VERSION "dbc-export 1 2026.26.6.5"

NS_ :

BS_:

BU_: APP APS BMS CC CMP CMPD CP DAS DI DIF DIR EPBL EPBR EVSE FC GTW HCML HCMR HVP ICR PCS PCS2 PLG PM PMF PMR PTC SCCM SCM SCS SDCR TAS UMC V2G VC VCBATT VCBATT0 VCBATT1 VCBATT2 VCFRONT VCFRONT1 VCFRONT2 VCLEFT VCRIGHT VCSEAT2L VCSEAT2R VCSEC

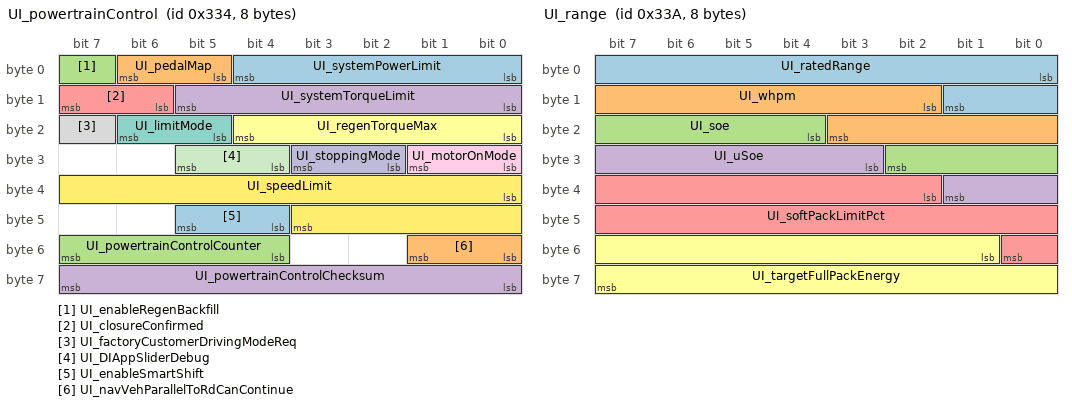
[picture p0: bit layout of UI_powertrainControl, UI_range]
BO_ 820 UI_powertrainControl: 8 GTW
 SG_ UI_systemPowerLimit : 0|5@1+ (20,20) [20|620] "kW" Vector__XXX
 SG_ UI_pedalMap : 5|2@1+ (1,0) [0|3] "" Vector__XXX
 SG_ UI_enableRegenBackfill : 7|1@1+ (1,0) [0|1] "" Vector__XXX
 SG_ UI_systemTorqueLimit : 8|6@1+ (150,1000) [1000|10300] "Nm" Vector__XXX
 SG_ UI_closureConfirmed : 14|2@1+ (1,0) [0|3] "" Vector__XXX
 SG_ UI_regenTorqueMax : 16|5@1+ (5,0) [0|100] "%" Vector__XXX
 SG_ UI_limitMode : 21|2@1+ (1,0) [0|3] "" Vector__XXX
 SG_ UI_factoryCustomerDrivingModeReq : 23|1@1+ (1,0) [0|1] "" Vector__XXX
 SG_ UI_motorOnMode : 24|2@1+ (1,0) [0|3] "" Vector__XXX
 SG_ UI_stoppingMode : 26|2@1+ (1,0) [0|3] "" Vector__XXX
 SG_ UI_DIAppSliderDebug : 28|2@1+ (1,0) [0|3] "" Vector__XXX
 SG_ UI_speedLimit : 32|12@1+ (0.1,0) [0|335] "kph" Vector__XXX
 SG_ UI_enableSmartShift : 44|2@1+ (1,0) [0|3] "" Vector__XXX
 SG_ UI_navVehParallelToRdCanContinue : 48|2@1+ (1,0) [1|3] "" Vector__XXX
 SG_ UI_powertrainControlCounter : 52|4@1+ (1,0) [0|15] "" Vector__XXX
 SG_ UI_powertrainControlChecksum : 56|8@1+ (1,0) [0|255] "" Vector__XXX

BO_ 826 UI_range: 8 GTW
 SG_ UI_ratedRange : 0|10@1+ (1,0) [0|1023] "mi" Vector__XXX
 SG_ UI_whpm : 10|10@1+ (1,0) [0|1023] "" Vector__XXX
 SG_ UI_soe : 20|7@1+ (1,0) [0|127] "%" Vector__XXX
 SG_ UI_uSoe : 27|7@1+ (1,0) [0|127] "%" Vector__XXX
 SG_ UI_softPackLimitPct : 34|15@1+ (0.003051851,0) [0|100.000001717] "%" Vector__XXX
 SG_ UI_targetFullPackEnergy : 49|15@1+ (0.006103702,0) [0|200.000003434] "kWh" Vector__XXX

BO_ 666 UI_seatControl: 3 GTW
 SG_ UI_seatControlIndex M : 0|2@1+ (1,0) [0|3] "" Vector__XXX
 SG_ UI_3RSeatChildLock m0 : 2|2@1+ (1,0) [0|3] "" Vector__XXX
 SG_ UI_2RowLeftSeatTrackBack m0 : 4|1@1+ (1,0) [0|1] "" Vector__XXX
 SG_ UI_2RowLeftSeatTrackForward m0 : 5|1@1+ (1,0) [0|1] "" Vector__XXX
 SG_ UI_2RowRightSeatTrackBack m0 : 6|1@1+ (1,0) [0|1] "" Vector__XXX
 SG_ UI_2RowRightSeatTrackForward m0 : 7|1@1+ (1,0) [0|1] "" Vector__XXX
 SG_ UI_left3RowSeatAdjustmentRequest m0 : 8|3@1+ (1,0) [0|7] "" Vector__XXX
 SG_ UI_right3RowSeatAdjustmentReques m0 : 11|3@1+ (1,0) [0|7] "" Vector__XXX
 SG_ UI_2RLeftSeatFanReq m0 : 14|2@1+ (1,0) [0|3] "" Vector__XXX
 SG_ UI_2RRightSeatFanReq m0 : 16|2@1+ (1,0) [0|3] "" Vector__XXX
 SG_ UI_leftThirdRowSeatRequestFromRe m0 : 18|1@1+ (1,0) [0|1] "" Vector__XXX
 SG_ UI_rightThirdRowSeatRequestFromR m0 : 19|1@1+ (1,0) [0|1] "" Vector__XXX
 SG_ UI_seatChoreographyStopRequest m0 : 20|1@1+ (1,0) [0|1] "" Vector__XXX

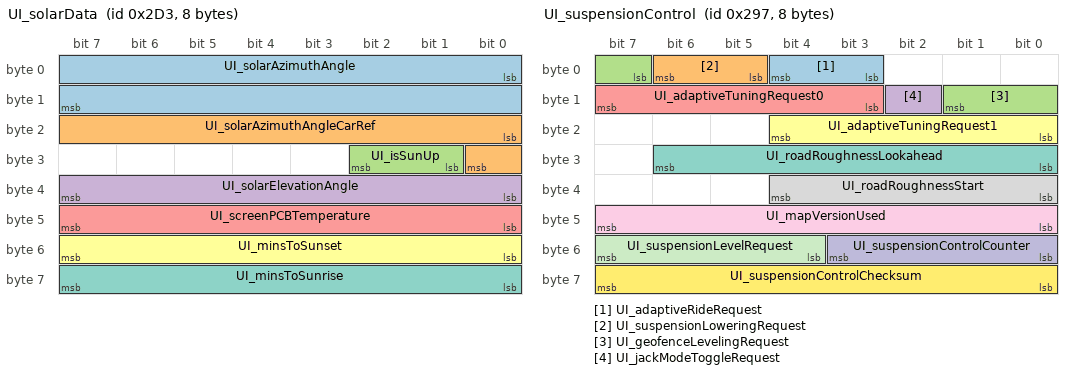
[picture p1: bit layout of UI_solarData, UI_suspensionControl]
BO_ 723 UI_solarData: 8 GTW
 SG_ UI_solarAzimuthAngle : 0|16@1- (1,0) [-32768|32767] "degrees" Vector__XXX
 SG_ UI_solarAzimuthAngleCarRef : 16|9@1- (1,0) [-256|254] "degrees" Vector__XXX
 SG_ UI_isSunUp : 25|2@1+ (1,0) [0|2] "" Vector__XXX
 SG_ UI_solarElevationAngle : 32|8@1- (1,0) [-128|126] "degrees" Vector__XXX
 SG_ UI_screenPCBTemperature : 40|8@1- (0.5,40) [-20|100] "degC" Vector__XXX
 SG_ UI_minsToSunset : 48|8@1+ (10,0) [0|2550] "min" Vector__XXX
 SG_ UI_minsToSunrise : 56|8@1+ (10,0) [0|2550] "min" Vector__XXX

BO_ 851 UI_status: 8 GTW
 SG_ UI_touchActive : 0|1@1+ (1,0) [0|1] "" Vector__XXX
 SG_ UI_audioActive : 1|1@1+ (1,0) [0|1] "" Vector__XXX
 SG_ UI_bluetoothActive : 2|1@1+ (1,0) [0|1] "" Vector__XXX
 SG_ UI_cellActive : 3|1@1+ (1,0) [0|1] "" Vector__XXX
 SG_ UI_displayReady : 4|1@1+ (1,0) [0|1] "" Vector__XXX
 SG_ UI_displayOn : 5|1@1+ (1,0) [0|1] "" Vector__XXX
 SG_ UI_wifiActive : 6|1@1+ (1,0) [0|1] "" Vector__XXX
 SG_ UI_wifiConnected : 7|1@1+ (1,0) [0|1] "" Vector__XXX
 SG_ UI_systemActive : 8|1@1+ (1,0) [0|1] "" Vector__XXX
 SG_ UI_readyForDrive : 9|1@1+ (1,0) [0|1] "" Vector__XXX
 SG_ UI_cellConnected : 10|1@1+ (1,0) [0|1] "" Vector__XXX
 SG_ UI_vpnActive : 11|1@1+ (1,0) [0|1] "" Vector__XXX
 SG_ UI_autopilotTrial : 12|2@1+ (1,0) [0|3] "" Vector__XXX
 SG_ UI_factoryReset : 14|2@1+ (1,0) [1|3] "" Vector__XXX
 SG_ UI_gpsActive : 16|1@1+ (1,0) [0|1] "" Vector__XXX
 SG_ UI_screenshotActive : 17|1@1+ (1,0) [0|1] "" Vector__XXX
 SG_ UI_radioActive : 18|1@1+ (1,0) [0|1] "" Vector__XXX
 SG_ UI_cellNetworkTechnology : 19|4@1+ (1,0) [0|14] "" Vector__XXX
 SG_ UI_cellReceiverPower : 24|8@1+ (1,-128) [-128|127] "dB" Vector__XXX
 SG_ UI_falseTouchCounter : 32|8@1+ (1,0) [0|255] "1" Vector__XXX
 SG_ UI_developmentCar : 40|1@1+ (1,0) [0|1] "" Vector__XXX
 SG_ UI_cameraActive : 41|1@1+ (1,0) [0|1] "" Vector__XXX
 SG_ UI_cellSignalBars : 42|3@1+ (1,0) [0|6] "" Vector__XXX
 SG_ UI_trailerModeTelltale : 45|2@1+ (1,0) [0|3] "" Vector__XXX
 SG_ UI_pcbTemperature : 48|8@1- (1,40) [-20|100] "degC" Vector__XXX
 SG_ UI_cpuTemperature : 56|8@1- (1,40) [-20|100] "degC" Vector__XXX

BO_ 991 UI_status2: 8 GTW
 SG_ UI_mobileAppStepCount : 0|16@1+ (1,0) [0|65535] "" Vector__XXX
 SG_ UI_userRequestSnapshot : 16|1@1+ (1,0) [0|1] "" Vector__XXX
 SG_ UI_touchDetected : 17|1@1+ (1,0) [0|1] "" Vector__XXX
 SG_ UI_validDeviceForEUSummon : 18|1@1+ (1,0) [0|1] "" Vector__XXX
 SG_ UI_locatedAtHome : 19|1@1+ (1,0) [0|1] "" Vector__XXX
 SG_ UI_locatedAtWork : 20|1@1+ (1,0) [0|1] "" Vector__XXX
 SG_ UI_locatedAtFavorite : 21|1@1+ (1,0) [0|1] "" Vector__XXX
 SG_ UI_displayInDarkMode : 22|1@1+ (1,0) [0|1] "" Vector__XXX
 SG_ UI_userActivity : 23|1@1+ (1,0) [0|1] "" Vector__XXX
 SG_ UI_activeTouchPoints : 24|8@1+ (1,0) [0|255] "1" Vector__XXX
 SG_ UI_linkState : 32|2@1+ (1,0) [0|3] "" Vector__XXX
 SG_ UI_sentryModeState : 34|3@1+ (1,0) [0|7] "" Vector__XXX
 SG_ UI_autopilotSentryRequest : 37|1@1+ (1,0) [0|1] "" Vector__XXX
 SG_ UI_mobileAppConnected : 38|1@1+ (1,0) [0|1] "" Vector__XXX
 SG_ UI_phoneLeftInCabin : 39|1@1+ (1,0) [0|1] "" Vector__XXX
 SG_ UI_autoshiftDRState : 40|3@1+ (1,0) [0|7] "" Vector__XXX
 SG_ UI_wifiBtModuleType : 43|3@1+ (1,0) [0|7] "" Vector__XXX
 SG_ UI_sohHealthStatus : 46|2@1+ (1,0) [0|3] "" Vector__XXX
 SG_ UI_selfParkState : 48|8@1+ (1,0) [0|254] "" Vector__XXX
 SG_ UI_summonDeviceIndex : 56|2@1+ (1,0) [0|3] "" Vector__XXX
 SG_ UI_fullScreenMode : 58|1@1+ (1,0) [0|1] "" Vector__XXX
 SG_ UI_sentryModeCameraDetection : 59|1@1+ (1,0) [0|1] "" Vector__XXX
 SG_ UI_wakeOnIPActive : 60|1@1+ (1,0) [0|1] "" Vector__XXX
 SG_ UI_sapActive : 61|1@1+ (1,0) [0|1] "" Vector__XXX
 SG_ UI_sapClients : 62|1@1+ (1,0) [0|1] "" Vector__XXX
 SG_ UI_connectivityStandbyActive : 63|1@1+ (1,0) [0|1] "" Vector__XXX

BO_ 663 UI_suspensionControl: 8 GTW
 SG_ UI_adaptiveRideRequest : 3|2@1+ (1,0) [0|3] "" Vector__XXX
 SG_ UI_suspensionLoweringRequest : 5|2@1+ (1,0) [0|2] "" Vector__XXX
 SG_ UI_geofenceLevelingRequest : 7|3@1+ (1,0) [0|7] "" Vector__XXX
 SG_ UI_jackModeToggleRequest : 10|1@1+ (1,0) [0|1] "" Vector__XXX
 SG_ UI_adaptiveTuningRequest0 : 11|5@1- (0.1,0) [-1.6|1.5] "-" Vector__XXX
 SG_ UI_adaptiveTuningRequest1 : 16|5@1- (0.1,0) [-1.6|1.5] "-" Vector__XXX
 SG_ UI_roadRoughnessLookahead : 24|7@1+ (0.01,0) [0|1.26] "%" Vector__XXX
 SG_ UI_roadRoughnessStart : 32|5@1+ (10,0) [0|300] "m" Vector__XXX
 SG_ UI_mapVersionUsed : 40|8@1+ (1,0) [0|254] "-" Vector__XXX
 SG_ UI_suspensionControlCounter : 48|4@1+ (1,0) [0|15] "" Vector__XXX
 SG_ UI_suspensionLevelRequest : 52|4@1+ (1,0) [0|15] "" Vector__XXX
 SG_ UI_suspensionControlChecksum : 56|8@1+ (1,0) [0|255] "" Vector__XXX

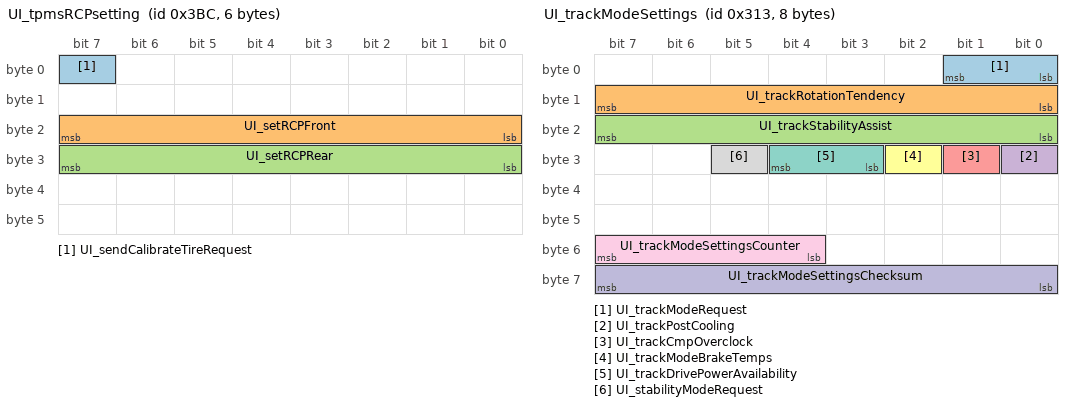
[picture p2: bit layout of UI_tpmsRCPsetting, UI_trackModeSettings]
BO_ 956 UI_tpmsRCPsetting: 6 GTW
 SG_ UI_sendCalibrateTireRequest : 7|1@1+ (1,0) [0|1] "" Vector__XXX
 SG_ UI_setRCPFront : 16|8@1+ (0.025,0) [0|6.375] "bar" Vector__XXX
 SG_ UI_setRCPRear : 24|8@1+ (0.025,0) [0|6.375] "bar" Vector__XXX

BO_ 787 UI_trackModeSettings: 8 GTW
 SG_ UI_trackModeRequest : 0|2@1+ (1,0) [0|3] "" Vector__XXX
 SG_ UI_trackRotationTendency : 8|8@1+ (0.5,0) [0|127.5] "%" Vector__XXX
 SG_ UI_trackStabilityAssist : 16|8@1+ (0.5,0) [0|127.5] "%" Vector__XXX
 SG_ UI_trackPostCooling : 24|1@1+ (1,0) [0|1] "" Vector__XXX
 SG_ UI_trackCmpOverclock : 25|1@1+ (1,0) [0|1] "" Vector__XXX
 SG_ UI_trackModeBrakeTemps : 26|1@1+ (1,0) [0|1] "" Vector__XXX
 SG_ UI_trackDrivePowerAvailability : 27|2@1+ (1,0) [0|3] "" Vector__XXX
 SG_ UI_stabilityModeRequest : 29|1@1+ (1,0) [0|1] "" Vector__XXX
 SG_ UI_trackModeSettingsCounter : 52|4@1+ (1,0) [0|15] "" Vector__XXX
 SG_ UI_trackModeSettingsChecksum : 56|8@1+ (1,0) [0|255] "" Vector__XXX

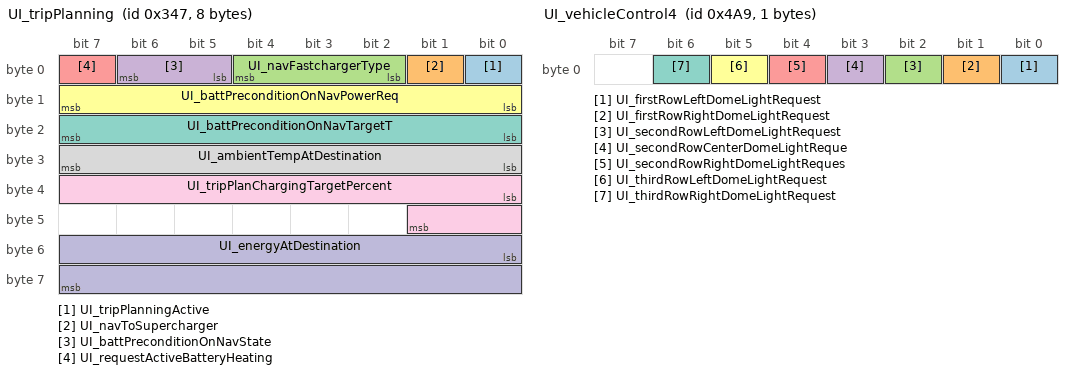
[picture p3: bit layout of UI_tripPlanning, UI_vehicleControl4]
BO_ 839 UI_tripPlanning: 8 GTW
 SG_ UI_tripPlanningActive : 0|1@1+ (1,0) [0|1] "" Vector__XXX
 SG_ UI_navToSupercharger : 1|1@1+ (1,0) [0|1] "" Vector__XXX
 SG_ UI_navFastchargerType : 2|3@1+ (1,0) [0|7] "" Vector__XXX
 SG_ UI_battPreconditionOnNavState : 5|2@1+ (1,0) [0|3] "" Vector__XXX
 SG_ UI_requestActiveBatteryHeating : 7|1@1+ (1,0) [0|1] "" Vector__XXX
 SG_ UI_battPreconditionOnNavPowerReq : 8|8@1- (125,0) [-16000|15750] "W" Vector__XXX
 SG_ UI_battPreconditionOnNavTargetT : 16|8@1+ (0.25,0) [0|63.5] "degC" Vector__XXX
 SG_ UI_ambientTempAtDestination : 24|8@1- (0.5,0) [-64|63.5] "degC" Vector__XXX
 SG_ UI_tripPlanChargingTargetPercent : 32|10@1+ (0.1,0) [0|102.2] "%" Vector__XXX
 SG_ UI_energyAtDestination : 48|16@1- (0.01,0) [-327.67|327.67] "kWh" Vector__XXX

BO_ 627 UI_vehicleControl: 8 GTW
 SG_ UI_powerStateRequest : 0|2@1+ (1,0) [0|3] "" Vector__XXX
 SG_ UI_childDoorLockOnRight : 2|1@1+ (1,0) [0|1] "" Vector__XXX
 SG_ UI_frontFogSwitch : 3|1@1+ (1,0) [0|1] "" Vector__XXX
 SG_ UI_summonActive : 4|1@1+ (1,0) [0|1] "" Vector__XXX
 SG_ UI_frunkRequest : 5|1@1+ (1,0) [0|1] "" Vector__XXX
 SG_ UI_wiperMode : 6|2@1+ (1,0) [1|3] "" Vector__XXX
 SG_ UI_steeringBacklightEnabled : 8|1@1+ (1,0) [0|1] "" Vector__XXX
 SG_ UI_steeringButtonMode : 9|3@1+ (1,0) [0|7] "" Vector__XXX
 SG_ UI_walkUpUnlock : 12|1@1+ (1,0) [0|1] "" Vector__XXX
 SG_ UI_walkAwayLock : 13|1@1+ (1,0) [0|1] "" Vector__XXX
 SG_ UI_unlockOnPark : 14|1@1+ (1,0) [0|1] "" Vector__XXX
 SG_ UI_globalUnlockOn : 15|1@1+ (1,0) [0|1] "" Vector__XXX
 SG_ UI_childDoorLockOnLeft : 16|1@1+ (1,0) [0|1] "" Vector__XXX
 SG_ UI_lockRequest : 17|3@1+ (1,0) [0|6] "" Vector__XXX
 SG_ UI_alarmEnabled : 20|1@1+ (1,0) [0|1] "" Vector__XXX
 SG_ UI_intrusionSensorOn : 21|1@1+ (1,0) [0|1] "" Vector__XXX
 SG_ UI_stop12vSupport : 22|1@1+ (1,0) [0|1] "" Vector__XXX
 SG_ UI_rearFogSwitch : 23|1@1+ (1,0) [0|1] "" Vector__XXX
 SG_ UI_mirrorFoldRequest : 24|2@1+ (1,0) [0|2] "" Vector__XXX
 SG_ UI_mirrorHeatRequest : 26|1@1+ (1,0) [0|1] "" Vector__XXX
 SG_ UI_remoteStartRequest : 27|3@1+ (1,0) [0|7] "" Vector__XXX
 SG_ UI_seeYouHomeLightingOn : 30|1@1+ (1,0) [0|1] "" Vector__XXX
 SG_ UI_powerOff : 31|1@1+ (1,0) [0|1] "" Vector__XXX
 SG_ UI_displayBrightnessLevel : 32|8@1+ (0.5,0) [0|127] "%" Vector__XXX
 SG_ UI_ambientLightingEnabled : 40|1@1+ (1,0) [0|1] "" Vector__XXX
 SG_ UI_autoHighBeamEnabled : 41|1@1+ (1,0) [0|1] "" Vector__XXX
 SG_ UI_frontLeftSeatHeatReq : 42|2@1+ (1,0) [0|3] "" Vector__XXX
 SG_ UI_frontRightSeatHeatReq : 44|2@1+ (1,0) [0|3] "" Vector__XXX
 SG_ UI_rearLeftSeatHeatReq : 46|2@1+ (1,0) [0|3] "" Vector__XXX
 SG_ UI_rearCenterSeatHeatReq : 48|2@1+ (1,0) [0|3] "" Vector__XXX
 SG_ UI_rearRightSeatHeatReq : 50|2@1+ (1,0) [0|3] "" Vector__XXX
 SG_ UI_autoFoldMirrorsOn : 52|1@1+ (1,0) [0|1] "" Vector__XXX
 SG_ UI_mirrorDipOnReverse : 53|1@1+ (1,0) [0|1] "" Vector__XXX
 SG_ UI_remoteClosureRequest : 54|2@1+ (1,0) [0|2] "" Vector__XXX
 SG_ UI_wiperRequest : 56|3@1+ (1,0) [1|7] "" Vector__XXX
 SG_ UI_domeLightSwitch : 59|2@1+ (1,0) [0|3] "" Vector__XXX
 SG_ UI_honkHorn : 61|1@1+ (1,0) [0|1] "" Vector__XXX
 SG_ UI_driveStateRequest : 62|1@1+ (1,0) [0|1] "" Vector__XXX
 SG_ UI_rearWindowLockout : 63|1@1+ (1,0) [0|1] "" Vector__XXX

BO_ 947 UI_vehicleControl2: 8 GTW
 SG_ UI_gloveboxRequest : 0|1@1+ (1,0) [0|1] "" Vector__XXX
 SG_ UI_trunkRequest : 1|1@1+ (1,0) [0|1] "" Vector__XXX
 SG_ UI_UMCUpdateInhibit : 2|1@1+ (1,0) [0|1] "" Vector__XXX
 SG_ UI_WCUpdateInhibit : 3|1@1+ (1,0) [0|1] "" Vector__XXX
 SG_ UI_soundHornOnLock : 4|1@1+ (1,0) [0|1] "" Vector__XXX
 SG_ UI_locksPanelActive : 5|1@1+ (1,0) [0|1] "" Vector__XXX
 SG_ UI_PINToDriveEnabled : 6|1@1+ (1,0) [0|1] "" Vector__XXX
 SG_ UI_PINToDrivePassed : 7|1@1+ (1,0) [0|1] "" Vector__XXX
 SG_ UI_disableMirrorAutoDim : 8|1@1+ (1,0) [0|1] "" Vector__XXX
 SG_ UI_lightSwitch : 9|3@1+ (1,0) [0|7] "" Vector__XXX
 SG_ UI_readyToAddKey : 12|1@1+ (1,0) [0|1] "" Vector__XXX
 SG_ UI_alarmTriggerRequest : 13|1@1+ (1,0) [0|1] "" Vector__XXX
 SG_ UI_VCSECFeature1 : 14|1@1+ (1,0) [0|1] "" Vector__XXX
 SG_ UI_VCLEFTFeature1 : 15|1@1+ (1,0) [0|1] "" Vector__XXX
 SG_ UI_summonState : 16|2@1+ (1,0) [1|3] "" Vector__XXX
 SG_ UI_displayOnForUser : 18|1@1+ (1,0) [0|1] "" Vector__XXX
 SG_ UI_freeRollModeRequest : 19|1@1+ (1,0) [0|1] "" Vector__XXX
 SG_ UI_BLEPushNotificationRequest : 20|1@1+ (1,0) [0|1] "" Vector__XXX
 SG_ UI_pairKeyQRCodeDisplaying : 21|1@1+ (1,0) [0|1] "" Vector__XXX
 SG_ UI_keepAutopilotAwake : 22|1@1+ (1,0) [0|1] "" Vector__XXX
 SG_ UI_batteryPreconditioningRequest : 23|1@1+ (1,0) [0|1] "" Vector__XXX
 SG_ UI_coastDownMode : 24|1@1+ (1,0) [0|1] "" Vector__XXX
 SG_ UI_autopilotPowerStateRequest : 25|2@1+ (1,0) [0|3] "" Vector__XXX
 SG_ UI_shorted12VCellTestMode : 27|2@1+ (1,0) [0|3] "" Vector__XXX
 SG_ UI_autoRollWindowsOnLockEnable : 29|1@1+ (1,0) [0|1] "" Vector__XXX
 SG_ UI_virtualPitchSensorOverrideOKF : 30|1@1+ (1,0) [0|1] "" Vector__XXX
 SG_ UI_conditionalLoggingEnabledVCSE : 31|1@1+ (1,0) [0|1] "" Vector__XXX
 SG_ UI_WC3UpdateInhibit : 32|1@1+ (1,0) [0|1] "" Vector__XXX
 SG_ UI_steeringWheelHeatReq : 33|1@1+ (1,0) [0|1] "" Vector__XXX
 SG_ UI_disableHorn : 34|1@1+ (1,0) [0|1] "" Vector__XXX
 SG_ UI_frontLeftSeatFanReq : 37|2@1+ (1,0) [0|3] "" Vector__XXX
 SG_ UI_frontRightSeatAutoClimateReq : 39|1@1+ (1,0) [0|1] "" Vector__XXX
 SG_ UI_frontRightSeatFanReq : 40|2@1+ (1,0) [0|3] "" Vector__XXX
 SG_ UI_3RLeftSeatHeatReq : 44|2@1+ (1,0) [0|3] "" Vector__XXX
 SG_ UI_3RRightSeatHeatReq : 46|2@1+ (1,0) [0|3] "" Vector__XXX
 SG_ UI_sleepFeature1 : 51|1@1+ (1,0) [0|1] "" Vector__XXX
 SG_ UI_dcr12VThreshold : 52|4@1+ (1,0) [0|15] "" Vector__XXX
 SG_ UI_frontLeftSeatAutoClimateReq : 56|1@1+ (1,0) [0|1] "" Vector__XXX
 SG_ UI_wiperHeaterReq : 57|1@1+ (1,0) [0|1] "" Vector__XXX
 SG_ UI_tireSeason : 59|1@1+ (1,0) [0|1] "" Vector__XXX
 SG_ UI_saveTireConfigReq : 60|1@1+ (1,0) [0|1] "" Vector__XXX
 SG_ UI_silentAlarm : 61|1@1+ (1,0) [0|1] "" Vector__XXX
 SG_ UI_sleepFeature2 : 63|1@1+ (1,0) [0|1] "" Vector__XXX

BO_ 660 UI_vehicleControl3: 8 GTW
 SG_ UI_lightFlashRequest : 0|2@1+ (1,0) [0|3] "" Vector__XXX
 SG_ UI_keylessDrivingEnabled : 2|1@1+ (1,0) [0|1] "" Vector__XXX
 SG_ UI_phoneCallActive : 3|1@1+ (1,0) [0|1] "" Vector__XXX
 SG_ UI_drivingSideVEH : 4|2@1+ (1,0) [0|3] "" Vector__XXX
 SG_ UI_keyPairResponse : 6|2@1+ (1,0) [0|3] "" Vector__XXX
 SG_ UI_lightShowClosuresEnabled : 8|1@1+ (1,0) [0|1] "" Vector__XXX
 SG_ UI_steeringWheelHeatAutoReq : 9|1@1+ (1,0) [0|1] "" Vector__XXX
 SG_ UI_steeringWheelHeatLevelReq : 10|2@1+ (1,0) [0|3] "" Vector__XXX
 SG_ UI_headlightPulseRequest : 12|1@1+ (1,0) [0|1] "" Vector__XXX
 SG_ UI_VCSECFeature2 : 13|1@1+ (1,0) [0|1] "" Vector__XXX
 SG_ UI_VCSECFeature3 : 14|1@1+ (1,0) [0|1] "" Vector__XXX
 SG_ UI_VCSECFeature4 : 15|1@1+ (1,0) [0|1] "" Vector__XXX
 SG_ UI_VCSECFeature5 : 16|1@1+ (1,0) [0|1] "" Vector__XXX
 SG_ UI_shortHornRequest : 17|1@1+ (1,0) [0|1] "" Vector__XXX
 SG_ UI_packTempLoggingRequest : 18|1@1+ (1,0) [0|1] "" Vector__XXX
 SG_ UI_UMC3UpdateInhibit : 22|1@1+ (1,0) [0|1] "" Vector__XXX
 SG_ UI_handsFreeTrunk : 23|1@1+ (1,0) [0|1] "" Vector__XXX
 SG_ UI_displayRedShiftActive : 24|1@1+ (1,0) [0|1] "" Vector__XXX
 SG_ UI_handsFreeFrunk : 25|1@1+ (1,0) [0|1] "" Vector__XXX
 SG_ UI_fasciaCameraWashRequest : 26|1@1+ (1,0) [0|1] "" Vector__XXX
 SG_ UI_autoClosuresExcludeHome : 27|1@1+ (1,0) [0|1] "" Vector__XXX
 SG_ UI_leftRearSeatAdjustmentRequest : 28|3@1+ (1,0) [0|7] "" Vector__XXX
 SG_ UI_rightRearSeatAdjustmentReques : 32|3@1+ (1,0) [0|7] "" Vector__XXX
 SG_ UI_blindSpotIndicatorLightReques : 35|1@1+ (1,0) [0|1] "" Vector__XXX
 SG_ UI_etcBluetoothControl : 36|2@1+ (1,0) [0|3] "" Vector__XXX
 SG_ UI_keepOnAccessoryPortsReq : 38|1@1+ (1,0) [0|1] "" Vector__XXX
 SG_ UI_fasciaCameraShown : 39|1@1+ (1,0) [0|1] "" Vector__XXX
 SG_ UI_rearSeatChildLock : 40|2@1+ (1,0) [0|3] "" Vector__XXX
 SG_ UI_windowPercentageRequest : 42|6@1- (5,0) [-100|100] "%" Vector__XXX
 SG_ UI_windowRequestedFL : 48|1@1+ (1,0) [0|1] "" Vector__XXX
 SG_ UI_windowRequestedFR : 49|1@1+ (1,0) [0|1] "" Vector__XXX
 SG_ UI_windowRequestedRL : 50|1@1+ (1,0) [0|1] "" Vector__XXX
 SG_ UI_windowRequestedRR : 51|1@1+ (1,0) [0|1] "" Vector__XXX
 SG_ UI_windowRequest : 52|3@1+ (1,0) [0|7] "" Vector__XXX
 SG_ UI_closeTrunkRequest : 55|1@1+ (1,0) [0|1] "" Vector__XXX
 SG_ UI_childPresenceDetectionDisable : 56|1@1+ (1,0) [0|1] "" Vector__XXX
 SG_ UI_V2LAUpdateInhibit : 57|1@1+ (1,0) [0|1] "" Vector__XXX
 SG_ UI_userPresenceDetectionEnabled : 58|1@1+ (1,0) [0|1] "" Vector__XXX
 SG_ UI_derivedLoadshedFeature : 59|1@1+ (1,0) [0|1] "" Vector__XXX
 SG_ UI_rearSeatFoldConfirmed : 60|1@1+ (1,0) [0|1] "" Vector__XXX
 SG_ UI_leftRearSeatRequestFromRearDi : 61|1@1+ (1,0) [0|1] "" Vector__XXX
 SG_ UI_selfParkStandingBy : 62|1@1+ (1,0) [0|1] "" Vector__XXX
 SG_ UI_rightRearSeatRequestFromRearD : 63|1@1+ (1,0) [0|1] "" Vector__XXX

BO_ 1193 UI_vehicleControl4: 1 GTW
 SG_ UI_firstRowLeftDomeLightRequest : 0|1@1+ (1,0) [0|1] "" Vector__XXX
 SG_ UI_firstRowRightDomeLightRequest : 1|1@1+ (1,0) [0|1] "" Vector__XXX
 SG_ UI_secondRowLeftDomeLightRequest : 2|1@1+ (1,0) [0|1] "" Vector__XXX
 SG_ UI_secondRowCenterDomeLightReque : 3|1@1+ (1,0) [0|1] "" Vector__XXX
 SG_ UI_secondRowRightDomeLightReques : 4|1@1+ (1,0) [0|1] "" Vector__XXX
 SG_ UI_thirdRowLeftDomeLightRequest : 5|1@1+ (1,0) [0|1] "" Vector__XXX
 SG_ UI_thirdRowRightDomeLightRequest : 6|1@1+ (1,0) [0|1] "" Vector__XXX

BO_ 853 UI_vehicleControlThermal: 7 GTW
 SG_ UI_coolantFlowRequest : 0|5@1+ (1,0) [0|25] "LPM" Vector__XXX
 SG_ UI_inletActiveCoolTarget : 5|7@1+ (1,0) [0|127] "degC" Vector__XXX
 SG_ UI_disableHVPTThermalLoads : 12|1@1+ (1,0) [0|1] "" Vector__XXX
 SG_ UI_enableCompLiquidPumpOut : 13|1@1+ (1,0) [0|1] "" Vector__XXX
 SG_ UI_enableCOP1HighSHOperation : 14|1@1+ (1,0) [0|1] "" Vector__XXX
 SG_ UI_enableIncreasedEvapRampRate : 15|1@1+ (1,0) [0|1] "" Vector__XXX
 SG_ UI_enableCOP1BatteryHeating : 16|1@1+ (1,0) [0|1] "" Vector__XXX
 SG_ UI_enableCOP1CabinHeatingBattery : 17|1@1+ (1,0) [0|1] "" Vector__XXX
 SG_ UI_enableLouverAutoDetection : 18|1@1+ (1,0) [0|1] "" Vector__XXX
 SG_ UI_enableUserFacingLowFlowDelive : 19|1@1+ (1,0) [0|1] "" Vector__XXX
 SG_ UI_disableHvacCameraOnlyDefog : 20|1@1+ (1,0) [0|1] "" Vector__XXX
 SG_ UI_enableEXVFastCalibration : 21|1@1+ (1,0) [0|1] "" Vector__XXX
 SG_ UI_enableThermalDriverlessSelfTe : 22|1@1+ (1,0) [0|1] "" Vector__XXX
 SG_ UI_enableCoolantDasTarget : 23|1@1+ (1,0) [0|1] "" Vector__XXX
 SG_ UI_geofencedLiftgateHeight : 24|8@1+ (1,0) [0|254] "cm" Vector__XXX
 SG_ UI_convenienceFeatureLimit : 32|7@1+ (1,0) [0|127] "%" Vector__XXX
 SG_ UI_allowConvenienceFeatures : 39|1@1+ (1,0) [0|1] "" Vector__XXX
 SG_ UI_enableConservativeBatteryHeat : 40|1@1+ (1,0) [0|1] "" Vector__XXX
 SG_ UI_enableDefaultApTempTarget : 41|1@1+ (1,0) [0|1] "" Vector__XXX
 SG_ UI_enableHVACCompressorWasteHeat : 42|1@1+ (1,0) [0|1] "" Vector__XXX
 SG_ UI_disablePhoneChargingPads : 43|1@1+ (1,0) [0|1] "" Vector__XXX
 SG_ UI_isAtTeslaFacility : 45|1@1+ (1,0) [0|1] "" Vector__XXX
 SG_ UI_enableThermalPowerBudget : 46|1@1+ (1,0) [0|1] "" Vector__XXX
 SG_ UI_enableHVACAPFanHeaterControl : 48|1@1+ (1,0) [0|1] "" Vector__XXX
 SG_ UI_enableAutopilotAirPurge : 49|1@1+ (1,0) [0|1] "" Vector__XXX
 SG_ UI_enableForcedAirCameraHeater : 50|1@1+ (1,0) [0|1] "" Vector__XXX
 SG_ UI_enableHvacCOPOnUndeliveredVeh : 51|1@1+ (1,0) [0|1] "" Vector__XXX

BO_ 644 UI_vehicleModes: 8 GTW
 SG_ UI_factoryMode : 0|1@1+ (1,0) [0|1] "" Vector__XXX
 SG_ UI_transportMode : 1|1@1+ (1,0) [0|1] "" Vector__XXX
 SG_ UI_showroomMode : 2|1@1+ (1,0) [0|1] "" Vector__XXX
 SG_ UI_serviceMode : 3|1@1+ (1,0) [0|1] "" Vector__XXX
 SG_ UI_isDelivered : 4|1@1+ (1,0) [0|1] "" Vector__XXX
 SG_ UI_hasEverBeenDelivered : 5|1@1+ (1,0) [0|1] "" Vector__XXX
 SG_ UI_homelinkV2Command0 : 8|8@1+ (1,0) [0|255] "" Vector__XXX
 SG_ UI_homelinkV2Command1 : 16|8@1+ (1,0) [0|255] "" Vector__XXX
 SG_ UI_homelinkV2Command2 : 24|8@1+ (1,0) [0|255] "" Vector__XXX
 SG_ UI_carWashMode : 32|1@1+ (1,0) [0|1] "" Vector__XXX
 SG_ UI_valetMode : 33|1@1+ (1,0) [0|1] "" Vector__XXX
 SG_ UI_gameMode : 34|1@1+ (1,0) [0|1] "" Vector__XXX
 SG_ UI_diagnosticsAllowed : 35|1@1+ (1,0) [0|1] "" Vector__XXX
 SG_ UI_serviceModePlus : 36|1@1+ (1,0) [0|1] "" Vector__XXX
 SG_ UI_premiumAmpPowerOff : 37|1@1+ (1,0) [0|1] "" Vector__XXX
 SG_ UI_signedCmdHardLocked : 38|1@1+ (1,0) [0|1] "" Vector__XXX
 SG_ UI_signedCmdServiceMode : 39|1@1+ (1,0) [0|1] "" Vector__XXX
 SG_ UI_closureEasterEggStatus : 40|2@1+ (1,0) [0|3] "" Vector__XXX
 SG_ UI_lightShowType : 42|3@1+ (1,0) [0|7] "" Vector__XXX
 SG_ UI_sohTestRequest : 45|1@1+ (1,0) [0|1] "" Vector__XXX
 SG_ UI_upkeepMode : 46|1@1+ (1,0) [0|1] "" Vector__XXX
 SG_ UI_vehicleModesCounter : 52|4@1+ (1,0) [0|15] "" Vector__XXX
 SG_ UI_vehicleModesChecksum : 56|8@1+ (1,0) [0|255] "" Vector__XXX

BO_ 595 UI_ventPanelControlRequest: 8 GTW
 SG_ UI_ventPanelControlRequestIndex M : 0|1@1+ (1,0) [0|1] "" Vector__XXX
 SG_ UI_ventPanelLeftPositionX m0 : 8|8@1+ (0.5,0) [0|100] "%" Vector__XXX
 SG_ UI_ventPanelLeftPositionY m0 : 16|8@1+ (0.5,0) [0|100] "%" Vector__XXX
 SG_ UI_ventPanelLeftLateralSplit m0 : 24|8@1+ (0.5,0) [0|100] "%" Vector__XXX
 SG_ UI_ventPanelRightPositionX m0 : 32|8@1+ (0.5,0) [0|100] "%" Vector__XXX
 SG_ UI_ventPanelRightPositionY m0 : 40|8@1+ (0.5,0) [0|100] "%" Vector__XXX
 SG_ UI_ventPanelRightLateralSplit m0 : 48|8@1+ (0.5,0) [0|100] "%" Vector__XXX
 SG_ UI_ventPanelLeftLateralMode m0 : 56|2@1+ (1,0) [0|3] "" Vector__XXX
 SG_ UI_ventPanelRightLateralMode m0 : 58|2@1+ (1,0) [0|3] "" Vector__XXX
 SG_ UI_hvacReqActiveVents m0 : 60|2@1+ (1,0) [0|3] "" Vector__XXX
 SG_ UI_vent2RLeftPositionX m1 : 8|8@1+ (0.5,0) [0|100] "%" Vector__XXX
 SG_ UI_vent2RLeftPositionY m1 : 16|8@1+ (0.5,0) [0|100] "%" Vector__XXX
 SG_ UI_vent2RRightPositionX m1 : 24|8@1+ (0.5,0) [0|100] "%" Vector__XXX
 SG_ UI_vent2RRightPositionY m1 : 32|8@1+ (0.5,0) [0|100] "%" Vector__XXX
 SG_ UI_hvacReqThirdRowState m1 : 40|2@1+ (1,0) [0|3] "" Vector__XXX

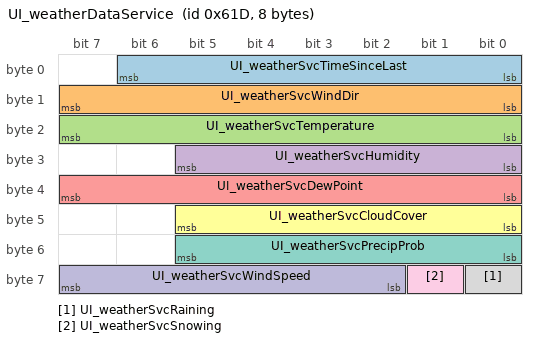
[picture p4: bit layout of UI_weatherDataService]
BO_ 1565 UI_weatherDataService: 8 GTW
 SG_ UI_weatherSvcTimeSinceLast : 0|7@1+ (1,0) [0|126] "minutes" Vector__XXX
 SG_ UI_weatherSvcWindDir : 8|8@1+ (1.5,0) [0|381] "deg" Vector__XXX
 SG_ UI_weatherSvcTemperature : 16|8@1+ (0.5,-40) [-40|87] "degC" Vector__XXX
 SG_ UI_weatherSvcHumidity : 24|6@1+ (1.62,0) [0|100.44] "%" Vector__XXX
 SG_ UI_weatherSvcDewPoint : 32|8@1+ (0.5,-60) [-60|67] "degC" Vector__XXX
 SG_ UI_weatherSvcCloudCover : 40|6@1+ (1.62,0) [0|100.44] "%" Vector__XXX
 SG_ UI_weatherSvcPrecipProb : 48|6@1+ (1.62,0) [0|100.44] "%" Vector__XXX
 SG_ UI_weatherSvcRaining : 56|1@1+ (1,0) [0|1] "" Vector__XXX
 SG_ UI_weatherSvcSnowing : 57|1@1+ (1,0) [0|1] "" Vector__XXX
 SG_ UI_weatherSvcWindSpeed : 58|6@1+ (2,0) [0|124] "kph" Vector__XXX

BO_ 1969 UI_weatherDataServiceForecast: 8 GTW
 SG_ UI_weatherSvcForecastMuxIndex M : 0|3@1+ (1,0) [0|7] "" Vector__XXX
 SG_ UI_weatherSvcForecastTempC_hour1 m0 : 8|8@1+ (0.5,-40) [-40|87] "C" Vector__XXX
 SG_ UI_weatherSvcForecastTempC_hour2 m0 : 16|8@1+ (0.5,-40) [-40|87] "C" Vector__XXX
 SG_ UI_weatherSvcForecastTempC_hour3 m0 : 24|8@1+ (0.5,-40) [-40|87] "C" Vector__XXX
 SG_ UI_weatherSvcForecastTempC_hour4 m0 : 32|8@1+ (0.5,-40) [-40|87] "C" Vector__XXX
 SG_ UI_weatherSvcForecastTempC_hour5 m0 : 40|8@1+ (0.5,-40) [-40|87] "C" Vector__XXX
 SG_ UI_weatherSvcForecastTempC_hour6 m0 : 48|8@1+ (0.5,-40) [-40|87] "C" Vector__XXX
 SG_ UI_weatherSvcForecastTempC_hour7 m0 : 56|8@1+ (0.5,-40) [-40|87] "C" Vector__XXX
 SG_ UI_weatherSvcForecastTempC_hour8 m1 : 8|8@1+ (0.5,-40) [-40|87] "C" Vector__XXX
 SG_ UI_weatherSvcForecastTempC_hour9 m1 : 16|8@1+ (0.5,-40) [-40|87] "C" Vector__XXX
 SG_ UI_weatherSvcForecastTempC__0001 m1 : 24|8@1+ (0.5,-40) [-40|87] "C" Vector__XXX
 SG_ UI_weatherSvcForecastTempC__0002 m1 : 32|8@1+ (0.5,-40) [-40|87] "C" Vector__XXX
 SG_ UI_weatherSvcForecastHumidity_ho m1 : 40|6@1+ (1.62,0) [0|100.44] "%" Vector__XXX
 SG_ UI_weatherSvcForecastHumidi_0003 m1 : 48|6@1+ (1.62,0) [0|100.44] "%" Vector__XXX
 SG_ UI_weatherSvcForecastHumidi_0004 m1 : 56|6@1+ (1.62,0) [0|100.44] "%" Vector__XXX
 SG_ UI_weatherSvcForecastHumidi_0005 m2 : 8|6@1+ (1.62,0) [0|100.44] "%" Vector__XXX
 SG_ UI_weatherSvcForecastHumidi_0006 m2 : 16|6@1+ (1.62,0) [0|100.44] "%" Vector__XXX
 SG_ UI_weatherSvcForecastHumidi_0007 m2 : 24|6@1+ (1.62,0) [0|100.44] "%" Vector__XXX
 SG_ UI_weatherSvcForecastHumidi_0008 m2 : 32|6@1+ (1.62,0) [0|100.44] "%" Vector__XXX
 SG_ UI_weatherSvcForecastHumidi_0009 m2 : 40|6@1+ (1.62,0) [0|100.44] "%" Vector__XXX
 SG_ UI_weatherSvcForecastHumidi_0010 m2 : 48|6@1+ (1.62,0) [0|100.44] "%" Vector__XXX
 SG_ UI_weatherSvcForecastHumidi_0001 m2 : 56|6@1+ (1.62,0) [0|100.44] "%" Vector__XXX
 SG_ UI_weatherSvcForecastHumidi_0002 m3 : 8|6@1+ (1.62,0) [0|100.44] "%" Vector__XXX
 SG_ UI_weatherSvcForecastWindSpeedKp m3 : 16|6@1+ (2,0) [0|124] "kph" Vector__XXX
 SG_ UI_weatherSvcForecastWindSp_0003 m3 : 24|6@1+ (2,0) [0|124] "kph" Vector__XXX
 SG_ UI_weatherSvcForecastWindSp_0004 m3 : 32|6@1+ (2,0) [0|124] "kph" Vector__XXX
 SG_ UI_weatherSvcForecastWindSp_0005 m3 : 40|6@1+ (2,0) [0|124] "kph" Vector__XXX
 SG_ UI_weatherSvcForecastWindSp_0006 m3 : 48|6@1+ (2,0) [0|124] "kph" Vector__XXX
 SG_ UI_weatherSvcForecastWindSp_0007 m3 : 56|6@1+ (2,0) [0|124] "kph" Vector__XXX
 SG_ UI_weatherSvcForecastWindSp_0008 m4 : 8|6@1+ (2,0) [0|124] "kph" Vector__XXX
 SG_ UI_weatherSvcForecastWindSp_0009 m4 : 16|6@1+ (2,0) [0|124] "kph" Vector__XXX
 SG_ UI_weatherSvcForecastWindSp_0010 m4 : 24|6@1+ (2,0) [0|124] "kph" Vector__XXX
 SG_ UI_weatherSvcForecastWindSp_0001 m4 : 32|6@1+ (2,0) [0|124] "kph" Vector__XXX
 SG_ UI_weatherSvcForecastWindSp_0002 m4 : 40|6@1+ (2,0) [0|124] "kph" Vector__XXX

BO_ 1533 UMC_alertLog: 8 UMC
 SG_ UMC_alertID M : 0|15@1+ (1,0) [0|32767] "" Vector__XXX
 SG_ UMC_alertType : 15|1@1+ (1,0) [0|1] "" Vector__XXX
 SG_ UMC_a001_groundImpedance m1 : 32|32@1+ (1,0) [0|4294967295] "Ohm" Vector__XXX
 SG_ UMC_a002_ccidRmsCurrent m2 : 16|12@1+ (0.001,0) [0|4.095] "A" Vector__XXX
 SG_ UMC_a002_ccidRmsCurrentAvg m2 : 28|12@1+ (0.001,0) [0|4.095] "A" Vector__XXX
 SG_ UMC_a002_ccidDCGfciCurrent m2 : 40|10@1- (0.001,0) [-0.512|0.511] "A" Vector__XXX
 SG_ UMC_a002_ccidFaultReason m2 : 50|4@1+ (1,0) [1|15] "" Vector__XXX
 SG_ UMC_a002_ccidFaultBucket m2 : 54|4@1+ (1,0) [0|15] "" Vector__XXX
 SG_ UMC_a003_faultType m3 : 16|8@1+ (1,0) [0|255] "" Vector__XXX
 SG_ UMC_a003_ccidSelfTestDuty m3 : 24|16@1+ (0.0001,50) [50|56.5535] "A" Vector__XXX
 SG_ UMC_a003_ccidSelfTestCurrent m3 : 40|16@1+ (0.0001,0) [0|6.5535] "A" Vector__XXX
 SG_ UMC_a004_lineVoltage m4 : 16|16@1+ (1,0) [0|65535] "Vrms" Vector__XXX
 SG_ UMC_a004_inputVoltage m4 : 32|16@1+ (0.01,0) [0|655.35] "V" Vector__XXX
 SG_ UMC_a004_inputNeutralVoltage m4 : 48|16@1+ (0.01,0) [0|655.35] "V" Vector__XXX
 SG_ UMC_a005_lineVoltage m5 : 16|16@1+ (1,0) [0|65535] "Vrms" Vector__XXX
 SG_ UMC_a005_inputVoltage m5 : 32|16@1+ (0.01,0) [0|655.35] "V" Vector__XXX
 SG_ UMC_a005_inputNeutralVoltage m5 : 48|16@1+ (0.01,0) [0|655.35] "V" Vector__XXX
 SG_ UMC_a006_outputVoltage m6 : 16|16@1+ (1,0) [0|65535] "Vrms" Vector__XXX
 SG_ UMC_a006_faultType m6 : 32|4@1+ (1,0) [0|15] "" Vector__XXX
 SG_ UMC_a006_umcReceptacleVoltage m6 : 36|12@1+ (0.1,0) [0|409.5] "V" Vector__XXX
 SG_ UMC_a006_handleVoltage m6 : 48|12@1+ (0.1,0) [0|409.5] "V" Vector__XXX
 SG_ UMC_a006_line1StuckClosed m6 : 60|1@1+ (1,0) [0|1] "" Vector__XXX
 SG_ UMC_a006_line2StuckClosed m6 : 61|1@1+ (1,0) [0|1] "" Vector__XXX
 SG_ UMC_a007_pcbaTemp m7 : 16|16@1+ (1,0) [0|65535] "degC" Vector__XXX
 SG_ UMC_a008_wallPlugTemp m8 : 16|16@1+ (1,0) [0|65535] "degC" Vector__XXX
 SG_ UMC_a008_SA_region m8 : 32|4@1+ (1,0) [0|15] "" Vector__XXX
 SG_ UMC_a008_SA_current m8 : 40|8@1+ (1,0) [0|255] "A" Vector__XXX
 SG_ UMC_a009_vehConnTemp m9 : 16|16@1+ (1,0) [0|65535] "degC" Vector__XXX
 SG_ UMC_a010_inputTerminalsTemp m10 : 16|16@1+ (1,0) [0|65535] "degC" Vector__XXX
 SG_ UMC_a012_pilotHigh m12 : 16|12@1- (0.01,0) [-20.48|20.47] "V" Vector__XXX
 SG_ UMC_a012_pilotLow m12 : 28|12@1- (0.01,0) [-20.48|20.47] "V" Vector__XXX
 SG_ UMC_a013_SA_region m13 : 16|4@1+ (1,0) [0|15] "" Vector__XXX
 SG_ UMC_a013_SA_current m13 : 24|8@1+ (1,0) [0|255] "A" Vector__XXX
 SG_ UMC_a015_SA_region m15 : 16|4@1+ (1,0) [0|15] "" Vector__XXX
 SG_ UMC_a015_SA_current m15 : 24|8@1+ (1,0) [0|255] "A" Vector__XXX
 SG_ UMC_a016_pcbaTemp m16 : 16|16@1+ (1,0) [0|65535] "degC" Vector__XXX
 SG_ UMC_a017_wallPlugTemp m17 : 16|16@1+ (1,0) [0|65535] "degC" Vector__XXX
 SG_ UMC_a017_SA_region m17 : 32|4@1+ (1,0) [0|15] "" Vector__XXX
 SG_ UMC_a017_SA_current m17 : 40|8@1+ (1,0) [0|255] "A" Vector__XXX
 SG_ UMC_a018_vehConnTemp m18 : 16|16@1+ (1,0) [0|65535] "degC" Vector__XXX
 SG_ UMC_a019_inputTerminalsTemp m19 : 16|16@1+ (1,0) [0|65535] "degC" Vector__XXX
 SG_ UMC_a024_groundImpedance m24 : 32|32@1+ (1,0) [0|4294967295] "Ohm" Vector__XXX
 SG_ UMC_a040_groundImpedance m40 : 32|32@1+ (1,0) [0|4294967295] "Ohm" Vector__XXX

BO_ 824 UMC_alertMatrix1: 8 UMC
 SG_ UMC_a001_gndMonIntrptLineSide : 0|1@1+ (1,0) [0|1] "" Vector__XXX
 SG_ UMC_a002_GFCITripped : 1|1@1+ (1,0) [0|1] "" Vector__XXX
 SG_ UMC_a003_GFCISelfTestFault : 2|1@1+ (1,0) [0|1] "" Vector__XXX
 SG_ UMC_a004_inputOverVoltage : 3|1@1+ (1,0) [0|1] "" Vector__XXX
 SG_ UMC_a005_inputUnderVoltage : 4|1@1+ (1,0) [0|1] "" Vector__XXX
 SG_ UMC_a006_contactorWelded : 5|1@1+ (1,0) [0|1] "" Vector__XXX
 SG_ UMC_a007_pcbaOT : 6|1@1+ (1,0) [0|1] "" Vector__XXX
 SG_ UMC_a008_wallPlugOT : 7|1@1+ (1,0) [0|1] "" Vector__XXX
 SG_ UMC_a009_vehConnOT : 8|1@1+ (1,0) [0|1] "" Vector__XXX
 SG_ UMC_a010_inputOT : 9|1@1+ (1,0) [0|1] "" Vector__XXX
 SG_ UMC_a011_proxDisconnected : 10|1@1+ (1,0) [0|1] "" Vector__XXX
 SG_ UMC_a012_pilotFault : 11|1@1+ (1,0) [0|1] "" Vector__XXX
 SG_ UMC_a013_SA_Temperature : 12|1@1+ (1,0) [0|1] "" Vector__XXX
 SG_ UMC_a014_SA_Genealogy : 13|1@1+ (1,0) [0|1] "" Vector__XXX
 SG_ UMC_a015_SA_Connection : 14|1@1+ (1,0) [0|1] "" Vector__XXX
 SG_ UMC_a016_pcbaOTFoldback : 15|1@1+ (1,0) [0|1] "" Vector__XXX
 SG_ UMC_a017_wallPlugOTFoldback : 16|1@1+ (1,0) [0|1] "" Vector__XXX
 SG_ UMC_a018_vehConnOTFoldback : 17|1@1+ (1,0) [0|1] "" Vector__XXX
 SG_ UMC_a019_inputOTFoldback : 18|1@1+ (1,0) [0|1] "" Vector__XXX
 SG_ UMC_a020_applicationCRC : 19|1@1+ (1,0) [0|1] "" Vector__XXX
 SG_ UMC_a021_dataBus : 20|1@1+ (1,0) [0|1] "" Vector__XXX
 SG_ UMC_a022_criticalRAM : 21|1@1+ (1,0) [0|1] "" Vector__XXX
 SG_ UMC_a023_adcSelfTest : 22|1@1+ (1,0) [0|1] "" Vector__XXX
 SG_ UMC_a024_gndResistanceHigh : 23|1@1+ (1,0) [0|1] "" Vector__XXX
 SG_ UMC_a025_cntrOpenExpectedClose : 24|1@1+ (1,0) [0|1] "" Vector__XXX
 SG_ UMC_a026_vRefOutOfRange : 25|1@1+ (1,0) [0|1] "" Vector__XXX
 SG_ UMC_a027_watchdogExpired : 26|1@1+ (1,0) [0|1] "" Vector__XXX
 SG_ UMC_a028_processorBooted : 27|1@1+ (1,0) [0|1] "" Vector__XXX
 SG_ UMC_a029_acPowerLoss : 28|1@1+ (1,0) [0|1] "" Vector__XXX
 SG_ UMC_a030_acLostPllLock : 29|1@1+ (1,0) [0|1] "" Vector__XXX
 SG_ UMC_a031_relayCoilVIrrational : 30|1@1+ (1,0) [0|1] "" Vector__XXX
 SG_ UMC_a032_chcVitalsRequestFailure : 31|1@1+ (1,0) [0|1] "" Vector__XXX
 SG_ UMC_a033_chcUpdateFault : 32|1@1+ (1,0) [0|1] "" Vector__XXX
 SG_ UMC_a034_v2lSAUnsupported : 33|1@1+ (1,0) [0|1] "" Vector__XXX
 SG_ UMC_a035_v2lHVACDetected : 34|1@1+ (1,0) [0|1] "" Vector__XXX
 SG_ UMC_a037_GFCICalibration : 36|1@1+ (1,0) [0|1] "" Vector__XXX
 SG_ UMC_a038_chcVitalsFault : 37|1@1+ (1,0) [0|1] "" Vector__XXX
 SG_ UMC_a039_inputOverCurrent : 38|1@1+ (1,0) [0|1] "" Vector__XXX
 SG_ UMC_a040_gndDisconnected : 39|1@1+ (1,0) [0|1] "" Vector__XXX
 SG_ UMC_a041_handleTempIrrational : 40|1@1+ (1,0) [0|1] "" Vector__XXX
 SG_ UMC_a042_GFCICalRelayDelta : 41|1@1+ (1,0) [0|1] "" Vector__XXX

BO_ 1285 UMC_smartAdapterInfo: 8 UMC
 SG_ SA_infoIndex M : 0|8@1+ (1,0) [0|255] "" Vector__XXX
 SG_ SA_genealogyVersion m0 : 8|8@1+ (1,0) [0|255] "" Vector__XXX
 SG_ SA_genealogyCrc m0 : 16|32@1+ (1,0) [0|4294967295] "" Vector__XXX
 SG_ SA_region m0 : 48|4@1+ (1,0) [0|15] "" Vector__XXX
 SG_ SA_OverTempThreshold m0 : 56|8@1+ (1,0) [0|255] "" Vector__XXX
 SG_ SA_partNumInt m31 : 8|32@1+ (1,0) [0|4294967295] "" Vector__XXX
 SG_ SA_partNumRev m31 : 40|8@1+ (1,0) [0|255] "" Vector__XXX
 SG_ SA_currentLimit m31 : 48|8@1+ (1,0) [0|255] "" Vector__XXX
 SG_ SA_l1Voltage m31 : 56|8@1+ (1,0) [0|255] "" Vector__XXX

BO_ 1320 UnixTimeSeconds: 4 Vector__XXX
 SG_ UnixTimeSeconds : 7|32@0+ (1,0) [0|4294967295] "s" Vector__XXX

BO_ 1949 V2G_evseLogData: 8 V2G
 SG_ V2G_evseLogDataSelect M : 0|5@1+ (1,0) [0|31] "" Vector__XXX
 SG_ V2G_chgParamRes_respCode m7 : 8|5@1+ (1,0) [0|31] "" Vector__XXX
 SG_ V2G_chgParamRes_finished m7 : 13|1@1+ (1,0) [0|1] "" Vector__XXX
 SG_ V2G_chgParamRes_evseStatus m7 : 14|4@1+ (1,0) [0|15] "" Vector__XXX
 SG_ V2G_chgParamRes_evseMaxILim m7 : 18|8@1+ (7.032,0) [0|1793.16] "A" Vector__XXX
 SG_ V2G_chgParamRes_evseMaxVLim m7 : 26|8@1+ (4.688,0) [0|1195.44] "V" Vector__XXX
 SG_ V2G_chgParamRes_evseMinILim m7 : 34|8@1+ (7.032,0) [0|1793.16] "A" Vector__XXX
 SG_ V2G_chgParamRes_evseMinVLim m7 : 42|8@1+ (4.688,0) [0|1195.44] "V" Vector__XXX
 SG_ V2G_chgParamRes_evseMaxPowerLim m7 : 50|8@1+ (5.9766,0) [0|1524.033] "kW" Vector__XXX
 SG_ V2G_chgParamRes_evseMaxPower_val m7 : 58|1@1+ (1,0) [0|1] "" Vector__XXX
 SG_ V2G_chgParamRes_isoState m7 : 59|3@1+ (1,0) [0|7] "" Vector__XXX
 SG_ V2G_chgParamRes_isoState_val m7 : 62|1@1+ (1,0) [0|1] "" Vector__XXX

BO_ 1338 VCBATT0_alertLog: 8 VCBATT0
 SG_ VCBATT0_alertID M : 0|9@1+ (1,0) [0|511] "" Vector__XXX
 SG_ VCBATT0_alertState : 15|1@1+ (1,0) [0|1] "" Vector__XXX
 SG_ VCBATT0_a001_InternalWatchdog m1 : 16|1@1+ (1,0) [0|1] "" Vector__XXX
 SG_ VCBATT0_a015_NVMMMemOverflow m15 : 16|1@1+ (1,0) [0|1] "" Vector__XXX
 SG_ VCBATT0_a015_NVMMFilesystemError m15 : 17|1@1+ (1,0) [0|1] "" Vector__XXX
 SG_ VCBATT0_a015_NVMMRecordIDError m15 : 18|1@1+ (1,0) [0|1] "" Vector__XXX
 SG_ VCBATT0_a059_voltageDrop m59 : 16|12@1+ (0.005443676,0) [0|22.29185322] "V" Vector__XXX
 SG_ VCBATT0_a059_resistanceEstimate m59 : 28|12@1+ (0.00244,0) [0|9.9918] "Ohms" Vector__XXX
 SG_ VCBATT0_a059_current m59 : 40|12@1+ (0.05,0) [0|204.75] "A" Vector__XXX
 SG_ VCBATT0_a063_switchChannel m63 : 16|8@1+ (1,0) [0|255] "" Vector__XXX
 SG_ VCBATT0_a063_switchType m63 : 24|8@1+ (1,0) [0|255] "" Vector__XXX
 SG_ VCBATT0_a063_ADCVoltage m63 : 32|8@1+ (0.025,0) [0|6.375] "V" Vector__XXX
 SG_ VCBATT0_a063_disconnected m63 : 40|1@1+ (1,0) [0|1] "" Vector__XXX
 SG_ VCBATT0_a063_indeterminate m63 : 41|1@1+ (1,0) [0|1] "" Vector__XXX
 SG_ VCBATT0_a063_stuckActive m63 : 42|1@1+ (1,0) [0|1] "" Vector__XXX
 SG_ VCBATT0_a063_faulted m63 : 43|1@1+ (1,0) [0|1] "" Vector__XXX

BO_ 973 VCBATT0_alertMatrix: 8 VCBATT0
 SG_ VCBATT0_matrixIndex M : 0|4@1+ (1,0) [0|15] "" Vector__XXX
 SG_ VCBATT0_a001_WatchdogReset m0 : 4|1@1+ (1,0) [0|1] "" Vector__XXX
 SG_ VCBATT0_a002_PowerLossReset m0 : 5|1@1+ (1,0) [0|1] "" Vector__XXX
 SG_ VCBATT0_a003_SWAssertion m0 : 6|1@1+ (1,0) [0|1] "" Vector__XXX
 SG_ VCBATT0_a005_CANTXError m0 : 8|1@1+ (1,0) [0|1] "" Vector__XXX
 SG_ VCBATT0_a006_CANTX_cyclicError m0 : 9|1@1+ (1,0) [0|1] "" Vector__XXX
 SG_ VCBATT0_a012_CPUReset m0 : 15|1@1+ (1,0) [0|1] "" Vector__XXX
 SG_ VCBATT0_a013_AlertManagerFault m0 : 16|1@1+ (1,0) [0|1] "" Vector__XXX
 SG_ VCBATT0_a015_NVMMError m0 : 18|1@1+ (1,0) [0|1] "" Vector__XXX
 SG_ VCBATT0_a016_NVMMRecordError m0 : 19|1@1+ (1,0) [0|1] "" Vector__XXX
 SG_ VCBATT0_a021_TaskSchedulerError m0 : 24|1@1+ (1,0) [0|1] "" Vector__XXX
 SG_ VCBATT0_a022_TaskInitError m0 : 25|1@1+ (1,0) [0|1] "" Vector__XXX
 SG_ VCBATT0_a029_CoreDump m0 : 32|1@1+ (1,0) [0|1] "" Vector__XXX
 SG_ VCBATT0_a030_ECULogUploadRequest m0 : 33|1@1+ (1,0) [0|1] "" Vector__XXX
 SG_ VCBATT0_a031_UDSActive m0 : 34|1@1+ (1,0) [0|1] "" Vector__XXX
 SG_ VCBATT0_a032_ipcWatchdogExpired m0 : 35|1@1+ (1,0) [0|1] "" Vector__XXX
 SG_ VCBATT0_a033_eccNonCorrectableEr m0 : 36|1@1+ (1,0) [0|1] "" Vector__XXX
 SG_ VCBATT0_a038_ProtFaultInfo m0 : 41|1@1+ (1,0) [0|1] "" Vector__XXX
 SG_ VCBATT0_a039_ProtFaultAddress m0 : 42|1@1+ (1,0) [0|1] "" Vector__XXX
 SG_ VCBATT0_a040_Backtrace m0 : 43|1@1+ (1,0) [0|1] "" Vector__XXX
 SG_ VCBATT0_a041_HighCPULoad m0 : 44|1@1+ (1,0) [0|1] "" Vector__XXX
 SG_ VCBATT0_a042_HighStackUsage m0 : 45|1@1+ (1,0) [0|1] "" Vector__XXX
 SG_ VCBATT0_a043_Task1msError m0 : 46|1@1+ (1,0) [0|1] "" Vector__XXX
 SG_ VCBATT0_a044_Task10msError m0 : 47|1@1+ (1,0) [0|1] "" Vector__XXX
 SG_ VCBATT0_a045_Task100msError m0 : 48|1@1+ (1,0) [0|1] "" Vector__XXX
 SG_ VCBATT0_a046_Task1000msError m0 : 49|1@1+ (1,0) [0|1] "" Vector__XXX
 SG_ VCBATT0_a047_resetReason m0 : 50|1@1+ (1,0) [0|1] "" Vector__XXX
 SG_ VCBATT0_a058_inputRHighSyncDebug m0 : 61|1@1+ (1,0) [0|1] "" Vector__XXX
 SG_ VCBATT0_a059_inputResistanceHigh m0 : 62|1@1+ (1,0) [0|1] "" Vector__XXX
 SG_ VCBATT0_a060_engineeringBuild m0 : 63|1@1+ (1,0) [0|1] "" Vector__XXX
 SG_ VCBATT0_a061_XCPConnected m1 : 4|1@1+ (1,0) [0|1] "" Vector__XXX
 SG_ VCBATT0_a062_XCPWasConnected m1 : 5|1@1+ (1,0) [0|1] "" Vector__XXX
 SG_ VCBATT0_a063_SwitchFault m1 : 6|1@1+ (1,0) [0|1] "" Vector__XXX
 SG_ VCBATT0_a064_busSleepReqTimeout m1 : 7|1@1+ (1,0) [0|1] "" Vector__XXX
 SG_ VCBATT0_a423_rtosSleepFailed m7 : 6|1@1+ (1,0) [0|1] "" Vector__XXX

BO_ 1858 VCBATT1_LVBMS_statusHigh: 8 VCBATT1
 SG_ VCBATT1_lvbmsStatusHighIndex M : 0|3@1+ (1,0) [0|7] "" Vector__XXX
 SG_ VCBATT1_LVBMS_packCurrent m0 : 3|22@1+ (0.001,-2000) [-2000|2194.302] "A" Vector__XXX
 SG_ VCBATT1_LVBMS_packVoltage m0 : 25|16@1+ (0.001,0) [0|65.534] "V" Vector__XXX
 SG_ VCBATT1_LVBMS_packTemperature m0 : 41|9@1+ (0.5,-50) [-50|205] "degC" Vector__XXX
 SG_ VCBATT1_LVBMS_MOSTemperature m0 : 50|12@1+ (0.5,-50) [-50|1997] "degC" Vector__XXX
 SG_ VCBATT1_LVBMS_sumCellVoltage m1 : 8|16@1+ (0.001,0) [0|65.534] "V" Vector__XXX
 SG_ VCBATT1_LVBMS_maxBrickVoltage m1 : 24|13@1+ (0.001,0) [0|8.19] "V" Vector__XXX
 SG_ VCBATT1_LVBMS_maxBrickVoltageInd m1 : 40|8@1+ (1,0) [0|254] "" Vector__XXX
 SG_ VCBATT1_totalLVLoadCurrent m2 : 8|14@1- (0.1,0) [-200|400] "A" Vector__XXX
 SG_ VCBATT1_LVPackChargeCurrentLimit m2 : 22|12@1+ (0.1,0) [0|400] "A" Vector__XXX
 SG_ VCBATT1_LVPackCurrent m2 : 34|14@1- (0.1,0) [-200|400] "A" Vector__XXX
 SG_ VCBATT1_LVBMS_estimatedPackOcv m2 : 48|16@1+ (0.001,0) [0|65.535] "V" Vector__XXX
 SG_ VCBATT1_LVBMS_voltageTarget m3 : 3|16@1+ (0.001,0) [0|65.534] "V" Vector__XXX
 SG_ VCBATT1_LVBMS_currentTarget m3 : 19|18@1+ (0.001,-122) [-120|120] "A" Vector__XXX
 SG_ VCBATT1_LVBMS_maxAllowedChargeCu m3 : 37|13@1+ (0.1,0) [0|819] "A" Vector__XXX
 SG_ VCBATT1_LVBMS_maxAllowedDischarg m3 : 50|13@1+ (0.1,0) [0|819] "A" Vector__XXX
 SG_ VCBATT1_LVBMS_MOSCommand m4 : 3|1@1+ (1,0) [0|1] "" Vector__XXX
 SG_ VCBATT1_LVBMS_ClearErrorCntrComm m4 : 4|1@1+ (1,0) [0|1] "" Vector__XXX
 SG_ VCBATT1_LVBMS_ClearHistoricFault m4 : 5|1@1+ (1,0) [0|1] "" Vector__XXX
 SG_ VCBATT1_LVBMS_ResetLVBMSCommand m4 : 6|1@1+ (1,0) [0|1] "" Vector__XXX
 SG_ VCBATT1_LVBMS_EnterHibernationCo m4 : 7|1@1+ (1,0) [0|1] "" Vector__XXX
 SG_ VCBATT1_LVBMS_ECPAState m4 : 8|2@1+ (1,0) [0|2] "" Vector__XXX
 SG_ VCBATT1_LVBMS_MOSState m4 : 10|2@1+ (1,0) [0|2] "" Vector__XXX
 SG_ VCBATT1_LVBMS_VehicleState m4 : 12|2@1+ (1,0) [0|3] "" Vector__XXX
 SG_ VCBATT1_LVBMS_LINWakeDisabled m4 : 14|1@1+ (1,0) [0|1] "" Vector__XXX
 SG_ VCBATT1_LVBMS_chargeType m4 : 16|3@1+ (1,0) [0|7] "" Vector__XXX
 SG_ VCBATT1_LVBMS_cellAndArcProtEnab m4 : 19|1@1+ (1,0) [0|1] "" Vector__XXX
 SG_ VCBATT1_LVBMS_avgBrickVoltage m4 : 24|13@1+ (0.001,0) [0|8.19] "V" Vector__XXX
 SG_ VCBATT1_LVBMS_minBrickVoltage m4 : 40|13@1+ (0.001,0) [0|8.19] "V" Vector__XXX
 SG_ VCBATT1_LVBMS_minBrickVoltageInd m4 : 56|8@1+ (1,0) [0|254] "" Vector__XXX

BO_ 1119 VCBATT1_LVSelfTests: 8 VCBATT1
 SG_ VCBATT1_LVSelfTestsChecksum : 0|8@1+ (1,0) [0|255] "" Vector__XXX
 SG_ VCBATT1_LVSelfTestsCounter : 8|4@1+ (1,0) [0|15] "" Vector__XXX
 SG_ VCBATT1_LVSelfTestsIndex M : 12|1@1+ (1,0) [0|1] "" Vector__XXX
 SG_ VCBATT1_lvProtectionSelfTestsEna m1 : 13|1@1+ (1,0) [0|1] "" Vector__XXX
 SG_ VCBATT1_startBattDomainOvercurre m1 : 14|1@1+ (1,0) [0|1] "" Vector__XXX
 SG_ VCBATT1_startBattDomainOvervolta m1 : 15|1@1+ (1,0) [0|1] "" Vector__XXX
 SG_ VCBATT1_startBattDomainUndervolt m1 : 16|1@1+ (1,0) [0|1] "" Vector__XXX
 SG_ VCBATT1_startDualPowerLoadsSelfT m1 : 17|1@1+ (1,0) [0|1] "" Vector__XXX
 SG_ VCBATT1_startVCBattBridgeEFuseAS m1 : 18|1@1+ (1,0) [0|1] "" Vector__XXX
 SG_ VCBATT1_startPCSOVShutdownSelfTe m1 : 19|1@1+ (1,0) [0|1] "" Vector__XXX
 SG_ VCBATT1_startPCSDomainOvervoltag m1 : 20|1@1+ (1,0) [0|1] "" Vector__XXX
 SG_ VCBATT1_startBattDomainUnde_0001 m1 : 21|1@1+ (1,0) [0|1] "" Vector__XXX
 SG_ VCBATT1_startPCSDomainUndervolta m1 : 22|1@1+ (1,0) [0|1] "" Vector__XXX
 SG_ VCBATT1_startVCFrontBridgeEFuseA m1 : 23|1@1+ (1,0) [0|1] "" Vector__XXX
 SG_ VCBATT1_battDomainOvercurrentSel m1 : 24|2@1+ (1,0) [0|3] "" Vector__XXX
 SG_ VCBATT1_battDomainOvercurre_0001 m1 : 26|3@1+ (1,0) [0|7] "" Vector__XXX
 SG_ VCBATT1_battDomainOvervoltageSel m1 : 29|2@1+ (1,0) [0|3] "" Vector__XXX
 SG_ VCBATT1_battDomainOvervolta_0001 m1 : 32|3@1+ (1,0) [0|7] "" Vector__XXX
 SG_ VCBATT1_battDomainUndervoltageSe m1 : 35|2@1+ (1,0) [0|3] "" Vector__XXX
 SG_ VCBATT1_battDomainUndervolt_0001 m1 : 37|3@1+ (1,0) [0|7] "" Vector__XXX
 SG_ VCBATT1_dualPowerLoadsSelfTestRe m1 : 40|2@1+ (1,0) [0|3] "" Vector__XXX
 SG_ VCBATT1_dualPowerLoadsSelfTestSt m1 : 42|3@1+ (1,0) [0|7] "" Vector__XXX
 SG_ VCBATT1_vcbattBridgeEFuseASICSel m1 : 45|2@1+ (1,0) [0|3] "" Vector__XXX
 SG_ VCBATT1_vcbattBridgeEFuseAS_0001 m1 : 48|3@1+ (1,0) [0|7] "" Vector__XXX
 SG_ VCBATT1_uvProtectionState m1 : 51|4@1+ (1,0) [0|15] "" Vector__XXX
 SG_ VCBATT1_undervoltageSelfTestFaul m1 : 55|1@1+ (1,0) [0|1] "" Vector__XXX
 SG_ VC_selfTestsRunningMode m1 : 56|3@1+ (1,0) [0|7] "" Vector__XXX

BO_TX_BU_ 820 : GTW;
BO_TX_BU_ 826 : GTW;
BO_TX_BU_ 666 : GTW;
BO_TX_BU_ 723 : GTW;
BO_TX_BU_ 851 : GTW;
BO_TX_BU_ 991 : GTW;
BO_TX_BU_ 663 : GTW;
BO_TX_BU_ 956 : GTW;
BO_TX_BU_ 787 : GTW;
BO_TX_BU_ 839 : GTW;
BO_TX_BU_ 627 : GTW;
BO_TX_BU_ 947 : GTW;
BO_TX_BU_ 660 : GTW;
BO_TX_BU_ 1193 : GTW;
BO_TX_BU_ 853 : GTW;
BO_TX_BU_ 644 : GTW;
BO_TX_BU_ 595 : GTW;
BO_TX_BU_ 1565 : GTW;
BO_TX_BU_ 1969 : GTW;
BO_TX_BU_ 1533 : UMC;
BO_TX_BU_ 824 : UMC;
BO_TX_BU_ 1285 : UMC;
BO_TX_BU_ 1949 : V2G;
BO_TX_BU_ 1338 : VCBATT0;
BO_TX_BU_ 973 : VCBATT0;
BO_TX_BU_ 1858 : VCBATT1;
BO_TX_BU_ 1119 : VCBATT1;
CM_ BO_ 820 "Touchscreen user interface computer message: powertrain control; forwarded onto this bus by the gateway; frame length observed on a vehicle bus";
CM_ SG_ 820 UI_systemPowerLimit "Touchscreen user interface computer: system power limit; raw 31 = signal not available (SNA)";
CM_ SG_ 820 UI_pedalMap "Switch between various platform specific pedal maps";
CM_ SG_ 820 UI_enableRegenBackfill "Indicates if regenerative braking backfill has been enabled by the driver";
CM_ SG_ 820 UI_systemTorqueLimit "Touchscreen user interface computer: system torque limit; raw 63 = signal not available (SNA)";
CM_ SG_ 820 UI_closureConfirmed "Touchscreen user interface computer: closure confirmed";
CM_ SG_ 820 UI_regenTorqueMax "Maximum regen torque from UI - reports different value when in track mode";
CM_ SG_ 820 UI_limitMode "Commands limited drive inverter capabilities based on special vehicle modes";
CM_ SG_ 820 UI_factoryCustomerDrivingModeReq "Touchscreen user interface computer: factory customer driving mode request";
CM_ SG_ 820 UI_motorOnMode "Request from the UI to selectively enable or disable a drive unit (dev-only)";
CM_ SG_ 820 UI_stoppingMode "Low-speed behavior when no pedal is pressed (stopping/rolling/creeping)";
CM_ SG_ 820 UI_DIAppSliderDebug "Touchscreen user interface computer: DI app slider debug";
CM_ SG_ 820 UI_speedLimit "Maximum allowed speed enforced at vehicle level; raw 511 = signal not available (SNA)";
CM_ SG_ 820 UI_enableSmartShift "Stalkless convenience feature that allows unparking with only a firm press of brake pedal";
CM_ SG_ 820 UI_navVehParallelToRdCanContinue "Whether the vehicle is parallel parked on a public road; raw 0 = signal not available (SNA)";
CM_ SG_ 820 UI_powertrainControlCounter "Touchscreen user interface computer: powertrain control counter";
CM_ SG_ 820 UI_powertrainControlChecksum "Touchscreen user interface computer: powertrain control checksum";
CM_ BO_ 826 "Touchscreen user interface computer message: range; forwarded onto this bus by the gateway; frame length observed on a vehicle bus";
CM_ SG_ 826 UI_ratedRange "Rated range in miles";
CM_ SG_ 826 UI_whpm "Touchscreen user interface computer: whpm";
CM_ SG_ 826 UI_soe "State of energy";
CM_ SG_ 826 UI_uSoe "Usable state of energy";
CM_ SG_ 826 UI_softPackLimitPct "Touchscreen user interface computer: soft pack limit pct";
CM_ SG_ 826 UI_targetFullPackEnergy "Touchscreen user interface computer: target full pack energy";
CM_ BO_ 666 "Touchscreen user interface computer message: seat control; forwarded onto this bus by the gateway; frame length from the layout, not yet observed on a vehicle bus";
CM_ SG_ 666 UI_seatControlIndex "Touchscreen user interface computer: seat control index";
CM_ SG_ 666 UI_3RSeatChildLock "Reports the state of 3rd row seat fold flat child lock from the UI";
CM_ SG_ 666 UI_2RowLeftSeatTrackBack "Touchscreen user interface computer: 2 row left seat track back";
CM_ SG_ 666 UI_2RowLeftSeatTrackForward "Touchscreen user interface computer: 2 row left seat track forward";
CM_ SG_ 666 UI_2RowRightSeatTrackBack "Touchscreen user interface computer: 2 row right seat track back";
CM_ SG_ 666 UI_2RowRightSeatTrackForward "Touchscreen user interface computer: 2 row right seat track forward";
CM_ SG_ 666 UI_left3RowSeatAdjustmentRequest "Reports request from the touchscreen User Interface (UI) to actuate the left third row seat.";
CM_ SG_ 666 UI_right3RowSeatAdjustmentReques "Reports request from the touchscreen User Interface (UI) to actuate the right third row seat.";
CM_ SG_ 666 UI_2RLeftSeatFanReq "Request for second row left seat ventilation";
CM_ SG_ 666 UI_2RRightSeatFanReq "Request for second row right seat ventilation";
CM_ SG_ 666 UI_leftThirdRowSeatRequestFromRe "Touchscreen user interface computer: left third row seat request from rear display";
CM_ SG_ 666 UI_rightThirdRowSeatRequestFromR "Touchscreen user interface computer: right third row seat request from rear display";
CM_ SG_ 666 UI_seatChoreographyStopRequest "Reports if the UI requests to stop the seat choreography";
CM_ BO_ 723 "Touchscreen user interface computer message: solar data; forwarded onto this bus by the gateway; frame length observed on a vehicle bus";
CM_ SG_ 723 UI_solarAzimuthAngle "Touchscreen user interface computer: solar azimuth angle; raw 32768 = signal not available (SNA)";
CM_ SG_ 723 UI_solarAzimuthAngleCarRef "Touchscreen user interface computer: solar azimuth angle car ref; raw 255 = signal not available (SNA)";
CM_ SG_ 723 UI_isSunUp "is sun up; raw 3 = signal not available (SNA)";
CM_ SG_ 723 UI_solarElevationAngle "Solar Elevation Angle; raw 127 = signal not available (SNA)";
CM_ SG_ 723 UI_screenPCBTemperature "Temperature of display PCB";
CM_ SG_ 723 UI_minsToSunset "time until to sunset";
CM_ SG_ 723 UI_minsToSunrise "time until to sunrise";
CM_ BO_ 851 "Touchscreen user interface computer message: status; forwarded onto this bus by the gateway; frame length observed on a vehicle bus";
CM_ SG_ 851 UI_touchActive "No touchscreen errors";
CM_ SG_ 851 UI_audioActive "Audio system is ready.";
CM_ SG_ 851 UI_bluetoothActive "Touchscreen user interface computer: bluetooth active";
CM_ SG_ 851 UI_cellActive "Cell is powered";
CM_ SG_ 851 UI_displayReady "UI is ready (GUI_allReady) and display is ok (GUI_displayHardwareOK)";
CM_ SG_ 851 UI_displayOn "UI display on/off status";
CM_ SG_ 851 UI_wifiActive "WiFi active.";
CM_ SG_ 851 UI_wifiConnected "WiFi Connected.";
CM_ SG_ 851 UI_systemActive "Touchscreen user interface computer: system active";
CM_ SG_ 851 UI_readyForDrive "Ready for drive (UI ready or self park request)";
CM_ SG_ 851 UI_cellConnected "Detects if the cell is connected to a network.";
CM_ SG_ 851 UI_vpnActive "VPN connected.";
CM_ SG_ 851 UI_autopilotTrial "Touchscreen user interface computer: autopilot trial";
CM_ SG_ 851 UI_factoryReset "UI request for factory reset; raw 0 = signal not available (SNA)";
CM_ SG_ 851 UI_gpsActive "GPS has valid fix";
CM_ SG_ 851 UI_screenshotActive "Touchscreen user interface computer: screenshot active";
CM_ SG_ 851 UI_radioActive "Touchscreen user interface computer: radio active";
CM_ SG_ 851 UI_cellNetworkTechnology "Describes the type of cellular network to which the car computer is connected: GPRS_2G(114Kbps) < EGDE_2G(368Kbps) < 3G(3Mbps) < HSDPA_3G(14Mbps) < HSPAplus_4Gg(168Mbps) < 4G_LTE(299Mbps); raw 15 = signal not available (SNA)";
CM_ SG_ 851 UI_cellReceiverPower "Touchscreen user interface computer: cell receiver power";
CM_ SG_ 851 UI_falseTouchCounter "Count false touches after display is off.";
CM_ SG_ 851 UI_developmentCar "Touchscreen user interface computer: development car";
CM_ SG_ 851 UI_cameraActive "Touchscreen user interface computer: camera active";
CM_ SG_ 851 UI_cellSignalBars "Number of cellular signal bars displayed on the UI, derived from cellSignalStrength; raw 7 = signal not available (SNA)";
CM_ SG_ 851 UI_trailerModeTelltale "Color of the trailer mode telltale";
CM_ SG_ 851 UI_pcbTemperature "PCB digital temp sensor reading in DegC";
CM_ SG_ 851 UI_cpuTemperature "Apollo Lake SOC temperature in DegC";
CM_ BO_ 991 "Touchscreen user interface computer message: status2; forwarded onto this bus by the gateway; frame length observed on a vehicle bus";
CM_ SG_ 991 UI_mobileAppStepCount "Touchscreen user interface computer: mobile app step count";
CM_ SG_ 991 UI_userRequestSnapshot "Touchscreen user interface computer: user request snapshot";
CM_ SG_ 991 UI_touchDetected "Touchscreen user interface computer: touch detected";
CM_ SG_ 991 UI_validDeviceForEUSummon "Touchscreen user interface computer: valid device for EU summon";
CM_ SG_ 991 UI_locatedAtHome "Touchscreen user interface computer: located at home";
CM_ SG_ 991 UI_locatedAtWork "Touchscreen user interface computer: located at work";
CM_ SG_ 991 UI_locatedAtFavorite "Touchscreen user interface computer: located at favorite";
CM_ SG_ 991 UI_displayInDarkMode "Touchscreen user interface computer: display in dark mode";
CM_ SG_ 991 UI_userActivity "Indicates user interaction with the center display";
CM_ SG_ 991 UI_activeTouchPoints "Quantity of active touch points on the Center Display";
CM_ SG_ 991 UI_linkState "Connectivity link state";
CM_ SG_ 991 UI_sentryModeState "Touchscreen user interface computer: sentry mode state; raw 6 = signal not available (SNA)";
CM_ SG_ 991 UI_autopilotSentryRequest "whether AP sentry mode should be enabled";
CM_ SG_ 991 UI_mobileAppConnected "Reports if Web Real-Time Communication (WebRTC) connection is connected while summon screen is open on the mobile app.";
CM_ SG_ 991 UI_phoneLeftInCabin "Used for monitoring phone left behind feature";
CM_ SG_ 991 UI_autoshiftDRState "Reports the User Interface (UI) autoshift Drive/Reverse state.";
CM_ SG_ 991 UI_wifiBtModuleType "Reports the type of Wi-Fi and Bluetooth (BT) module.";
CM_ SG_ 991 UI_sohHealthStatus "Touchscreen user interface computer: soh health status";
CM_ SG_ 991 UI_selfParkState "Reports the auto park state changes; raw 255 = signal not available (SNA)";
CM_ SG_ 991 UI_summonDeviceIndex "Reports which device is being used to control summon.";
CM_ SG_ 991 UI_fullScreenMode "Aggregates all situations with which the UI is using the entire screen so stalkless gear controls are not present";
CM_ SG_ 991 UI_sentryModeCameraDetection "Touchscreen user interface computer: sentry mode camera detection";
CM_ SG_ 991 UI_wakeOnIPActive "Touchscreen user interface computer: wake on IP active";
CM_ SG_ 991 UI_sapActive "Touchscreen user interface computer: sap active";
CM_ SG_ 991 UI_sapClients "Touchscreen user interface computer: sap clients";
CM_ SG_ 991 UI_connectivityStandbyActive "Touchscreen user interface computer: connectivity standby active";
CM_ BO_ 663 "Touchscreen user interface computer message: suspension control; forwarded onto this bus by the gateway; frame length from the layout, not yet observed on a vehicle bus";
CM_ SG_ 663 UI_adaptiveRideRequest "UI customer adaptive ride request for air suspension.";
CM_ SG_ 663 UI_suspensionLoweringRequest "Touchscreen user interface computer: suspension lowering request; raw 3 = signal not available (SNA)";
CM_ SG_ 663 UI_geofenceLevelingRequest "Geofence level request from customer; raw 5 = signal not available (SNA)";
CM_ SG_ 663 UI_jackModeToggleRequest "Touchscreen user interface computer: jack mode toggle request";
CM_ SG_ 663 UI_adaptiveTuningRequest0 "Touchscreen user interface computer: adaptive tuning request0";
CM_ SG_ 663 UI_adaptiveTuningRequest1 "Touchscreen user interface computer: adaptive tuning request1";
CM_ SG_ 663 UI_roadRoughnessLookahead "Touchscreen user interface computer: road roughness lookahead; raw 127 = signal not available (SNA)";
CM_ SG_ 663 UI_roadRoughnessStart "Touchscreen user interface computer: road roughness start; raw 31 = signal not available (SNA)";
CM_ SG_ 663 UI_mapVersionUsed "Touchscreen user interface computer: map version used; raw 255 = signal not available (SNA)";
CM_ SG_ 663 UI_suspensionControlCounter "Touchscreen user interface computer: suspension control counter";
CM_ SG_ 663 UI_suspensionLevelRequest "Touchscreen user interface computer: suspension level request";
CM_ SG_ 663 UI_suspensionControlChecksum "Touchscreen user interface computer: suspension control checksum";
CM_ BO_ 956 "Touchscreen user interface computer message: tpms RC psetting; forwarded onto this bus by the gateway; frame length observed on a vehicle bus";
CM_ SG_ 956 UI_sendCalibrateTireRequest "Reports UI requests for PMDI to start the tire pressure calibration routine.";
CM_ SG_ 956 UI_setRCPFront "Touchscreen user interface computer: set RCP front";
CM_ SG_ 956 UI_setRCPRear "Touchscreen user interface computer: set RCP rear";
CM_ BO_ 787 "Touchscreen user interface computer message: track mode settings; forwarded onto this bus by the gateway; frame length observed on a vehicle bus";
CM_ SG_ 787 UI_trackModeRequest "User selected track mode";
CM_ SG_ 787 UI_trackRotationTendency "Touchscreen user interface computer: track rotation tendency";
CM_ SG_ 787 UI_trackStabilityAssist "Touchscreen user interface computer: track stability assist";
CM_ SG_ 787 UI_trackPostCooling "Touchscreen user interface computer: track post cooling";
CM_ SG_ 787 UI_trackCmpOverclock "Touchscreen user interface computer: track cmp overclock";
CM_ SG_ 787 UI_trackModeBrakeTemps "Touchscreen user interface computer: track mode brake temps";
CM_ SG_ 787 UI_trackDrivePowerAvailability "Reports power deployment strategy for Track Mode. Ranges from endurance limit to maximum power.";
CM_ SG_ 787 UI_stabilityModeRequest "Touchscreen user interface computer: stability mode request";
CM_ SG_ 787 UI_trackModeSettingsCounter "Touchscreen user interface computer: track mode settings counter";
CM_ SG_ 787 UI_trackModeSettingsChecksum "Touchscreen user interface computer: track mode settings checksum";
CM_ BO_ 839 "Touchscreen user interface computer message: trip planning; forwarded onto this bus by the gateway; frame length observed on a vehicle bus";
CM_ SG_ 839 UI_tripPlanningActive "Indicates that there is active route in navigation with a valid energy at destination prediction.";
CM_ SG_ 839 UI_navToSupercharger "Navigation destination is a supercharger";
CM_ SG_ 839 UI_navFastchargerType "when navigation is turned on, this enum identifies the type of fastcharger the car is navigating to based on the rated power from sc_locations";
CM_ SG_ 839 UI_battPreconditionOnNavState "Indicates to battery and thermal systems whether the battery should be actively heated, passively heated, actively cooled, or passively cooled";
CM_ SG_ 839 UI_requestActiveBatteryHeating "Flag to request BMS enable active battery heating";
CM_ SG_ 839 UI_battPreconditionOnNavPowerReq "The preconditioning power that Trip Planner is requesting from the thermal system to use for battery preconditioning (cooling or heating); raw 127 = signal not available (SNA)";
CM_ SG_ 839 UI_battPreconditionOnNavTargetT "The pack temperature that Trip Planner is targeting upon arriving to a fast charger; raw 255 = signal not available (SNA)";
CM_ SG_ 839 UI_ambientTempAtDestination "Touchscreen user interface computer: ambient temp at destination; raw 128 = signal not available (SNA)";
CM_ SG_ 839 UI_tripPlanChargingTargetPercent "Touchscreen user interface computer: trip plan charging target percent; raw 1023 = signal not available (SNA)";
CM_ SG_ 839 UI_energyAtDestination "expected energy at destination in kWh for current navigation route; raw 32768 = signal not available (SNA)";
CM_ BO_ 627 "Touchscreen user interface computer message: vehicle control; forwarded onto this bus by the gateway; frame length observed on a vehicle bus";
CM_ SG_ 627 UI_powerStateRequest "Request accessory power";
CM_ SG_ 627 UI_childDoorLockOnRight "UI child door lock request status.";
CM_ SG_ 627 UI_frontFogSwitch "Request for front fog lights to be on";
CM_ SG_ 627 UI_summonActive "Summon is active";
CM_ SG_ 627 UI_frunkRequest "Request open frunk";
CM_ SG_ 627 UI_wiperMode "Wiper mode state; raw 0 = signal not available (SNA)";
CM_ SG_ 627 UI_steeringBacklightEnabled "Touchscreen user interface computer: steering backlight enabled";
CM_ SG_ 627 UI_steeringButtonMode "Steering wheel control mode";
CM_ SG_ 627 UI_walkUpUnlock "Walk up unlock request (datavalue defaults to false)";
CM_ SG_ 627 UI_walkAwayLock "Walk away door lock setting.";
CM_ SG_ 627 UI_unlockOnPark "Unlock on park setting";
CM_ SG_ 627 UI_globalUnlockOn "Global Unlock Setting";
CM_ SG_ 627 UI_childDoorLockOnLeft "UI child door lock request status.";
CM_ SG_ 627 UI_lockRequest "Lock or unlock request; raw 7 = signal not available (SNA)";
CM_ SG_ 627 UI_alarmEnabled "UI customer level request to enable alarm.";
CM_ SG_ 627 UI_intrusionSensorOn "Touchscreen user interface computer: intrusion sensor on";
CM_ SG_ 627 UI_stop12vSupport "UI request to stop rails as 12v support";
CM_ SG_ 627 UI_rearFogSwitch "Request for rear fog lights to be on";
CM_ SG_ 627 UI_mirrorFoldRequest "Fold the mirrors; raw 3 = signal not available (SNA)";
CM_ SG_ 627 UI_mirrorHeatRequest "Customer usage of mirror heater and rear defrost";
CM_ SG_ 627 UI_remoteStartRequest "remote start or self park request; raw 4 = signal not available (SNA)";
CM_ SG_ 627 UI_seeYouHomeLightingOn "Headlights after exit";
CM_ SG_ 627 UI_powerOff "power off rails request.";
CM_ SG_ 627 UI_displayBrightnessLevel "UI brightness; raw 255 = signal not available (SNA)";
CM_ SG_ 627 UI_ambientLightingEnabled "Touchscreen user interface computer: ambient lighting enabled";
CM_ SG_ 627 UI_autoHighBeamEnabled "Enable Automatic High/Low Beams";
CM_ SG_ 627 UI_frontLeftSeatHeatReq "Request for front left seat heat";
CM_ SG_ 627 UI_frontRightSeatHeatReq "Request for front left seat heat";
CM_ SG_ 627 UI_rearLeftSeatHeatReq "UI request for second row left seat heater";
CM_ SG_ 627 UI_rearCenterSeatHeatReq "UI request for second row middle seat heater";
CM_ SG_ 627 UI_rearRightSeatHeatReq "UI request for second row right seat heater";
CM_ SG_ 627 UI_autoFoldMirrorsOn "Enable Automatic Mirror Fold/Unfold";
CM_ SG_ 627 UI_mirrorDipOnReverse "Enable Mirror Dip On Reverse";
CM_ SG_ 627 UI_remoteClosureRequest "remote actuate trunk; raw 3 = signal not available (SNA)";
CM_ SG_ 627 UI_wiperRequest "Wiper speed; raw 0 = signal not available (SNA)";
CM_ SG_ 627 UI_domeLightSwitch "Dome light switch";
CM_ SG_ 627 UI_honkHorn "Touchscreen user interface computer: honk horn";
CM_ SG_ 627 UI_driveStateRequest "Touchscreen user interface computer: drive state request";
CM_ SG_ 627 UI_rearWindowLockout "Touchscreen user interface computer: rear window lockout";
CM_ BO_ 947 "Touchscreen user interface computer message: vehicle control2; forwarded onto this bus by the gateway; frame length observed on a vehicle bus";
CM_ SG_ 947 UI_gloveboxRequest "UI request to open the glovebox";
CM_ SG_ 947 UI_trunkRequest "Rear trunk request";
CM_ SG_ 947 UI_UMCUpdateInhibit "Touchscreen user interface computer: UMC update inhibit";
CM_ SG_ 947 UI_WCUpdateInhibit "Touchscreen user interface computer: WC update inhibit";
CM_ SG_ 947 UI_soundHornOnLock "Touchscreen user interface computer: sound horn on lock";
CM_ SG_ 947 UI_locksPanelActive "Touchscreen user interface computer: locks panel active";
CM_ SG_ 947 UI_PINToDriveEnabled "UI customer level request to pin to drive enabled.";
CM_ SG_ 947 UI_PINToDrivePassed "UI customer level request to enable drive with pin passed.";
CM_ SG_ 947 UI_disableMirrorAutoDim "Request to disable side and rear-view mirror auto dim";
CM_ SG_ 947 UI_lightSwitch "Headlight mode; raw 4 = signal not available (SNA)";
CM_ SG_ 947 UI_readyToAddKey "Ready to add key";
CM_ SG_ 947 UI_alarmTriggerRequest "Alarm activation request from UI";
CM_ SG_ 947 UI_VCSECFeature1 "Touchscreen user interface computer: VCSEC feature1";
CM_ SG_ 947 UI_VCLEFTFeature1 "Touchscreen user interface computer: VCLEFT feature1";
CM_ SG_ 947 UI_summonState "Touchscreen user interface computer: summon state; raw 0 = signal not available (SNA)";
CM_ SG_ 947 UI_displayOnForUser "User is present";
CM_ SG_ 947 UI_freeRollModeRequest "Touchscreen user interface computer: free roll mode request";
CM_ SG_ 947 UI_BLEPushNotificationRequest "Reports that the User Interface (UI) wants to talk to a phone and Vehicle Controller Security (VCSEC) should let all connected phones know.";
CM_ SG_ 947 UI_pairKeyQRCodeDisplaying "Touchscreen user interface computer: pair key QR code displaying";
CM_ SG_ 947 UI_keepAutopilotAwake "Reports the request for Vehicle Controller (VC) to keep autopilot awake.";
CM_ SG_ 947 UI_batteryPreconditioningRequest "Requests battery preconditioning.";
CM_ SG_ 947 UI_coastDownMode "Touchscreen user interface computer: coast down mode";
CM_ SG_ 947 UI_autopilotPowerStateRequest "Requests different power states from autopilot ECU depending on feature usage.";
CM_ SG_ 947 UI_shorted12VCellTestMode "Touchscreen user interface computer: shorted12 v cell test mode";
CM_ SG_ 947 UI_autoRollWindowsOnLockEnable "UI customer level request to enable auto-roll windows on lock";
CM_ SG_ 947 UI_virtualPitchSensorOverrideOKF "Touchscreen user interface computer: virtual pitch sensor override OK for aim";
CM_ SG_ 947 UI_conditionalLoggingEnabledVCSE "Touchscreen user interface computer: conditional logging enabled VCSEC";
CM_ SG_ 947 UI_WC3UpdateInhibit "Touchscreen user interface computer: WC3 update inhibit";
CM_ SG_ 947 UI_steeringWheelHeatReq "Request to enable steering wheel heater";
CM_ SG_ 947 UI_disableHorn "Request to disable horn";
CM_ SG_ 947 UI_frontLeftSeatFanReq "Request for front left seat ventilation";
CM_ SG_ 947 UI_frontRightSeatAutoClimateReq "UI setting to enable auto seat heating and cooling for front right seat";
CM_ SG_ 947 UI_frontRightSeatFanReq "Request for front left seat ventilation";
CM_ SG_ 947 UI_3RLeftSeatHeatReq "UI request for third row left seat heater";
CM_ SG_ 947 UI_3RRightSeatHeatReq "UI request for third row right seat heater";
CM_ SG_ 947 UI_sleepFeature1 "Touchscreen user interface computer: sleep feature1";
CM_ SG_ 947 UI_dcr12VThreshold "Touchscreen user interface computer: dcr12 v threshold";
CM_ SG_ 947 UI_frontLeftSeatAutoClimateReq "UI setting to enable auto seat heating and cooling for front left seat";
CM_ SG_ 947 UI_wiperHeaterReq "UI request to enable the wiper heater";
CM_ SG_ 947 UI_tireSeason "Touchscreen user interface computer: tire season";
CM_ SG_ 947 UI_saveTireConfigReq "Touchscreen user interface computer: save tire config req";
CM_ SG_ 947 UI_silentAlarm "Signal indicating alarms should be silenced";
CM_ SG_ 947 UI_sleepFeature2 "Touchscreen user interface computer: sleep feature2";
CM_ BO_ 660 "Touchscreen user interface computer message: vehicle control3; forwarded onto this bus by the gateway; frame length observed on a vehicle bus";
CM_ SG_ 660 UI_lightFlashRequest "UI flash lights request";
CM_ SG_ 660 UI_keylessDrivingEnabled "Touchscreen user interface computer: keyless driving enabled";
CM_ SG_ 660 UI_phoneCallActive "On phone call via Bluetooth if active";
CM_ SG_ 660 UI_drivingSideVEH "Touchscreen user interface computer: driving side VEH";
CM_ SG_ 660 UI_keyPairResponse "Touchscreen user interface computer: key pair response";
CM_ SG_ 660 UI_lightShowClosuresEnabled "Closure movements enabled during light show";
CM_ SG_ 660 UI_steeringWheelHeatAutoReq "UI setting to request auto steering wheel heat";
CM_ SG_ 660 UI_steeringWheelHeatLevelReq "Request for steering wheel heat";
CM_ SG_ 660 UI_headlightPulseRequest "Request headlights to pulse";
CM_ SG_ 660 UI_VCSECFeature2 "Touchscreen user interface computer: VCSEC feature2";
CM_ SG_ 660 UI_VCSECFeature3 "Touchscreen user interface computer: VCSEC feature3";
CM_ SG_ 660 UI_VCSECFeature4 "Touchscreen user interface computer: VCSEC feature4";
CM_ SG_ 660 UI_VCSECFeature5 "Touchscreen user interface computer: VCSEC feature5";
CM_ SG_ 660 UI_shortHornRequest "Touchscreen user interface computer: short horn request";
CM_ SG_ 660 UI_packTempLoggingRequest "Touchscreen user interface computer: pack temp logging request";
CM_ SG_ 660 UI_UMC3UpdateInhibit "Touchscreen user interface computer: UMC3 update inhibit";
CM_ SG_ 660 UI_handsFreeTrunk "Touchscreen user interface computer: hands free trunk";
CM_ SG_ 660 UI_displayRedShiftActive "UI's reduce blue light setting is active";
CM_ SG_ 660 UI_handsFreeFrunk "Touchscreen user interface computer: hands free frunk";
CM_ SG_ 660 UI_fasciaCameraWashRequest "User request to activate fascia camera wash";
CM_ SG_ 660 UI_autoClosuresExcludeHome "Touchscreen user interface computer: auto closures exclude home";
CM_ SG_ 660 UI_leftRearSeatAdjustmentRequest "Reports request from UI to actuate the left rear seat";
CM_ SG_ 660 UI_rightRearSeatAdjustmentReques "Reports request from UI to actuate the right rear seat";
CM_ SG_ 660 UI_blindSpotIndicatorLightReques "Request for blind spot indicator light";
CM_ SG_ 660 UI_etcBluetoothControl "Touchscreen user interface computer: etc bluetooth control";
CM_ SG_ 660 UI_keepOnAccessoryPortsReq "User setting to keep 12V outlets, USB ports, and phone chargers powered in CONDITIONING";
CM_ SG_ 660 UI_fasciaCameraShown "Whether the UI is currently showing the fascia camera view";
CM_ SG_ 660 UI_rearSeatChildLock "Reports the state of second row seat fold flat child lock from the UI";
CM_ SG_ 660 UI_windowPercentageRequest "Reports the window percentage value when window request is WINDOW_REQUEST_GOTO_PERCENT.";
CM_ SG_ 660 UI_windowRequestedFL "Reports that the front left window is requested.";
CM_ SG_ 660 UI_windowRequestedFR "Reports that the front right window is requested.";
CM_ SG_ 660 UI_windowRequestedRL "Reports that the rear left window is requested.";
CM_ SG_ 660 UI_windowRequestedRR "Reports that the rear right window is requested.";
CM_ SG_ 660 UI_windowRequest "Window operation request from the mobile app.";
CM_ SG_ 660 UI_closeTrunkRequest "Explicity request for the rear trunk to close";
CM_ SG_ 660 UI_childPresenceDetectionDisable "User request to disable child presence detection behaviors until the next drive cycle";
CM_ SG_ 660 UI_V2LAUpdateInhibit "Touchscreen user interface computer: V2 LA update inhibit";
CM_ SG_ 660 UI_userPresenceDetectionEnabled "Touchscreen user interface computer: user presence detection enabled";
CM_ SG_ 660 UI_derivedLoadshedFeature "Reports whether vehicle controllers should enable derived loadshed feature.";
CM_ SG_ 660 UI_rearSeatFoldConfirmed "Touchscreen user interface computer: rear seat fold confirmed";
CM_ SG_ 660 UI_leftRearSeatRequestFromRearDi "Touchscreen user interface computer: left rear seat request from rear display";
CM_ SG_ 660 UI_selfParkStandingBy "Reports that summon is in standby.";
CM_ SG_ 660 UI_rightRearSeatRequestFromRearD "Touchscreen user interface computer: right rear seat request from rear display";
CM_ BO_ 1193 "Touchscreen user interface computer message: vehicle control4; forwarded onto this bus by the gateway; frame length from the layout, not yet observed on a vehicle bus";
CM_ SG_ 1193 UI_firstRowLeftDomeLightRequest "Monitors the dome light switch for first row left side";
CM_ SG_ 1193 UI_firstRowRightDomeLightRequest "Monitors the dome light switch for first row right side";
CM_ SG_ 1193 UI_secondRowLeftDomeLightRequest "Monitors the dome light switch for second row left side";
CM_ SG_ 1193 UI_secondRowCenterDomeLightReque "Monitors the dome light switch for second row center side";
CM_ SG_ 1193 UI_secondRowRightDomeLightReques "Monitors the dome light switch for second row right side";
CM_ SG_ 1193 UI_thirdRowLeftDomeLightRequest "Monitors the dome light switch for third row left side";
CM_ SG_ 1193 UI_thirdRowRightDomeLightRequest "Monitors the dome light switch for third row right side";
CM_ BO_ 853 "Touchscreen user interface computer message: vehicle control thermal; forwarded onto this bus by the gateway; frame length observed on a vehicle bus";
CM_ SG_ 853 UI_coolantFlowRequest "request for coolant flow to MCU in LPM";
CM_ SG_ 853 UI_inletActiveCoolTarget "request for coolant temperature at Car Computer inlet";
CM_ SG_ 853 UI_disableHVPTThermalLoads "Request thermal system to disable active battery heating";
CM_ SG_ 853 UI_enableCompLiquidPumpOut "Touchscreen user interface computer: enable comp liquid pump out";
CM_ SG_ 853 UI_enableCOP1HighSHOperation "Touchscreen user interface computer: enable COP1 high SH operation";
CM_ SG_ 853 UI_enableIncreasedEvapRampRate "Touchscreen user interface computer: enable increased evap ramp rate";
CM_ SG_ 853 UI_enableCOP1BatteryHeating "Touchscreen user interface computer: enable COP1 battery heating";
CM_ SG_ 853 UI_enableCOP1CabinHeatingBattery "Touchscreen user interface computer: enable COP1 cabin heating battery heating";
CM_ SG_ 853 UI_enableLouverAutoDetection "Touchscreen user interface computer: enable louver auto detection";
CM_ SG_ 853 UI_enableUserFacingLowFlowDelive "Touchscreen user interface computer: enable user facing low flow delivery alert";
CM_ SG_ 853 UI_disableHvacCameraOnlyDefog "Touchscreen user interface computer: disable hvac camera only defog";
CM_ SG_ 853 UI_enableEXVFastCalibration "Touchscreen user interface computer: enable EXV fast calibration";
CM_ SG_ 853 UI_enableThermalDriverlessSelfTe "Touchscreen user interface computer: enable thermal driverless self test";
CM_ SG_ 853 UI_enableCoolantDasTarget "Touchscreen user interface computer: enable coolant das target";
CM_ SG_ 853 UI_geofencedLiftgateHeight "Touchscreen user interface computer: geofenced liftgate height; raw 255 = signal not available (SNA)";
CM_ SG_ 853 UI_convenienceFeatureLimit "UI limit request in SOE (UI Gauge) for convenience features";
CM_ SG_ 853 UI_allowConvenienceFeatures "Whether UI allows convenenience features";
CM_ SG_ 853 UI_enableConservativeBatteryHeat "Touchscreen user interface computer: enable conservative battery heating";
CM_ SG_ 853 UI_enableDefaultApTempTarget "Touchscreen user interface computer: enable default ap temp target";
CM_ SG_ 853 UI_enableHVACCompressorWasteHeat "Touchscreen user interface computer: enable HVAC compressor waste heat";
CM_ SG_ 853 UI_disablePhoneChargingPads "Reports requests from the User Interface (UI) to disable wireless phone charging.";
CM_ SG_ 853 UI_isAtTeslaFacility "Touchscreen user interface computer: is at tesla facility";
CM_ SG_ 853 UI_enableThermalPowerBudget "Touchscreen user interface computer: enable thermal power budget";
CM_ SG_ 853 UI_enableHVACAPFanHeaterControl "Touchscreen user interface computer: enable HVACAP fan heater control";
CM_ SG_ 853 UI_enableAutopilotAirPurge "Touchscreen user interface computer: enable autopilot air purge";
CM_ SG_ 853 UI_enableForcedAirCameraHeater "Touchscreen user interface computer: enable forced air camera heater";
CM_ SG_ 853 UI_enableHvacCOPOnUndeliveredVeh "Touchscreen user interface computer: enable hvac COP on undelivered veh";
CM_ BO_ 644 "Touchscreen user interface computer message: vehicle modes; forwarded onto this bus by the gateway; frame length observed on a vehicle bus";
CM_ SG_ 644 UI_factoryMode "Touchscreen user interface computer: factory mode";
CM_ SG_ 644 UI_transportMode "Reports UI Transport mode. Distinct from GTW transport mode.";
CM_ SG_ 644 UI_showroomMode "Reports UI showroom mode.";
CM_ SG_ 644 UI_serviceMode "Service diagnostics mode active";
CM_ SG_ 644 UI_isDelivered "Touchscreen user interface computer: is delivered";
CM_ SG_ 644 UI_hasEverBeenDelivered "Touchscreen user interface computer: has ever been delivered";
CM_ SG_ 644 UI_homelinkV2Command0 "Touchscreen user interface computer: homelink V2 command0";
CM_ SG_ 644 UI_homelinkV2Command1 "Touchscreen user interface computer: homelink V2 command1";
CM_ SG_ 644 UI_homelinkV2Command2 "Touchscreen user interface computer: homelink V2 command2";
CM_ SG_ 644 UI_carWashMode "Car Wash Mode";
CM_ SG_ 644 UI_valetMode "Touchscreen user interface computer: valet mode";
CM_ SG_ 644 UI_gameMode "Game mode";
CM_ SG_ 644 UI_diagnosticsAllowed "Touchscreen user interface computer: diagnostics allowed";
CM_ SG_ 644 UI_serviceModePlus "Extended service diagnostics mode active";
CM_ SG_ 644 UI_premiumAmpPowerOff "Premium amplifier power off request";
CM_ SG_ 644 UI_signedCmdHardLocked "Touchscreen user interface computer: signed cmd hard locked";
CM_ SG_ 644 UI_signedCmdServiceMode "Signal reported by Touchscreen user interface computer";
CM_ SG_ 644 UI_closureEasterEggStatus "Touchscreen user interface computer: closure easter egg status";
CM_ SG_ 644 UI_lightShowType "Type of the light show to be run";
CM_ SG_ 644 UI_sohTestRequest "Touchscreen user interface computer: soh test request";
CM_ SG_ 644 UI_upkeepMode "Reports UI Upkeep Mode state.";
CM_ SG_ 644 UI_vehicleModesCounter "Touchscreen user interface computer: vehicle modes counter";
CM_ SG_ 644 UI_vehicleModesChecksum "Touchscreen user interface computer: vehicle modes checksum";
CM_ BO_ 595 "Touchscreen user interface computer message: vent panel control request; forwarded onto this bus by the gateway; frame length observed on a vehicle bus";
CM_ SG_ 595 UI_ventPanelControlRequestIndex "Touchscreen user interface computer: vent panel control request index";
CM_ SG_ 595 UI_ventPanelLeftPositionX "Airwave left X position.";
CM_ SG_ 595 UI_ventPanelLeftPositionY "Airwave left Y position.";
CM_ SG_ 595 UI_ventPanelLeftLateralSplit "Airwave left split amount.";
CM_ SG_ 595 UI_ventPanelRightPositionX "Airwave right X position.";
CM_ SG_ 595 UI_ventPanelRightPositionY "Airwave right Y position.";
CM_ SG_ 595 UI_ventPanelRightLateralSplit "Airwave right split amount.";
CM_ SG_ 595 UI_ventPanelLeftLateralMode "Airwave left focus or split.";
CM_ SG_ 595 UI_ventPanelRightLateralMode "Airwave right focus or split.";
CM_ SG_ 595 UI_hvacReqActiveVents "Active airwave sides - left/right/both";
CM_ SG_ 595 UI_vent2RLeftPositionX "Airwave left X position.";
CM_ SG_ 595 UI_vent2RLeftPositionY "Airwave left Y position.";
CM_ SG_ 595 UI_vent2RRightPositionX "Airwave left X position.";
CM_ SG_ 595 UI_vent2RRightPositionY "Airwave left Y position.";
CM_ SG_ 595 UI_hvacReqThirdRowState "Detects HVAC third row fan speed request.";
CM_ BO_ 1565 "Touchscreen user interface computer message: weather data service; forwarded onto this bus by the gateway; frame length observed on a vehicle bus";
CM_ SG_ 1565 UI_weatherSvcTimeSinceLast "Touchscreen user interface computer: weather svc time since last; raw 127 = signal not available (SNA)";
CM_ SG_ 1565 UI_weatherSvcWindDir "Touchscreen user interface computer: weather svc wind dir; raw 255 = signal not available (SNA)";
CM_ SG_ 1565 UI_weatherSvcTemperature "Touchscreen user interface computer: weather svc temperature; raw 255 = signal not available (SNA)";
CM_ SG_ 1565 UI_weatherSvcHumidity "Touchscreen user interface computer: weather svc humidity; raw 63 = signal not available (SNA)";
CM_ SG_ 1565 UI_weatherSvcDewPoint "Touchscreen user interface computer: weather svc dew point; raw 255 = signal not available (SNA)";
CM_ SG_ 1565 UI_weatherSvcCloudCover "Touchscreen user interface computer: weather svc cloud cover; raw 63 = signal not available (SNA)";
CM_ SG_ 1565 UI_weatherSvcPrecipProb "Touchscreen user interface computer: weather svc precip prob; raw 63 = signal not available (SNA)";
CM_ SG_ 1565 UI_weatherSvcRaining "Touchscreen user interface computer: weather svc raining";
CM_ SG_ 1565 UI_weatherSvcSnowing "Touchscreen user interface computer: weather svc snowing";
CM_ SG_ 1565 UI_weatherSvcWindSpeed "Touchscreen user interface computer: weather svc wind speed; raw 63 = signal not available (SNA)";
CM_ BO_ 1969 "Touchscreen user interface computer message: weather data service forecast; forwarded onto this bus by the gateway; frame length observed on a vehicle bus";
CM_ SG_ 1969 UI_weatherSvcForecastMuxIndex "Touchscreen user interface computer: weather svc forecast mux index";
CM_ SG_ 1969 UI_weatherSvcForecastTempC_hour1 "Touchscreen user interface computer: weather svc forecast temp c hour1; raw 255 = signal not available (SNA)";
CM_ SG_ 1969 UI_weatherSvcForecastTempC_hour2 "Touchscreen user interface computer: weather svc forecast temp c hour2; raw 255 = signal not available (SNA)";
CM_ SG_ 1969 UI_weatherSvcForecastTempC_hour3 "Touchscreen user interface computer: weather svc forecast temp c hour3; raw 255 = signal not available (SNA)";
CM_ SG_ 1969 UI_weatherSvcForecastTempC_hour4 "Touchscreen user interface computer: weather svc forecast temp c hour4; raw 255 = signal not available (SNA)";
CM_ SG_ 1969 UI_weatherSvcForecastTempC_hour5 "Touchscreen user interface computer: weather svc forecast temp c hour5; raw 255 = signal not available (SNA)";
CM_ SG_ 1969 UI_weatherSvcForecastTempC_hour6 "Touchscreen user interface computer: weather svc forecast temp c hour6; raw 255 = signal not available (SNA)";
CM_ SG_ 1969 UI_weatherSvcForecastTempC_hour7 "Touchscreen user interface computer: weather svc forecast temp c hour7; raw 255 = signal not available (SNA)";
CM_ SG_ 1969 UI_weatherSvcForecastTempC_hour8 "Touchscreen user interface computer: weather svc forecast temp c hour8; raw 255 = signal not available (SNA)";
CM_ SG_ 1969 UI_weatherSvcForecastTempC_hour9 "Touchscreen user interface computer: weather svc forecast temp c hour9; raw 255 = signal not available (SNA)";
CM_ SG_ 1969 UI_weatherSvcForecastTempC__0001 "Touchscreen user interface computer: weather svc forecast temp c hour10; raw 255 = signal not available (SNA)";
CM_ SG_ 1969 UI_weatherSvcForecastTempC__0002 "Touchscreen user interface computer: weather svc forecast temp c hour11; raw 255 = signal not available (SNA)";
CM_ SG_ 1969 UI_weatherSvcForecastHumidity_ho "Touchscreen user interface computer: weather svc forecast humidity hour1; raw 63 = signal not available (SNA)";
CM_ SG_ 1969 UI_weatherSvcForecastHumidi_0003 "Touchscreen user interface computer: weather svc forecast humidity hour2; raw 63 = signal not available (SNA)";
CM_ SG_ 1969 UI_weatherSvcForecastHumidi_0004 "Touchscreen user interface computer: weather svc forecast humidity hour3; raw 63 = signal not available (SNA)";
CM_ SG_ 1969 UI_weatherSvcForecastHumidi_0005 "Touchscreen user interface computer: weather svc forecast humidity hour4; raw 63 = signal not available (SNA)";
CM_ SG_ 1969 UI_weatherSvcForecastHumidi_0006 "Touchscreen user interface computer: weather svc forecast humidity hour5; raw 63 = signal not available (SNA)";
CM_ SG_ 1969 UI_weatherSvcForecastHumidi_0007 "Touchscreen user interface computer: weather svc forecast humidity hour6; raw 63 = signal not available (SNA)";
CM_ SG_ 1969 UI_weatherSvcForecastHumidi_0008 "Touchscreen user interface computer: weather svc forecast humidity hour7; raw 63 = signal not available (SNA)";
CM_ SG_ 1969 UI_weatherSvcForecastHumidi_0009 "Touchscreen user interface computer: weather svc forecast humidity hour8; raw 63 = signal not available (SNA)";
CM_ SG_ 1969 UI_weatherSvcForecastHumidi_0010 "Touchscreen user interface computer: weather svc forecast humidity hour9; raw 63 = signal not available (SNA)";
CM_ SG_ 1969 UI_weatherSvcForecastHumidi_0001 "Touchscreen user interface computer: weather svc forecast humidity hour10; raw 63 = signal not available (SNA)";
CM_ SG_ 1969 UI_weatherSvcForecastHumidi_0002 "Touchscreen user interface computer: weather svc forecast humidity hour11; raw 63 = signal not available (SNA)";
CM_ SG_ 1969 UI_weatherSvcForecastWindSpeedKp "Touchscreen user interface computer: weather svc forecast wind speed kph hour1; raw 63 = signal not available (SNA)";
CM_ SG_ 1969 UI_weatherSvcForecastWindSp_0003 "Touchscreen user interface computer: weather svc forecast wind speed kph hour2; raw 63 = signal not available (SNA)";
CM_ SG_ 1969 UI_weatherSvcForecastWindSp_0004 "Touchscreen user interface computer: weather svc forecast wind speed kph hour3; raw 63 = signal not available (SNA)";
CM_ SG_ 1969 UI_weatherSvcForecastWindSp_0005 "Touchscreen user interface computer: weather svc forecast wind speed kph hour4; raw 63 = signal not available (SNA)";
CM_ SG_ 1969 UI_weatherSvcForecastWindSp_0006 "Touchscreen user interface computer: weather svc forecast wind speed kph hour5; raw 63 = signal not available (SNA)";
CM_ SG_ 1969 UI_weatherSvcForecastWindSp_0007 "Touchscreen user interface computer: weather svc forecast wind speed kph hour6; raw 63 = signal not available (SNA)";
CM_ SG_ 1969 UI_weatherSvcForecastWindSp_0008 "Touchscreen user interface computer: weather svc forecast wind speed kph hour7; raw 63 = signal not available (SNA)";
CM_ SG_ 1969 UI_weatherSvcForecastWindSp_0009 "Touchscreen user interface computer: weather svc forecast wind speed kph hour8; raw 63 = signal not available (SNA)";
CM_ SG_ 1969 UI_weatherSvcForecastWindSp_0010 "Touchscreen user interface computer: weather svc forecast wind speed kph hour9; raw 63 = signal not available (SNA)";
CM_ SG_ 1969 UI_weatherSvcForecastWindSp_0001 "Touchscreen user interface computer: weather svc forecast wind speed kph hour10; raw 63 = signal not available (SNA)";
CM_ SG_ 1969 UI_weatherSvcForecastWindSp_0002 "Touchscreen user interface computer: weather svc forecast wind speed kph hour11; raw 63 = signal not available (SNA)";
CM_ BO_ 1533 "UMC ECU message: alert log; frame length from the layout, not yet observed on a vehicle bus";
CM_ SG_ 1533 UMC_alertID "UMC ECU: alert ID";
CM_ SG_ 1533 UMC_alertType "UMC ECU: alert type";
CM_ SG_ 1533 UMC_a001_groundImpedance "UMC ECU: a001 ground impedance";
CM_ SG_ 1533 UMC_a002_ccidRmsCurrent "UMC ECU: a002 ccid rms current";
CM_ SG_ 1533 UMC_a002_ccidRmsCurrentAvg "UMC ECU: a002 ccid rms current avg";
CM_ SG_ 1533 UMC_a002_ccidDCGfciCurrent "UMC ECU: a002 ccid DC gfci current";
CM_ SG_ 1533 UMC_a002_ccidFaultReason "UMC ECU: a002 ccid fault reason; raw 0 = signal not available (SNA)";
CM_ SG_ 1533 UMC_a002_ccidFaultBucket "UMC ECU: a002 ccid fault bucket";
CM_ SG_ 1533 UMC_a003_faultType "UMC ECU: a003 fault type";
CM_ SG_ 1533 UMC_a003_ccidSelfTestDuty "UMC ECU: a003 ccid self test duty";
CM_ SG_ 1533 UMC_a003_ccidSelfTestCurrent "UMC ECU: a003 ccid self test current";
CM_ SG_ 1533 UMC_a004_lineVoltage "UMC ECU: a004 line voltage";
CM_ SG_ 1533 UMC_a004_inputVoltage "UMC ECU: a004 input voltage";
CM_ SG_ 1533 UMC_a004_inputNeutralVoltage "UMC ECU: a004 input neutral voltage";
CM_ SG_ 1533 UMC_a005_lineVoltage "UMC ECU: a005 line voltage";
CM_ SG_ 1533 UMC_a005_inputVoltage "UMC ECU: a005 input voltage";
CM_ SG_ 1533 UMC_a005_inputNeutralVoltage "UMC ECU: a005 input neutral voltage";
CM_ SG_ 1533 UMC_a006_outputVoltage "UMC ECU: a006 output voltage";
CM_ SG_ 1533 UMC_a006_faultType "UMC ECU: a006 fault type";
CM_ SG_ 1533 UMC_a006_umcReceptacleVoltage "UMC ECU: a006 umc receptacle voltage";
CM_ SG_ 1533 UMC_a006_handleVoltage "UMC ECU: a006 handle voltage";
CM_ SG_ 1533 UMC_a006_line1StuckClosed "UMC ECU: a006 line1 stuck closed";
CM_ SG_ 1533 UMC_a006_line2StuckClosed "UMC ECU: a006 line2 stuck closed";
CM_ SG_ 1533 UMC_a007_pcbaTemp "UMC ECU: a007 pcba temp";
CM_ SG_ 1533 UMC_a008_wallPlugTemp "UMC ECU: a008 wall plug temp";
CM_ SG_ 1533 UMC_a008_SA_region "UMC ECU: a008 SA region";
CM_ SG_ 1533 UMC_a008_SA_current "UMC ECU: a008 SA current";
CM_ SG_ 1533 UMC_a009_vehConnTemp "UMC ECU: a009 veh conn temp";
CM_ SG_ 1533 UMC_a010_inputTerminalsTemp "UMC ECU: a010 input terminals temp";
CM_ SG_ 1533 UMC_a012_pilotHigh "UMC ECU: a012 pilot high";
CM_ SG_ 1533 UMC_a012_pilotLow "UMC ECU: a012 pilot low";
CM_ SG_ 1533 UMC_a013_SA_region "UMC ECU: a013 SA region";
CM_ SG_ 1533 UMC_a013_SA_current "UMC ECU: a013 SA current";
CM_ SG_ 1533 UMC_a015_SA_region "UMC ECU: a015 SA region";
CM_ SG_ 1533 UMC_a015_SA_current "UMC ECU: a015 SA current";
CM_ SG_ 1533 UMC_a016_pcbaTemp "UMC ECU: a016 pcba temp";
CM_ SG_ 1533 UMC_a017_wallPlugTemp "UMC ECU: a017 wall plug temp";
CM_ SG_ 1533 UMC_a017_SA_region "UMC ECU: a017 SA region";
CM_ SG_ 1533 UMC_a017_SA_current "UMC ECU: a017 SA current";
CM_ SG_ 1533 UMC_a018_vehConnTemp "UMC ECU: a018 veh conn temp";
CM_ SG_ 1533 UMC_a019_inputTerminalsTemp "UMC ECU: a019 input terminals temp";
CM_ SG_ 1533 UMC_a024_groundImpedance "UMC ECU: a024 ground impedance";
CM_ SG_ 1533 UMC_a040_groundImpedance "UMC ECU: a040 ground impedance";
CM_ BO_ 824 "UMC ECU message: alert matrix1; frame length from the layout, not yet observed on a vehicle bus";
CM_ SG_ 824 UMC_a001_gndMonIntrptLineSide "UMC ECU: a001 gnd mon intrpt line side";
CM_ SG_ 824 UMC_a002_GFCITripped "UMC ECU: a002 GFCI tripped";
CM_ SG_ 824 UMC_a003_GFCISelfTestFault "UMC ECU: a003 GFCI self test fault";
CM_ SG_ 824 UMC_a004_inputOverVoltage "UMC ECU: a004 input over voltage";
CM_ SG_ 824 UMC_a005_inputUnderVoltage "UMC ECU: a005 input under voltage";
CM_ SG_ 824 UMC_a006_contactorWelded "UMC ECU: a006 contactor welded";
CM_ SG_ 824 UMC_a007_pcbaOT "UMC ECU: a007 pcba OT";
CM_ SG_ 824 UMC_a008_wallPlugOT "UMC ECU: a008 wall plug OT";
CM_ SG_ 824 UMC_a009_vehConnOT "UMC ECU: a009 veh conn OT";
CM_ SG_ 824 UMC_a010_inputOT "UMC ECU: a010 input OT";
CM_ SG_ 824 UMC_a011_proxDisconnected "UMC ECU: a011 prox disconnected";
CM_ SG_ 824 UMC_a012_pilotFault "UMC ECU: a012 pilot fault";
CM_ SG_ 824 UMC_a013_SA_Temperature "UMC ECU: a013 SA temperature";
CM_ SG_ 824 UMC_a014_SA_Genealogy "UMC ECU: a014 SA genealogy";
CM_ SG_ 824 UMC_a015_SA_Connection "UMC ECU: a015 SA connection";
CM_ SG_ 824 UMC_a016_pcbaOTFoldback "UMC ECU: a016 pcba OT foldback";
CM_ SG_ 824 UMC_a017_wallPlugOTFoldback "UMC ECU: a017 wall plug OT foldback";
CM_ SG_ 824 UMC_a018_vehConnOTFoldback "UMC ECU: a018 veh conn OT foldback";
CM_ SG_ 824 UMC_a019_inputOTFoldback "UMC ECU: a019 input OT foldback";
CM_ SG_ 824 UMC_a020_applicationCRC "UMC ECU: a020 application CRC";
CM_ SG_ 824 UMC_a021_dataBus "UMC ECU: a021 data bus";
CM_ SG_ 824 UMC_a022_criticalRAM "UMC ECU: a022 critical RAM";
CM_ SG_ 824 UMC_a023_adcSelfTest "UMC ECU: a023 adc self test";
CM_ SG_ 824 UMC_a024_gndResistanceHigh "UMC ECU: a024 gnd resistance high";
CM_ SG_ 824 UMC_a025_cntrOpenExpectedClose "UMC ECU: a025 cntr open expected close";
CM_ SG_ 824 UMC_a026_vRefOutOfRange "UMC ECU: a026 v ref out of range";
CM_ SG_ 824 UMC_a027_watchdogExpired "UMC ECU: a027 watchdog expired";
CM_ SG_ 824 UMC_a028_processorBooted "UMC ECU: a028 processor booted";
CM_ SG_ 824 UMC_a029_acPowerLoss "UMC ECU: a029 ac power loss";
CM_ SG_ 824 UMC_a030_acLostPllLock "UMC ECU: a030 ac lost pll lock";
CM_ SG_ 824 UMC_a031_relayCoilVIrrational "UMC ECU: a031 relay coil v irrational";
CM_ SG_ 824 UMC_a032_chcVitalsRequestFailure "UMC ECU: a032 chc vitals request failure";
CM_ SG_ 824 UMC_a033_chcUpdateFault "UMC ECU: a033 chc update fault";
CM_ SG_ 824 UMC_a034_v2lSAUnsupported "UMC ECU: a034 v2l SA unsupported";
CM_ SG_ 824 UMC_a035_v2lHVACDetected "UMC ECU: a035 v2l HVAC detected";
CM_ SG_ 824 UMC_a037_GFCICalibration "UMC ECU: a037 GFCI calibration";
CM_ SG_ 824 UMC_a038_chcVitalsFault "UMC ECU: a038 chc vitals fault";
CM_ SG_ 824 UMC_a039_inputOverCurrent "UMC ECU: a039 input over current";
CM_ SG_ 824 UMC_a040_gndDisconnected "UMC ECU: a040 gnd disconnected";
CM_ SG_ 824 UMC_a041_handleTempIrrational "UMC ECU: a041 handle temp irrational";
CM_ SG_ 824 UMC_a042_GFCICalRelayDelta "UMC ECU: a042 GFCI cal relay delta";
CM_ BO_ 1285 "UMC ECU message: smart adapter info; frame length from the layout, not yet observed on a vehicle bus";
CM_ SG_ 1285 SA_infoIndex "UMC ECU: info index";
CM_ SG_ 1285 SA_genealogyVersion "UMC ECU: genealogy version";
CM_ SG_ 1285 SA_genealogyCrc "UMC ECU: genealogy crc";
CM_ SG_ 1285 SA_region "Reports the smart adapter region from Electrically Erasable Programmable Read-Only Memory (EEPROM).";
CM_ SG_ 1285 SA_OverTempThreshold "Reports the smart adapter overtemperature threshold from Electrically Erasable Programmable Read-Only Memory (EEPROM).";
CM_ SG_ 1285 SA_partNumInt "Reports the smart adapter part number integer representation.";
CM_ SG_ 1285 SA_partNumRev "Reports the smart adapter part number revision.";
CM_ SG_ 1285 SA_currentLimit "Reports the smart adapter current limit from Electrically Erasable Programmable Read-Only Memory (EEPROM).";
CM_ SG_ 1285 SA_l1Voltage "Reports the smart adapter nominal voltage request from Electrically Erasable Programmable Read-Only Memory (EEPROM).";
CM_ BO_ 1320 "Vector__XXX ECU message: unix time seconds; frame length observed on a vehicle bus";
CM_ SG_ 1320 UnixTimeSeconds "Vehicle clock, seconds since 1970-01-01 UTC";
CM_ BO_ 1949 "V2G ECU message: evse log data; frame length from the layout, not yet observed on a vehicle bus";
CM_ SG_ 1949 V2G_evseLogDataSelect "V2G ECU: evse log data select";
CM_ SG_ 1949 V2G_chgParamRes_respCode "Charge parameter response code reported by CCS DC charger";
CM_ SG_ 1949 V2G_chgParamRes_finished "V2G ECU: chg param res finished";
CM_ SG_ 1949 V2G_chgParamRes_evseStatus "Charge parameter discovery status reported by CCS DC charger";
CM_ SG_ 1949 V2G_chgParamRes_evseMaxILim "Maximum current limit reported by CCS DC charger in charge parameter discovery message";
CM_ SG_ 1949 V2G_chgParamRes_evseMaxVLim "Maximum voltage limit reported by CCS DC charger in charge parameter discovery message";
CM_ SG_ 1949 V2G_chgParamRes_evseMinILim "Minimum current limit reported by CCS DC charger in charge parameter discovery message";
CM_ SG_ 1949 V2G_chgParamRes_evseMinVLim "Minimum voltage limit reported by CCS DC charger in charge parameter discovery message";
CM_ SG_ 1949 V2G_chgParamRes_evseMaxPowerLim "Maximum power limit reported by CCS DC charger in charge parameter discovery message";
CM_ SG_ 1949 V2G_chgParamRes_evseMaxPower_val "Whether maximum power limit reported by CCS DC charger is valid in charge parameter discovery message";
CM_ SG_ 1949 V2G_chgParamRes_isoState "The EVSE's reported isolation status";
CM_ SG_ 1949 V2G_chgParamRes_isoState_val "The validity of the EVSE's reported isolation status";
CM_ BO_ 1338 "VCBATT0 ECU message: alert log; frame length from the layout, not yet observed on a vehicle bus";
CM_ SG_ 1338 VCBATT0_alertID "VCBATT0 ECU: alert ID";
CM_ SG_ 1338 VCBATT0_alertState "VCBATT0 ECU: alert state";
CM_ SG_ 1338 VCBATT0_a001_InternalWatchdog "VCBATT0 ECU: a001 internal watchdog";
CM_ SG_ 1338 VCBATT0_a015_NVMMMemOverflow "VCBATT0 ECU: a015 NVMM mem overflow";
CM_ SG_ 1338 VCBATT0_a015_NVMMFilesystemError "VCBATT0 ECU: a015 NVMM filesystem error";
CM_ SG_ 1338 VCBATT0_a015_NVMMRecordIDError "VCBATT0 ECU: a015 NVMM record ID error";
CM_ SG_ 1338 VCBATT0_a059_voltageDrop "VCBATT0 ECU: a059 voltage drop";
CM_ SG_ 1338 VCBATT0_a059_resistanceEstimate "VCBATT0 ECU: a059 resistance estimate";
CM_ SG_ 1338 VCBATT0_a059_current "VCBATT0 ECU: a059 current";
CM_ SG_ 1338 VCBATT0_a063_switchChannel "VCBATT0 ECU: a063 switch channel";
CM_ SG_ 1338 VCBATT0_a063_switchType "VCBATT0 ECU: a063 switch type";
CM_ SG_ 1338 VCBATT0_a063_ADCVoltage "VCBATT0 ECU: a063 ADC voltage";
CM_ SG_ 1338 VCBATT0_a063_disconnected "VCBATT0 ECU: a063 disconnected";
CM_ SG_ 1338 VCBATT0_a063_indeterminate "VCBATT0 ECU: a063 indeterminate";
CM_ SG_ 1338 VCBATT0_a063_stuckActive "VCBATT0 ECU: a063 stuck active";
CM_ SG_ 1338 VCBATT0_a063_faulted "VCBATT0 ECU: a063 faulted";
CM_ BO_ 973 "VCBATT0 ECU message: alert matrix; frame length from the layout, not yet observed on a vehicle bus";
CM_ SG_ 973 VCBATT0_matrixIndex "VCBATT0 ECU: matrix index";
CM_ SG_ 973 VCBATT0_a001_WatchdogReset "VCBATT0 ECU: a001 watchdog reset";
CM_ SG_ 973 VCBATT0_a002_PowerLossReset "VCBATT0 ECU: a002 power loss reset";
CM_ SG_ 973 VCBATT0_a003_SWAssertion "VCBATT0 ECU: a003 SW assertion";
CM_ SG_ 973 VCBATT0_a005_CANTXError "VCBATT0 ECU: a005 CANTX error";
CM_ SG_ 973 VCBATT0_a006_CANTX_cyclicError "VCBATT0 ECU: a006 CANTX cyclic error";
CM_ SG_ 973 VCBATT0_a012_CPUReset "VCBATT0 ECU: a012 CPU reset";
CM_ SG_ 973 VCBATT0_a013_AlertManagerFault "VCBATT0 ECU: a013 alert manager fault";
CM_ SG_ 973 VCBATT0_a015_NVMMError "VCBATT0 ECU: a015 NVMM error";
CM_ SG_ 973 VCBATT0_a016_NVMMRecordError "VCBATT0 ECU: a016 NVMM record error";
CM_ SG_ 973 VCBATT0_a021_TaskSchedulerError "VCBATT0 ECU: a021 task scheduler error";
CM_ SG_ 973 VCBATT0_a022_TaskInitError "VCBATT0 ECU: a022 task init error";
CM_ SG_ 973 VCBATT0_a029_CoreDump "VCBATT0 ECU: a029 core dump";
CM_ SG_ 973 VCBATT0_a030_ECULogUploadRequest "VCBATT0 ECU: a030 ECU log upload request";
CM_ SG_ 973 VCBATT0_a031_UDSActive "VCBATT0 ECU: a031 UDS active";
CM_ SG_ 973 VCBATT0_a032_ipcWatchdogExpired "VCBATT0 ECU: a032 ipc watchdog expired";
CM_ SG_ 973 VCBATT0_a033_eccNonCorrectableEr "VCBATT0 ECU: a033 ecc non correctable error";
CM_ SG_ 973 VCBATT0_a038_ProtFaultInfo "VCBATT0 ECU: a038 prot fault info";
CM_ SG_ 973 VCBATT0_a039_ProtFaultAddress "VCBATT0 ECU: a039 prot fault address";
CM_ SG_ 973 VCBATT0_a040_Backtrace "VCBATT0 ECU: a040 backtrace";
CM_ SG_ 973 VCBATT0_a041_HighCPULoad "VCBATT0 ECU: a041 high CPU load";
CM_ SG_ 973 VCBATT0_a042_HighStackUsage "VCBATT0 ECU: a042 high stack usage";
CM_ SG_ 973 VCBATT0_a043_Task1msError "VCBATT0 ECU: a043 task1ms error";
CM_ SG_ 973 VCBATT0_a044_Task10msError "VCBATT0 ECU: a044 task10ms error";
CM_ SG_ 973 VCBATT0_a045_Task100msError "VCBATT0 ECU: a045 task100ms error";
CM_ SG_ 973 VCBATT0_a046_Task1000msError "VCBATT0 ECU: a046 task1000ms error";
CM_ SG_ 973 VCBATT0_a047_resetReason "VCBATT0 ECU: a047 reset reason";
CM_ SG_ 973 VCBATT0_a058_inputRHighSyncDebug "VCBATT0 ECU: a058 input r high sync debug";
CM_ SG_ 973 VCBATT0_a059_inputResistanceHigh "VCBATT0 ECU: a059 input resistance high";
CM_ SG_ 973 VCBATT0_a060_engineeringBuild "VCBATT0 ECU: a060 engineering build";
CM_ SG_ 973 VCBATT0_a061_XCPConnected "VCBATT0 ECU: a061 XCP connected";
CM_ SG_ 973 VCBATT0_a062_XCPWasConnected "VCBATT0 ECU: a062 XCP was connected";
CM_ SG_ 973 VCBATT0_a063_SwitchFault "VCBATT0 ECU: a063 switch fault";
CM_ SG_ 973 VCBATT0_a064_busSleepReqTimeout "VCBATT0 ECU: a064 bus sleep req timeout";
CM_ SG_ 973 VCBATT0_a423_rtosSleepFailed "VCBATT0 ECU: a423 rtos sleep failed";
CM_ BO_ 1858 "VCBATT1 ECU message: LVBMS status high; frame length from the layout, not yet observed on a vehicle bus";
CM_ SG_ 1858 VCBATT1_lvbmsStatusHighIndex "VCBATT1 ECU: lvbms status high index";
CM_ SG_ 1858 VCBATT1_LVBMS_packCurrent "Electrical current into the low voltage battery; raw 4194303 = signal not available (SNA)";
CM_ SG_ 1858 VCBATT1_LVBMS_packVoltage "Voltage of the low voltage battery; raw 65535 = signal not available (SNA)";
CM_ SG_ 1858 VCBATT1_LVBMS_packTemperature "Temperature of the low voltage battery; raw 511 = signal not available (SNA)";
CM_ SG_ 1858 VCBATT1_LVBMS_MOSTemperature "Temperature of the MOSFET on the low voltage battery; raw 4095 = signal not available (SNA)";
CM_ SG_ 1858 VCBATT1_LVBMS_sumCellVoltage "Sum of the cell voltage of the low voltage battery; raw 65535 = signal not available (SNA)";
CM_ SG_ 1858 VCBATT1_LVBMS_maxBrickVoltage "Maximum cell voltage in the low voltage battery; raw 8191 = signal not available (SNA)";
CM_ SG_ 1858 VCBATT1_LVBMS_maxBrickVoltageInd "VCBATT1 ECU: LVBMS max brick voltage index; raw 255 = signal not available (SNA)";
CM_ SG_ 1858 VCBATT1_totalLVLoadCurrent "Total LV load current of the vehicle.";
CM_ SG_ 1858 VCBATT1_LVPackChargeCurrentLimit "Charge current limit for the LV battery pack.";
CM_ SG_ 1858 VCBATT1_LVPackCurrent "Current of the LV battery pack.";
CM_ SG_ 1858 VCBATT1_LVBMS_estimatedPackOcv "VCBATT1 ECU: LVBMS estimated pack ocv";
CM_ SG_ 1858 VCBATT1_LVBMS_voltageTarget "Voltage target of the LV battery; raw 65535 = signal not available (SNA)";
CM_ SG_ 1858 VCBATT1_LVBMS_currentTarget "Target current requested by the LV battery; raw 262143 = signal not available (SNA)";
CM_ SG_ 1858 VCBATT1_LVBMS_maxAllowedChargeCu "Maximum allowed charge current of the battery; raw 8191 = signal not available (SNA)";
CM_ SG_ 1858 VCBATT1_LVBMS_maxAllowedDischarg "Maximum allowed discharge current of the battery; raw 8191 = signal not available (SNA)";
CM_ SG_ 1858 VCBATT1_LVBMS_MOSCommand "Current state of the MOS command to the LV battery";
CM_ SG_ 1858 VCBATT1_LVBMS_ClearErrorCntrComm "VCBATT1 ECU: LVBMS clear error cntr command";
CM_ SG_ 1858 VCBATT1_LVBMS_ClearHistoricFault "VCBATT1 ECU: LVBMS clear historic fault command";
CM_ SG_ 1858 VCBATT1_LVBMS_ResetLVBMSCommand "Reset command issued to LVBMS, commanded by VC";
CM_ SG_ 1858 VCBATT1_LVBMS_EnterHibernationCo "VCBATT1 ECU: LVBMS enter hibernation command";
CM_ SG_ 1858 VCBATT1_LVBMS_ECPAState "Current state of the E-CPA on the LV battery; raw 3 = signal not available (SNA)";
CM_ SG_ 1858 VCBATT1_LVBMS_MOSState "Current state of the MOS on the LV battery; raw 3 = signal not available (SNA)";
CM_ SG_ 1858 VCBATT1_LVBMS_VehicleState "VCBATT1 ECU: LVBMS vehicle state";
CM_ SG_ 1858 VCBATT1_LVBMS_LINWakeDisabled "VCBATT1 ECU: LVBMS LIN wake disabled";
CM_ SG_ 1858 VCBATT1_LVBMS_chargeType "VCBATT1 ECU: LVBMS charge type; raw 4 = signal not available (SNA)";
CM_ SG_ 1858 VCBATT1_LVBMS_cellAndArcProtEnab "Indicates whether the VC has commanded cell protections to be active";
CM_ SG_ 1858 VCBATT1_LVBMS_avgBrickVoltage "Average voltage of all cells in the low voltage battery; raw 8191 = signal not available (SNA)";
CM_ SG_ 1858 VCBATT1_LVBMS_minBrickVoltage "Minimum cell voltage in the low voltage battery; raw 8191 = signal not available (SNA)";
CM_ SG_ 1858 VCBATT1_LVBMS_minBrickVoltageInd "VCBATT1 ECU: LVBMS min brick voltage index; raw 255 = signal not available (SNA)";
CM_ BO_ 1119 "VCBATT1 ECU message: LV self tests; frame length from the layout, not yet observed on a vehicle bus";
CM_ SG_ 1119 VCBATT1_LVSelfTestsChecksum "VCBATT1 ECU: LV self tests checksum";
CM_ SG_ 1119 VCBATT1_LVSelfTestsCounter "VCBATT1 ECU: LV self tests counter";
CM_ SG_ 1119 VCBATT1_LVSelfTestsIndex "VCBATT1 ECU: LV self tests index";
CM_ SG_ 1119 VCBATT1_lvProtectionSelfTestsEna "VCBATT1 ECU: lv protection self tests enabled";
CM_ SG_ 1119 VCBATT1_startBattDomainOvercurre "VCBATT1 ECU: start batt domain overcurrent self test";
CM_ SG_ 1119 VCBATT1_startBattDomainOvervolta "VCBATT1 ECU: start batt domain overvoltage self test";
CM_ SG_ 1119 VCBATT1_startBattDomainUndervolt "VCBATT1 ECU: start batt domain undervoltage self test";
CM_ SG_ 1119 VCBATT1_startDualPowerLoadsSelfT "VCBATT1 ECU: start dual power loads self test";
CM_ SG_ 1119 VCBATT1_startVCBattBridgeEFuseAS "VCBATT1 ECU: start VC batt bridge e fuse ASIC self test";
CM_ SG_ 1119 VCBATT1_startPCSOVShutdownSelfTe "VCBATT1 ECU: start PCSOV shutdown self test";
CM_ SG_ 1119 VCBATT1_startPCSDomainOvervoltag "VCBATT1 ECU: start PCS domain overvoltage self test";
CM_ SG_ 1119 VCBATT1_startBattDomainUnde_0001 "VCBATT1 ECU: start batt domain undervoltage VC left self test";
CM_ SG_ 1119 VCBATT1_startPCSDomainUndervolta "VCBATT1 ECU: start PCS domain undervoltage self test";
CM_ SG_ 1119 VCBATT1_startVCFrontBridgeEFuseA "VCBATT1 ECU: start VC front bridge e fuse ASIC self test";
CM_ SG_ 1119 VCBATT1_battDomainOvercurrentSel "Self-Test Result.";
CM_ SG_ 1119 VCBATT1_battDomainOvercurre_0001 "Self-Test State; raw 4 = signal not available (SNA)";
CM_ SG_ 1119 VCBATT1_battDomainOvervoltageSel "Self-Test Result.";
CM_ SG_ 1119 VCBATT1_battDomainOvervolta_0001 "Self-Test State; raw 4 = signal not available (SNA)";
CM_ SG_ 1119 VCBATT1_battDomainUndervoltageSe "Self-Test Result.";
CM_ SG_ 1119 VCBATT1_battDomainUndervolt_0001 "Self-Test State; raw 4 = signal not available (SNA)";
CM_ SG_ 1119 VCBATT1_dualPowerLoadsSelfTestRe "Self-Test Result.";
CM_ SG_ 1119 VCBATT1_dualPowerLoadsSelfTestSt "Self-Test State; raw 4 = signal not available (SNA)";
CM_ SG_ 1119 VCBATT1_vcbattBridgeEFuseASICSel "Self-Test Result.";
CM_ SG_ 1119 VCBATT1_vcbattBridgeEFuseAS_0001 "Self-Test State; raw 4 = signal not available (SNA)";
CM_ SG_ 1119 VCBATT1_uvProtectionState "VCBATT1 ECU: uv protection state";
CM_ SG_ 1119 VCBATT1_undervoltageSelfTestFaul "VCBATT1 ECU: undervoltage self test fault injection ready";
CM_ SG_ 1119 VC_selfTestsRunningMode "VCBATT1 ECU: self tests running mode";
BA_DEF_ BO_ "GenMsgCycleTime" INT 0 3600000;
BA_DEF_ BO_ "GenMsgSendType" ENUM "Cyclic","NotUsed","NotUsed","NotUsed","NotUsed","NotUsed","NotUsed","IfActive","NoMsgSendType","NotUsed";
BA_DEF_ BO_ "VFrameFormat" ENUM "StandardCAN","ExtendedCAN","reserved","J1939PG","reserved","reserved","reserved","reserved","reserved","reserved","reserved","reserved","reserved","reserved","StandardCAN_FD","ExtendedCAN_FD";
BA_DEF_ BO_ "CANFD_BRS" ENUM "0","1";
BA_DEF_ SG_ "GenSigSNA" STRING;
BA_DEF_ SG_ "SystemSignalLongSymbol" STRING;
BA_DEF_ SG_ "Confidence" ENUM "validated","plausible","layout-only","contradicted";
BA_DEF_DEF_ "GenMsgCycleTime" 0;
BA_DEF_DEF_ "GenMsgSendType" "NoMsgSendType";
BA_DEF_DEF_ "VFrameFormat" "StandardCAN";
BA_DEF_DEF_ "CANFD_BRS" "1";
BA_DEF_DEF_ "GenSigSNA" "";
BA_DEF_DEF_ "SystemSignalLongSymbol" "";
BA_DEF_DEF_ "Confidence" "layout-only";
BA_ "GenMsgCycleTime" BO_ 820 500;
BA_ "GenMsgSendType" BO_ 820 0;
BA_ "GenMsgCycleTime" BO_ 826 1000;
BA_ "GenMsgSendType" BO_ 826 0;
BA_ "GenMsgCycleTime" BO_ 666 500;
BA_ "GenMsgSendType" BO_ 666 0;
BA_ "GenMsgCycleTime" BO_ 723 1000;
BA_ "GenMsgSendType" BO_ 723 0;
BA_ "GenMsgCycleTime" BO_ 851 500;
BA_ "GenMsgSendType" BO_ 851 0;
BA_ "GenMsgCycleTime" BO_ 991 500;
BA_ "GenMsgSendType" BO_ 991 0;
BA_ "GenMsgCycleTime" BO_ 663 500;
BA_ "GenMsgSendType" BO_ 663 0;
BA_ "GenMsgCycleTime" BO_ 956 1000;
BA_ "GenMsgSendType" BO_ 956 0;
BA_ "GenMsgCycleTime" BO_ 787 500;
BA_ "GenMsgSendType" BO_ 787 0;
BA_ "GenMsgCycleTime" BO_ 839 1000;
BA_ "GenMsgSendType" BO_ 839 0;
BA_ "GenMsgCycleTime" BO_ 627 500;
BA_ "GenMsgSendType" BO_ 627 0;
BA_ "GenMsgCycleTime" BO_ 947 500;
BA_ "GenMsgSendType" BO_ 947 0;
BA_ "GenMsgCycleTime" BO_ 660 500;
BA_ "GenMsgSendType" BO_ 660 0;
BA_ "GenMsgCycleTime" BO_ 1193 500;
BA_ "GenMsgSendType" BO_ 1193 0;
BA_ "GenMsgCycleTime" BO_ 853 1000;
BA_ "GenMsgSendType" BO_ 853 0;
BA_ "GenMsgCycleTime" BO_ 644 500;
BA_ "GenMsgSendType" BO_ 644 0;
BA_ "GenMsgCycleTime" BO_ 595 500;
BA_ "GenMsgSendType" BO_ 595 0;
BA_ "GenMsgCycleTime" BO_ 1565 500;
BA_ "GenMsgSendType" BO_ 1565 0;
BA_ "GenMsgCycleTime" BO_ 1969 10000;
BA_ "GenMsgSendType" BO_ 1969 0;
BA_ "GenMsgCycleTime" BO_ 824 1000;
BA_ "GenMsgSendType" BO_ 824 0;
BA_ "GenMsgCycleTime" BO_ 1285 100;
BA_ "GenMsgSendType" BO_ 1285 0;
BA_ "GenMsgCycleTime" BO_ 1320 1000;
BA_ "GenMsgSendType" BO_ 1320 0;
BA_ "GenMsgCycleTime" BO_ 973 100;
BA_ "GenMsgSendType" BO_ 973 0;
BA_ "GenMsgCycleTime" BO_ 1858 40;
BA_ "GenMsgSendType" BO_ 1858 0;
BA_ "GenMsgCycleTime" BO_ 1119 500;
BA_ "GenMsgSendType" BO_ 1119 0;
BA_ "Confidence" SG_ 820 UI_systemPowerLimit 1;
BA_ "GenSigSNA" SG_ 820 UI_systemPowerLimit "31";
BA_ "Confidence" SG_ 820 UI_pedalMap 0;
BA_ "Confidence" SG_ 820 UI_enableRegenBackfill 0;
BA_ "Confidence" SG_ 820 UI_systemTorqueLimit 1;
BA_ "GenSigSNA" SG_ 820 UI_systemTorqueLimit "63";
BA_ "Confidence" SG_ 820 UI_closureConfirmed 1;
BA_ "Confidence" SG_ 820 UI_regenTorqueMax 0;
BA_ "Confidence" SG_ 820 UI_limitMode 0;
BA_ "Confidence" SG_ 820 UI_factoryCustomerDrivingModeReq 1;
BA_ "SystemSignalLongSymbol" SG_ 820 UI_factoryCustomerDrivingModeReq "UI_factoryCustomerDrivingModeRequest";
BA_ "Confidence" SG_ 820 UI_motorOnMode 0;
BA_ "Confidence" SG_ 820 UI_stoppingMode 0;
BA_ "Confidence" SG_ 820 UI_DIAppSliderDebug 1;
BA_ "Confidence" SG_ 820 UI_speedLimit 0;
BA_ "GenSigSNA" SG_ 820 UI_speedLimit "511";
BA_ "Confidence" SG_ 820 UI_enableSmartShift 0;
BA_ "Confidence" SG_ 820 UI_navVehParallelToRdCanContinue 0;
BA_ "GenSigSNA" SG_ 820 UI_navVehParallelToRdCanContinue "0";
BA_ "Confidence" SG_ 820 UI_powertrainControlCounter 0;
BA_ "Confidence" SG_ 820 UI_powertrainControlChecksum 0;
BA_ "Confidence" SG_ 826 UI_ratedRange 0;
BA_ "Confidence" SG_ 826 UI_whpm 1;
BA_ "Confidence" SG_ 826 UI_soe 0;
BA_ "Confidence" SG_ 826 UI_uSoe 0;
BA_ "Confidence" SG_ 826 UI_softPackLimitPct 1;
BA_ "Confidence" SG_ 826 UI_targetFullPackEnergy 1;
BA_ "Confidence" SG_ 666 UI_seatControlIndex 1;
BA_ "Confidence" SG_ 666 UI_3RSeatChildLock 1;
BA_ "Confidence" SG_ 666 UI_left3RowSeatAdjustmentRequest 1;
BA_ "Confidence" SG_ 666 UI_right3RowSeatAdjustmentReques 1;
BA_ "SystemSignalLongSymbol" SG_ 666 UI_right3RowSeatAdjustmentReques "UI_right3RowSeatAdjustmentRequest";
BA_ "Confidence" SG_ 666 UI_2RLeftSeatFanReq 1;
BA_ "Confidence" SG_ 666 UI_2RRightSeatFanReq 1;
BA_ "SystemSignalLongSymbol" SG_ 666 UI_leftThirdRowSeatRequestFromRe "UI_leftThirdRowSeatRequestFromRearDisplay";
BA_ "SystemSignalLongSymbol" SG_ 666 UI_rightThirdRowSeatRequestFromR "UI_rightThirdRowSeatRequestFromRearDisplay";
BA_ "Confidence" SG_ 666 UI_seatChoreographyStopRequest 1;
BA_ "Confidence" SG_ 723 UI_solarAzimuthAngle 0;
BA_ "GenSigSNA" SG_ 723 UI_solarAzimuthAngle "32768";
BA_ "Confidence" SG_ 723 UI_solarAzimuthAngleCarRef 1;
BA_ "GenSigSNA" SG_ 723 UI_solarAzimuthAngleCarRef "255";
BA_ "Confidence" SG_ 723 UI_isSunUp 0;
BA_ "GenSigSNA" SG_ 723 UI_isSunUp "3";
BA_ "Confidence" SG_ 723 UI_solarElevationAngle 0;
BA_ "GenSigSNA" SG_ 723 UI_solarElevationAngle "127";
BA_ "Confidence" SG_ 723 UI_screenPCBTemperature 0;
BA_ "Confidence" SG_ 723 UI_minsToSunset 0;
BA_ "Confidence" SG_ 723 UI_minsToSunrise 0;
BA_ "Confidence" SG_ 851 UI_touchActive 0;
BA_ "Confidence" SG_ 851 UI_audioActive 0;
BA_ "Confidence" SG_ 851 UI_bluetoothActive 1;
BA_ "Confidence" SG_ 851 UI_cellActive 0;
BA_ "Confidence" SG_ 851 UI_displayReady 0;
BA_ "Confidence" SG_ 851 UI_displayOn 0;
BA_ "Confidence" SG_ 851 UI_wifiActive 0;
BA_ "Confidence" SG_ 851 UI_wifiConnected 0;
BA_ "Confidence" SG_ 851 UI_systemActive 1;
BA_ "Confidence" SG_ 851 UI_readyForDrive 0;
BA_ "Confidence" SG_ 851 UI_cellConnected 0;
BA_ "Confidence" SG_ 851 UI_vpnActive 0;
BA_ "Confidence" SG_ 851 UI_autopilotTrial 1;
BA_ "Confidence" SG_ 851 UI_factoryReset 0;
BA_ "GenSigSNA" SG_ 851 UI_factoryReset "0";
BA_ "Confidence" SG_ 851 UI_gpsActive 0;
BA_ "Confidence" SG_ 851 UI_screenshotActive 1;
BA_ "Confidence" SG_ 851 UI_radioActive 1;
BA_ "Confidence" SG_ 851 UI_cellNetworkTechnology 0;
BA_ "GenSigSNA" SG_ 851 UI_cellNetworkTechnology "15";
BA_ "Confidence" SG_ 851 UI_cellReceiverPower 1;
BA_ "Confidence" SG_ 851 UI_falseTouchCounter 0;
BA_ "Confidence" SG_ 851 UI_developmentCar 1;
BA_ "Confidence" SG_ 851 UI_cameraActive 1;
BA_ "Confidence" SG_ 851 UI_cellSignalBars 0;
BA_ "GenSigSNA" SG_ 851 UI_cellSignalBars "7";
BA_ "Confidence" SG_ 851 UI_trailerModeTelltale 0;
BA_ "Confidence" SG_ 851 UI_pcbTemperature 0;
BA_ "Confidence" SG_ 851 UI_cpuTemperature 0;
BA_ "Confidence" SG_ 991 UI_mobileAppStepCount 1;
BA_ "Confidence" SG_ 991 UI_userRequestSnapshot 1;
BA_ "Confidence" SG_ 991 UI_touchDetected 1;
BA_ "Confidence" SG_ 991 UI_validDeviceForEUSummon 1;
BA_ "Confidence" SG_ 991 UI_locatedAtHome 1;
BA_ "Confidence" SG_ 991 UI_locatedAtWork 1;
BA_ "Confidence" SG_ 991 UI_locatedAtFavorite 1;
BA_ "Confidence" SG_ 991 UI_displayInDarkMode 1;
BA_ "Confidence" SG_ 991 UI_userActivity 0;
BA_ "Confidence" SG_ 991 UI_activeTouchPoints 0;
BA_ "Confidence" SG_ 991 UI_linkState 0;
BA_ "Confidence" SG_ 991 UI_sentryModeState 1;
BA_ "GenSigSNA" SG_ 991 UI_sentryModeState "6";
BA_ "Confidence" SG_ 991 UI_autopilotSentryRequest 0;
BA_ "Confidence" SG_ 991 UI_mobileAppConnected 0;
BA_ "Confidence" SG_ 991 UI_phoneLeftInCabin 0;
BA_ "Confidence" SG_ 991 UI_autoshiftDRState 0;
BA_ "Confidence" SG_ 991 UI_wifiBtModuleType 0;
BA_ "Confidence" SG_ 991 UI_sohHealthStatus 1;
BA_ "Confidence" SG_ 991 UI_selfParkState 0;
BA_ "GenSigSNA" SG_ 991 UI_selfParkState "255";
BA_ "Confidence" SG_ 991 UI_summonDeviceIndex 0;
BA_ "Confidence" SG_ 991 UI_fullScreenMode 0;
BA_ "Confidence" SG_ 991 UI_sentryModeCameraDetection 1;
BA_ "Confidence" SG_ 991 UI_wakeOnIPActive 1;
BA_ "Confidence" SG_ 991 UI_sapActive 1;
BA_ "Confidence" SG_ 991 UI_sapClients 1;
BA_ "Confidence" SG_ 991 UI_connectivityStandbyActive 1;
BA_ "Confidence" SG_ 663 UI_adaptiveRideRequest 0;
BA_ "Confidence" SG_ 663 UI_suspensionLoweringRequest 1;
BA_ "GenSigSNA" SG_ 663 UI_suspensionLoweringRequest "3";
BA_ "Confidence" SG_ 663 UI_geofenceLevelingRequest 0;
BA_ "GenSigSNA" SG_ 663 UI_geofenceLevelingRequest "5";
BA_ "Confidence" SG_ 663 UI_jackModeToggleRequest 1;
BA_ "Confidence" SG_ 663 UI_adaptiveTuningRequest0 1;
BA_ "Confidence" SG_ 663 UI_adaptiveTuningRequest1 1;
BA_ "Confidence" SG_ 663 UI_roadRoughnessLookahead 1;
BA_ "GenSigSNA" SG_ 663 UI_roadRoughnessLookahead "127";
BA_ "Confidence" SG_ 663 UI_roadRoughnessStart 1;
BA_ "GenSigSNA" SG_ 663 UI_roadRoughnessStart "31";
BA_ "Confidence" SG_ 663 UI_mapVersionUsed 1;
BA_ "GenSigSNA" SG_ 663 UI_mapVersionUsed "255";
BA_ "Confidence" SG_ 663 UI_suspensionLevelRequest 1;
BA_ "Confidence" SG_ 956 UI_sendCalibrateTireRequest 0;
BA_ "Confidence" SG_ 956 UI_setRCPFront 0;
BA_ "Confidence" SG_ 956 UI_setRCPRear 0;
BA_ "Confidence" SG_ 787 UI_trackModeRequest 0;
BA_ "Confidence" SG_ 787 UI_trackRotationTendency 1;
BA_ "Confidence" SG_ 787 UI_trackStabilityAssist 1;
BA_ "Confidence" SG_ 787 UI_trackPostCooling 1;
BA_ "Confidence" SG_ 787 UI_trackCmpOverclock 1;
BA_ "Confidence" SG_ 787 UI_trackModeBrakeTemps 1;
BA_ "Confidence" SG_ 787 UI_trackDrivePowerAvailability 0;
BA_ "Confidence" SG_ 787 UI_stabilityModeRequest 1;
BA_ "Confidence" SG_ 787 UI_trackModeSettingsCounter 0;
BA_ "Confidence" SG_ 787 UI_trackModeSettingsChecksum 0;
BA_ "Confidence" SG_ 839 UI_tripPlanningActive 0;
BA_ "Confidence" SG_ 839 UI_navToSupercharger 0;
BA_ "Confidence" SG_ 839 UI_navFastchargerType 0;
BA_ "Confidence" SG_ 839 UI_battPreconditionOnNavState 0;
BA_ "Confidence" SG_ 839 UI_requestActiveBatteryHeating 0;
BA_ "Confidence" SG_ 839 UI_battPreconditionOnNavPowerReq 0;
BA_ "GenSigSNA" SG_ 839 UI_battPreconditionOnNavPowerReq "127";
BA_ "Confidence" SG_ 839 UI_battPreconditionOnNavTargetT 0;
BA_ "GenSigSNA" SG_ 839 UI_battPreconditionOnNavTargetT "255";
BA_ "Confidence" SG_ 839 UI_ambientTempAtDestination 1;
BA_ "GenSigSNA" SG_ 839 UI_ambientTempAtDestination "128";
BA_ "Confidence" SG_ 839 UI_tripPlanChargingTargetPercent 1;
BA_ "GenSigSNA" SG_ 839 UI_tripPlanChargingTargetPercent "1023";
BA_ "Confidence" SG_ 839 UI_energyAtDestination 0;
BA_ "GenSigSNA" SG_ 839 UI_energyAtDestination "32768";
BA_ "Confidence" SG_ 627 UI_powerStateRequest 0;
BA_ "Confidence" SG_ 627 UI_childDoorLockOnRight 0;
BA_ "Confidence" SG_ 627 UI_frontFogSwitch 0;
BA_ "Confidence" SG_ 627 UI_summonActive 0;
BA_ "Confidence" SG_ 627 UI_frunkRequest 0;
BA_ "Confidence" SG_ 627 UI_wiperMode 0;
BA_ "GenSigSNA" SG_ 627 UI_wiperMode "0";
BA_ "Confidence" SG_ 627 UI_steeringBacklightEnabled 1;
BA_ "Confidence" SG_ 627 UI_steeringButtonMode 0;
BA_ "Confidence" SG_ 627 UI_walkUpUnlock 0;
BA_ "Confidence" SG_ 627 UI_walkAwayLock 0;
BA_ "Confidence" SG_ 627 UI_unlockOnPark 0;
BA_ "Confidence" SG_ 627 UI_globalUnlockOn 0;
BA_ "Confidence" SG_ 627 UI_childDoorLockOnLeft 0;
BA_ "Confidence" SG_ 627 UI_lockRequest 0;
BA_ "GenSigSNA" SG_ 627 UI_lockRequest "7";
BA_ "Confidence" SG_ 627 UI_alarmEnabled 0;
BA_ "Confidence" SG_ 627 UI_intrusionSensorOn 1;
BA_ "Confidence" SG_ 627 UI_stop12vSupport 0;
BA_ "Confidence" SG_ 627 UI_rearFogSwitch 0;
BA_ "Confidence" SG_ 627 UI_mirrorFoldRequest 0;
BA_ "GenSigSNA" SG_ 627 UI_mirrorFoldRequest "3";
BA_ "Confidence" SG_ 627 UI_mirrorHeatRequest 0;
BA_ "Confidence" SG_ 627 UI_remoteStartRequest 0;
BA_ "GenSigSNA" SG_ 627 UI_remoteStartRequest "4";
BA_ "Confidence" SG_ 627 UI_seeYouHomeLightingOn 0;
BA_ "Confidence" SG_ 627 UI_powerOff 0;
BA_ "Confidence" SG_ 627 UI_displayBrightnessLevel 0;
BA_ "GenSigSNA" SG_ 627 UI_displayBrightnessLevel "255";
BA_ "Confidence" SG_ 627 UI_ambientLightingEnabled 1;
BA_ "Confidence" SG_ 627 UI_autoHighBeamEnabled 0;
BA_ "Confidence" SG_ 627 UI_frontLeftSeatHeatReq 0;
BA_ "Confidence" SG_ 627 UI_frontRightSeatHeatReq 0;
BA_ "Confidence" SG_ 627 UI_rearLeftSeatHeatReq 0;
BA_ "Confidence" SG_ 627 UI_rearCenterSeatHeatReq 0;
BA_ "Confidence" SG_ 627 UI_rearRightSeatHeatReq 0;
BA_ "Confidence" SG_ 627 UI_autoFoldMirrorsOn 0;
BA_ "Confidence" SG_ 627 UI_mirrorDipOnReverse 0;
BA_ "Confidence" SG_ 627 UI_remoteClosureRequest 0;
BA_ "GenSigSNA" SG_ 627 UI_remoteClosureRequest "3";
BA_ "Confidence" SG_ 627 UI_wiperRequest 0;
BA_ "GenSigSNA" SG_ 627 UI_wiperRequest "0";
BA_ "Confidence" SG_ 627 UI_domeLightSwitch 0;
BA_ "Confidence" SG_ 627 UI_honkHorn 1;
BA_ "Confidence" SG_ 627 UI_driveStateRequest 1;
BA_ "Confidence" SG_ 627 UI_rearWindowLockout 1;
BA_ "Confidence" SG_ 947 UI_gloveboxRequest 0;
BA_ "Confidence" SG_ 947 UI_trunkRequest 0;
BA_ "Confidence" SG_ 947 UI_UMCUpdateInhibit 1;
BA_ "Confidence" SG_ 947 UI_WCUpdateInhibit 1;
BA_ "Confidence" SG_ 947 UI_soundHornOnLock 1;
BA_ "Confidence" SG_ 947 UI_locksPanelActive 1;
BA_ "Confidence" SG_ 947 UI_PINToDriveEnabled 0;
BA_ "Confidence" SG_ 947 UI_PINToDrivePassed 0;
BA_ "Confidence" SG_ 947 UI_disableMirrorAutoDim 0;
BA_ "Confidence" SG_ 947 UI_lightSwitch 0;
BA_ "GenSigSNA" SG_ 947 UI_lightSwitch "4";
BA_ "Confidence" SG_ 947 UI_readyToAddKey 0;
BA_ "Confidence" SG_ 947 UI_alarmTriggerRequest 0;
BA_ "Confidence" SG_ 947 UI_VCSECFeature1 1;
BA_ "Confidence" SG_ 947 UI_VCLEFTFeature1 1;
BA_ "Confidence" SG_ 947 UI_summonState 1;
BA_ "GenSigSNA" SG_ 947 UI_summonState "0";
BA_ "Confidence" SG_ 947 UI_displayOnForUser 0;
BA_ "Confidence" SG_ 947 UI_freeRollModeRequest 1;
BA_ "Confidence" SG_ 947 UI_BLEPushNotificationRequest 0;
BA_ "Confidence" SG_ 947 UI_pairKeyQRCodeDisplaying 1;
BA_ "Confidence" SG_ 947 UI_keepAutopilotAwake 0;
BA_ "Confidence" SG_ 947 UI_batteryPreconditioningRequest 0;
BA_ "Confidence" SG_ 947 UI_coastDownMode 1;
BA_ "Confidence" SG_ 947 UI_autopilotPowerStateRequest 0;
BA_ "Confidence" SG_ 947 UI_shorted12VCellTestMode 1;
BA_ "Confidence" SG_ 947 UI_autoRollWindowsOnLockEnable 0;
BA_ "Confidence" SG_ 947 UI_virtualPitchSensorOverrideOKF 1;
BA_ "SystemSignalLongSymbol" SG_ 947 UI_virtualPitchSensorOverrideOKF "UI_virtualPitchSensorOverrideOKForAim";
BA_ "Confidence" SG_ 947 UI_conditionalLoggingEnabledVCSE 1;
BA_ "SystemSignalLongSymbol" SG_ 947 UI_conditionalLoggingEnabledVCSE "UI_conditionalLoggingEnabledVCSEC";
BA_ "Confidence" SG_ 947 UI_WC3UpdateInhibit 1;
BA_ "Confidence" SG_ 947 UI_steeringWheelHeatReq 0;
BA_ "Confidence" SG_ 947 UI_disableHorn 0;
BA_ "Confidence" SG_ 947 UI_frontLeftSeatFanReq 0;
BA_ "Confidence" SG_ 947 UI_frontRightSeatAutoClimateReq 0;
BA_ "Confidence" SG_ 947 UI_frontRightSeatFanReq 0;
BA_ "Confidence" SG_ 947 UI_3RLeftSeatHeatReq 0;
BA_ "Confidence" SG_ 947 UI_3RRightSeatHeatReq 0;
BA_ "Confidence" SG_ 947 UI_sleepFeature1 1;
BA_ "Confidence" SG_ 947 UI_dcr12VThreshold 1;
BA_ "Confidence" SG_ 947 UI_frontLeftSeatAutoClimateReq 0;
BA_ "Confidence" SG_ 947 UI_wiperHeaterReq 0;
BA_ "Confidence" SG_ 947 UI_tireSeason 1;
BA_ "Confidence" SG_ 947 UI_saveTireConfigReq 1;
BA_ "Confidence" SG_ 947 UI_silentAlarm 0;
BA_ "Confidence" SG_ 947 UI_sleepFeature2 1;
BA_ "Confidence" SG_ 660 UI_lightFlashRequest 0;
BA_ "Confidence" SG_ 660 UI_keylessDrivingEnabled 1;
BA_ "Confidence" SG_ 660 UI_phoneCallActive 0;
BA_ "Confidence" SG_ 660 UI_drivingSideVEH 1;
BA_ "Confidence" SG_ 660 UI_keyPairResponse 1;
BA_ "Confidence" SG_ 660 UI_lightShowClosuresEnabled 0;
BA_ "Confidence" SG_ 660 UI_steeringWheelHeatAutoReq 0;
BA_ "Confidence" SG_ 660 UI_steeringWheelHeatLevelReq 0;
BA_ "Confidence" SG_ 660 UI_headlightPulseRequest 0;
BA_ "Confidence" SG_ 660 UI_VCSECFeature2 1;
BA_ "Confidence" SG_ 660 UI_VCSECFeature3 1;
BA_ "Confidence" SG_ 660 UI_VCSECFeature4 1;
BA_ "Confidence" SG_ 660 UI_VCSECFeature5 1;
BA_ "Confidence" SG_ 660 UI_shortHornRequest 1;
BA_ "Confidence" SG_ 660 UI_packTempLoggingRequest 1;
BA_ "Confidence" SG_ 660 UI_UMC3UpdateInhibit 1;
BA_ "Confidence" SG_ 660 UI_handsFreeTrunk 1;
BA_ "Confidence" SG_ 660 UI_displayRedShiftActive 0;
BA_ "Confidence" SG_ 660 UI_handsFreeFrunk 1;
BA_ "Confidence" SG_ 660 UI_fasciaCameraWashRequest 0;
BA_ "Confidence" SG_ 660 UI_autoClosuresExcludeHome 1;
BA_ "Confidence" SG_ 660 UI_leftRearSeatAdjustmentRequest 0;
BA_ "Confidence" SG_ 660 UI_rightRearSeatAdjustmentReques 0;
BA_ "SystemSignalLongSymbol" SG_ 660 UI_rightRearSeatAdjustmentReques "UI_rightRearSeatAdjustmentRequest";
BA_ "Confidence" SG_ 660 UI_blindSpotIndicatorLightReques 0;
BA_ "SystemSignalLongSymbol" SG_ 660 UI_blindSpotIndicatorLightReques "UI_blindSpotIndicatorLightRequest";
BA_ "Confidence" SG_ 660 UI_etcBluetoothControl 1;
BA_ "Confidence" SG_ 660 UI_keepOnAccessoryPortsReq 0;
BA_ "Confidence" SG_ 660 UI_fasciaCameraShown 0;
BA_ "Confidence" SG_ 660 UI_rearSeatChildLock 0;
BA_ "Confidence" SG_ 660 UI_windowPercentageRequest 0;
BA_ "Confidence" SG_ 660 UI_windowRequestedFL 0;
BA_ "Confidence" SG_ 660 UI_windowRequestedFR 0;
BA_ "Confidence" SG_ 660 UI_windowRequestedRL 0;
BA_ "Confidence" SG_ 660 UI_windowRequestedRR 0;
BA_ "Confidence" SG_ 660 UI_windowRequest 1;
BA_ "Confidence" SG_ 660 UI_closeTrunkRequest 0;
BA_ "Confidence" SG_ 660 UI_childPresenceDetectionDisable 0;
BA_ "SystemSignalLongSymbol" SG_ 660 UI_childPresenceDetectionDisable "UI_childPresenceDetectionDisableRequest";
BA_ "Confidence" SG_ 660 UI_V2LAUpdateInhibit 1;
BA_ "Confidence" SG_ 660 UI_userPresenceDetectionEnabled 1;
BA_ "Confidence" SG_ 660 UI_derivedLoadshedFeature 0;
BA_ "Confidence" SG_ 660 UI_rearSeatFoldConfirmed 1;
BA_ "Confidence" SG_ 660 UI_leftRearSeatRequestFromRearDi 1;
BA_ "SystemSignalLongSymbol" SG_ 660 UI_leftRearSeatRequestFromRearDi "UI_leftRearSeatRequestFromRearDisplay";
BA_ "Confidence" SG_ 660 UI_selfParkStandingBy 0;
BA_ "Confidence" SG_ 660 UI_rightRearSeatRequestFromRearD 1;
BA_ "SystemSignalLongSymbol" SG_ 660 UI_rightRearSeatRequestFromRearD "UI_rightRearSeatRequestFromRearDisplay";
BA_ "Confidence" SG_ 1193 UI_firstRowLeftDomeLightRequest 0;
BA_ "Confidence" SG_ 1193 UI_firstRowRightDomeLightRequest 0;
BA_ "Confidence" SG_ 1193 UI_secondRowLeftDomeLightRequest 0;
BA_ "Confidence" SG_ 1193 UI_secondRowCenterDomeLightReque 0;
BA_ "SystemSignalLongSymbol" SG_ 1193 UI_secondRowCenterDomeLightReque "UI_secondRowCenterDomeLightRequest";
BA_ "Confidence" SG_ 1193 UI_secondRowRightDomeLightReques 0;
BA_ "SystemSignalLongSymbol" SG_ 1193 UI_secondRowRightDomeLightReques "UI_secondRowRightDomeLightRequest";
BA_ "Confidence" SG_ 1193 UI_thirdRowLeftDomeLightRequest 0;
BA_ "Confidence" SG_ 1193 UI_thirdRowRightDomeLightRequest 0;
BA_ "Confidence" SG_ 853 UI_coolantFlowRequest 0;
BA_ "Confidence" SG_ 853 UI_inletActiveCoolTarget 0;
BA_ "Confidence" SG_ 853 UI_disableHVPTThermalLoads 0;
BA_ "Confidence" SG_ 853 UI_enableCompLiquidPumpOut 1;
BA_ "Confidence" SG_ 853 UI_enableCOP1HighSHOperation 1;
BA_ "Confidence" SG_ 853 UI_enableIncreasedEvapRampRate 1;
BA_ "Confidence" SG_ 853 UI_enableCOP1BatteryHeating 1;
BA_ "Confidence" SG_ 853 UI_enableCOP1CabinHeatingBattery 1;
BA_ "SystemSignalLongSymbol" SG_ 853 UI_enableCOP1CabinHeatingBattery "UI_enableCOP1CabinHeatingBatteryHeating";
BA_ "Confidence" SG_ 853 UI_enableLouverAutoDetection 1;
BA_ "Confidence" SG_ 853 UI_enableUserFacingLowFlowDelive 1;
BA_ "SystemSignalLongSymbol" SG_ 853 UI_enableUserFacingLowFlowDelive "UI_enableUserFacingLowFlowDeliveryAlert";
BA_ "Confidence" SG_ 853 UI_disableHvacCameraOnlyDefog 1;
BA_ "Confidence" SG_ 853 UI_enableEXVFastCalibration 1;
BA_ "Confidence" SG_ 853 UI_enableThermalDriverlessSelfTe 1;
BA_ "SystemSignalLongSymbol" SG_ 853 UI_enableThermalDriverlessSelfTe "UI_enableThermalDriverlessSelfTest";
BA_ "Confidence" SG_ 853 UI_enableCoolantDasTarget 1;
BA_ "Confidence" SG_ 853 UI_geofencedLiftgateHeight 1;
BA_ "GenSigSNA" SG_ 853 UI_geofencedLiftgateHeight "255";
BA_ "Confidence" SG_ 853 UI_convenienceFeatureLimit 0;
BA_ "Confidence" SG_ 853 UI_allowConvenienceFeatures 0;
BA_ "Confidence" SG_ 853 UI_enableConservativeBatteryHeat 1;
BA_ "SystemSignalLongSymbol" SG_ 853 UI_enableConservativeBatteryHeat "UI_enableConservativeBatteryHeating";
BA_ "Confidence" SG_ 853 UI_enableDefaultApTempTarget 1;
BA_ "Confidence" SG_ 853 UI_enableHVACCompressorWasteHeat 1;
BA_ "Confidence" SG_ 853 UI_disablePhoneChargingPads 0;
BA_ "Confidence" SG_ 853 UI_isAtTeslaFacility 1;
BA_ "Confidence" SG_ 853 UI_enableThermalPowerBudget 1;
BA_ "Confidence" SG_ 853 UI_enableHVACAPFanHeaterControl 1;
BA_ "Confidence" SG_ 853 UI_enableAutopilotAirPurge 1;
BA_ "Confidence" SG_ 853 UI_enableForcedAirCameraHeater 1;
BA_ "Confidence" SG_ 853 UI_enableHvacCOPOnUndeliveredVeh 1;
BA_ "Confidence" SG_ 644 UI_factoryMode 1;
BA_ "Confidence" SG_ 644 UI_transportMode 0;
BA_ "Confidence" SG_ 644 UI_showroomMode 0;
BA_ "Confidence" SG_ 644 UI_serviceMode 0;
BA_ "Confidence" SG_ 644 UI_isDelivered 1;
BA_ "Confidence" SG_ 644 UI_hasEverBeenDelivered 1;
BA_ "Confidence" SG_ 644 UI_homelinkV2Command0 1;
BA_ "Confidence" SG_ 644 UI_homelinkV2Command1 1;
BA_ "Confidence" SG_ 644 UI_homelinkV2Command2 1;
BA_ "Confidence" SG_ 644 UI_carWashMode 0;
BA_ "Confidence" SG_ 644 UI_valetMode 1;
BA_ "Confidence" SG_ 644 UI_gameMode 0;
BA_ "Confidence" SG_ 644 UI_diagnosticsAllowed 1;
BA_ "Confidence" SG_ 644 UI_serviceModePlus 0;
BA_ "Confidence" SG_ 644 UI_premiumAmpPowerOff 0;
BA_ "Confidence" SG_ 644 UI_signedCmdHardLocked 1;
BA_ "Confidence" SG_ 644 UI_signedCmdServiceMode 1;
BA_ "Confidence" SG_ 644 UI_closureEasterEggStatus 1;
BA_ "Confidence" SG_ 644 UI_lightShowType 0;
BA_ "Confidence" SG_ 644 UI_sohTestRequest 1;
BA_ "Confidence" SG_ 644 UI_upkeepMode 0;
BA_ "Confidence" SG_ 644 UI_vehicleModesCounter 0;
BA_ "Confidence" SG_ 644 UI_vehicleModesChecksum 0;
BA_ "Confidence" SG_ 595 UI_ventPanelControlRequestIndex 0;
BA_ "Confidence" SG_ 595 UI_ventPanelLeftPositionX 0;
BA_ "Confidence" SG_ 595 UI_ventPanelLeftPositionY 0;
BA_ "Confidence" SG_ 595 UI_ventPanelLeftLateralSplit 0;
BA_ "Confidence" SG_ 595 UI_ventPanelRightPositionX 0;
BA_ "Confidence" SG_ 595 UI_ventPanelRightPositionY 0;
BA_ "Confidence" SG_ 595 UI_ventPanelRightLateralSplit 0;
BA_ "Confidence" SG_ 595 UI_ventPanelLeftLateralMode 0;
BA_ "Confidence" SG_ 595 UI_ventPanelRightLateralMode 0;
BA_ "Confidence" SG_ 595 UI_hvacReqActiveVents 0;
BA_ "Confidence" SG_ 595 UI_vent2RLeftPositionX 0;
BA_ "Confidence" SG_ 595 UI_vent2RLeftPositionY 0;
BA_ "Confidence" SG_ 595 UI_vent2RRightPositionX 0;
BA_ "Confidence" SG_ 595 UI_vent2RRightPositionY 0;
BA_ "Confidence" SG_ 595 UI_hvacReqThirdRowState 0;
BA_ "Confidence" SG_ 1565 UI_weatherSvcTimeSinceLast 0;
BA_ "GenSigSNA" SG_ 1565 UI_weatherSvcTimeSinceLast "127";
BA_ "Confidence" SG_ 1565 UI_weatherSvcWindDir 1;
BA_ "GenSigSNA" SG_ 1565 UI_weatherSvcWindDir "255";
BA_ "Confidence" SG_ 1565 UI_weatherSvcTemperature 1;
BA_ "GenSigSNA" SG_ 1565 UI_weatherSvcTemperature "255";
BA_ "Confidence" SG_ 1565 UI_weatherSvcHumidity 1;
BA_ "GenSigSNA" SG_ 1565 UI_weatherSvcHumidity "63";
BA_ "Confidence" SG_ 1565 UI_weatherSvcDewPoint 1;
BA_ "GenSigSNA" SG_ 1565 UI_weatherSvcDewPoint "255";
BA_ "Confidence" SG_ 1565 UI_weatherSvcCloudCover 1;
BA_ "GenSigSNA" SG_ 1565 UI_weatherSvcCloudCover "63";
BA_ "Confidence" SG_ 1565 UI_weatherSvcPrecipProb 1;
BA_ "GenSigSNA" SG_ 1565 UI_weatherSvcPrecipProb "63";
BA_ "Confidence" SG_ 1565 UI_weatherSvcRaining 1;
BA_ "Confidence" SG_ 1565 UI_weatherSvcSnowing 1;
BA_ "Confidence" SG_ 1565 UI_weatherSvcWindSpeed 1;
BA_ "GenSigSNA" SG_ 1565 UI_weatherSvcWindSpeed "63";
BA_ "Confidence" SG_ 1969 UI_weatherSvcForecastMuxIndex 0;
BA_ "Confidence" SG_ 1969 UI_weatherSvcForecastTempC_hour1 1;
BA_ "GenSigSNA" SG_ 1969 UI_weatherSvcForecastTempC_hour1 "255";
BA_ "Confidence" SG_ 1969 UI_weatherSvcForecastTempC_hour2 1;
BA_ "GenSigSNA" SG_ 1969 UI_weatherSvcForecastTempC_hour2 "255";
BA_ "Confidence" SG_ 1969 UI_weatherSvcForecastTempC_hour3 1;
BA_ "GenSigSNA" SG_ 1969 UI_weatherSvcForecastTempC_hour3 "255";
BA_ "Confidence" SG_ 1969 UI_weatherSvcForecastTempC_hour4 1;
BA_ "GenSigSNA" SG_ 1969 UI_weatherSvcForecastTempC_hour4 "255";
BA_ "Confidence" SG_ 1969 UI_weatherSvcForecastTempC_hour5 1;
BA_ "GenSigSNA" SG_ 1969 UI_weatherSvcForecastTempC_hour5 "255";
BA_ "Confidence" SG_ 1969 UI_weatherSvcForecastTempC_hour6 1;
BA_ "GenSigSNA" SG_ 1969 UI_weatherSvcForecastTempC_hour6 "255";
BA_ "Confidence" SG_ 1969 UI_weatherSvcForecastTempC_hour7 1;
BA_ "GenSigSNA" SG_ 1969 UI_weatherSvcForecastTempC_hour7 "255";
BA_ "Confidence" SG_ 1969 UI_weatherSvcForecastTempC_hour8 1;
BA_ "GenSigSNA" SG_ 1969 UI_weatherSvcForecastTempC_hour8 "255";
BA_ "Confidence" SG_ 1969 UI_weatherSvcForecastTempC_hour9 1;
BA_ "GenSigSNA" SG_ 1969 UI_weatherSvcForecastTempC_hour9 "255";
BA_ "Confidence" SG_ 1969 UI_weatherSvcForecastTempC__0001 1;
BA_ "GenSigSNA" SG_ 1969 UI_weatherSvcForecastTempC__0001 "255";
BA_ "SystemSignalLongSymbol" SG_ 1969 UI_weatherSvcForecastTempC__0001 "UI_weatherSvcForecastTempC_hour10";
BA_ "Confidence" SG_ 1969 UI_weatherSvcForecastTempC__0002 1;
BA_ "GenSigSNA" SG_ 1969 UI_weatherSvcForecastTempC__0002 "255";
BA_ "SystemSignalLongSymbol" SG_ 1969 UI_weatherSvcForecastTempC__0002 "UI_weatherSvcForecastTempC_hour11";
BA_ "Confidence" SG_ 1969 UI_weatherSvcForecastHumidity_ho 1;
BA_ "GenSigSNA" SG_ 1969 UI_weatherSvcForecastHumidity_ho "63";
BA_ "SystemSignalLongSymbol" SG_ 1969 UI_weatherSvcForecastHumidity_ho "UI_weatherSvcForecastHumidity_hour1";
BA_ "Confidence" SG_ 1969 UI_weatherSvcForecastHumidi_0003 1;
BA_ "GenSigSNA" SG_ 1969 UI_weatherSvcForecastHumidi_0003 "63";
BA_ "SystemSignalLongSymbol" SG_ 1969 UI_weatherSvcForecastHumidi_0003 "UI_weatherSvcForecastHumidity_hour2";
BA_ "Confidence" SG_ 1969 UI_weatherSvcForecastHumidi_0004 1;
BA_ "GenSigSNA" SG_ 1969 UI_weatherSvcForecastHumidi_0004 "63";
BA_ "SystemSignalLongSymbol" SG_ 1969 UI_weatherSvcForecastHumidi_0004 "UI_weatherSvcForecastHumidity_hour3";
BA_ "Confidence" SG_ 1969 UI_weatherSvcForecastHumidi_0005 1;
BA_ "GenSigSNA" SG_ 1969 UI_weatherSvcForecastHumidi_0005 "63";
BA_ "SystemSignalLongSymbol" SG_ 1969 UI_weatherSvcForecastHumidi_0005 "UI_weatherSvcForecastHumidity_hour4";
BA_ "Confidence" SG_ 1969 UI_weatherSvcForecastHumidi_0006 1;
BA_ "GenSigSNA" SG_ 1969 UI_weatherSvcForecastHumidi_0006 "63";
BA_ "SystemSignalLongSymbol" SG_ 1969 UI_weatherSvcForecastHumidi_0006 "UI_weatherSvcForecastHumidity_hour5";
BA_ "Confidence" SG_ 1969 UI_weatherSvcForecastHumidi_0007 1;
BA_ "GenSigSNA" SG_ 1969 UI_weatherSvcForecastHumidi_0007 "63";
BA_ "SystemSignalLongSymbol" SG_ 1969 UI_weatherSvcForecastHumidi_0007 "UI_weatherSvcForecastHumidity_hour6";
BA_ "Confidence" SG_ 1969 UI_weatherSvcForecastHumidi_0008 1;
BA_ "GenSigSNA" SG_ 1969 UI_weatherSvcForecastHumidi_0008 "63";
BA_ "SystemSignalLongSymbol" SG_ 1969 UI_weatherSvcForecastHumidi_0008 "UI_weatherSvcForecastHumidity_hour7";
BA_ "Confidence" SG_ 1969 UI_weatherSvcForecastHumidi_0009 1;
BA_ "GenSigSNA" SG_ 1969 UI_weatherSvcForecastHumidi_0009 "63";
BA_ "SystemSignalLongSymbol" SG_ 1969 UI_weatherSvcForecastHumidi_0009 "UI_weatherSvcForecastHumidity_hour8";
BA_ "Confidence" SG_ 1969 UI_weatherSvcForecastHumidi_0010 1;
BA_ "GenSigSNA" SG_ 1969 UI_weatherSvcForecastHumidi_0010 "63";
BA_ "SystemSignalLongSymbol" SG_ 1969 UI_weatherSvcForecastHumidi_0010 "UI_weatherSvcForecastHumidity_hour9";
BA_ "Confidence" SG_ 1969 UI_weatherSvcForecastHumidi_0001 1;
BA_ "GenSigSNA" SG_ 1969 UI_weatherSvcForecastHumidi_0001 "63";
BA_ "SystemSignalLongSymbol" SG_ 1969 UI_weatherSvcForecastHumidi_0001 "UI_weatherSvcForecastHumidity_hour10";
BA_ "Confidence" SG_ 1969 UI_weatherSvcForecastHumidi_0002 1;
BA_ "GenSigSNA" SG_ 1969 UI_weatherSvcForecastHumidi_0002 "63";
BA_ "SystemSignalLongSymbol" SG_ 1969 UI_weatherSvcForecastHumidi_0002 "UI_weatherSvcForecastHumidity_hour11";
BA_ "Confidence" SG_ 1969 UI_weatherSvcForecastWindSpeedKp 1;
BA_ "GenSigSNA" SG_ 1969 UI_weatherSvcForecastWindSpeedKp "63";
BA_ "SystemSignalLongSymbol" SG_ 1969 UI_weatherSvcForecastWindSpeedKp "UI_weatherSvcForecastWindSpeedKph_hour1";
BA_ "Confidence" SG_ 1969 UI_weatherSvcForecastWindSp_0003 1;
BA_ "GenSigSNA" SG_ 1969 UI_weatherSvcForecastWindSp_0003 "63";
BA_ "SystemSignalLongSymbol" SG_ 1969 UI_weatherSvcForecastWindSp_0003 "UI_weatherSvcForecastWindSpeedKph_hour2";
BA_ "Confidence" SG_ 1969 UI_weatherSvcForecastWindSp_0004 1;
BA_ "GenSigSNA" SG_ 1969 UI_weatherSvcForecastWindSp_0004 "63";
BA_ "SystemSignalLongSymbol" SG_ 1969 UI_weatherSvcForecastWindSp_0004 "UI_weatherSvcForecastWindSpeedKph_hour3";
BA_ "Confidence" SG_ 1969 UI_weatherSvcForecastWindSp_0005 1;
BA_ "GenSigSNA" SG_ 1969 UI_weatherSvcForecastWindSp_0005 "63";
BA_ "SystemSignalLongSymbol" SG_ 1969 UI_weatherSvcForecastWindSp_0005 "UI_weatherSvcForecastWindSpeedKph_hour4";
BA_ "Confidence" SG_ 1969 UI_weatherSvcForecastWindSp_0006 1;
BA_ "GenSigSNA" SG_ 1969 UI_weatherSvcForecastWindSp_0006 "63";
BA_ "SystemSignalLongSymbol" SG_ 1969 UI_weatherSvcForecastWindSp_0006 "UI_weatherSvcForecastWindSpeedKph_hour5";
BA_ "Confidence" SG_ 1969 UI_weatherSvcForecastWindSp_0007 1;
BA_ "GenSigSNA" SG_ 1969 UI_weatherSvcForecastWindSp_0007 "63";
BA_ "SystemSignalLongSymbol" SG_ 1969 UI_weatherSvcForecastWindSp_0007 "UI_weatherSvcForecastWindSpeedKph_hour6";
BA_ "Confidence" SG_ 1969 UI_weatherSvcForecastWindSp_0008 1;
BA_ "GenSigSNA" SG_ 1969 UI_weatherSvcForecastWindSp_0008 "63";
BA_ "SystemSignalLongSymbol" SG_ 1969 UI_weatherSvcForecastWindSp_0008 "UI_weatherSvcForecastWindSpeedKph_hour7";
BA_ "Confidence" SG_ 1969 UI_weatherSvcForecastWindSp_0009 1;
BA_ "GenSigSNA" SG_ 1969 UI_weatherSvcForecastWindSp_0009 "63";
BA_ "SystemSignalLongSymbol" SG_ 1969 UI_weatherSvcForecastWindSp_0009 "UI_weatherSvcForecastWindSpeedKph_hour8";
BA_ "Confidence" SG_ 1969 UI_weatherSvcForecastWindSp_0010 1;
BA_ "GenSigSNA" SG_ 1969 UI_weatherSvcForecastWindSp_0010 "63";
BA_ "SystemSignalLongSymbol" SG_ 1969 UI_weatherSvcForecastWindSp_0010 "UI_weatherSvcForecastWindSpeedKph_hour9";
BA_ "Confidence" SG_ 1969 UI_weatherSvcForecastWindSp_0001 1;
BA_ "GenSigSNA" SG_ 1969 UI_weatherSvcForecastWindSp_0001 "63";
BA_ "SystemSignalLongSymbol" SG_ 1969 UI_weatherSvcForecastWindSp_0001 "UI_weatherSvcForecastWindSpeedKph_hour10";
BA_ "Confidence" SG_ 1969 UI_weatherSvcForecastWindSp_0002 1;
BA_ "GenSigSNA" SG_ 1969 UI_weatherSvcForecastWindSp_0002 "63";
BA_ "SystemSignalLongSymbol" SG_ 1969 UI_weatherSvcForecastWindSp_0002 "UI_weatherSvcForecastWindSpeedKph_hour11";
BA_ "Confidence" SG_ 1533 UMC_alertID 1;
BA_ "Confidence" SG_ 1533 UMC_alertType 1;
BA_ "Confidence" SG_ 1533 UMC_a001_groundImpedance 1;
BA_ "Confidence" SG_ 1533 UMC_a002_ccidRmsCurrent 1;
BA_ "Confidence" SG_ 1533 UMC_a002_ccidRmsCurrentAvg 1;
BA_ "Confidence" SG_ 1533 UMC_a002_ccidDCGfciCurrent 1;
BA_ "Confidence" SG_ 1533 UMC_a002_ccidFaultReason 1;
BA_ "GenSigSNA" SG_ 1533 UMC_a002_ccidFaultReason "0";
BA_ "Confidence" SG_ 1533 UMC_a003_faultType 1;
BA_ "Confidence" SG_ 1533 UMC_a003_ccidSelfTestDuty 1;
BA_ "Confidence" SG_ 1533 UMC_a003_ccidSelfTestCurrent 1;
BA_ "Confidence" SG_ 1533 UMC_a004_lineVoltage 1;
BA_ "Confidence" SG_ 1533 UMC_a004_inputVoltage 1;
BA_ "Confidence" SG_ 1533 UMC_a004_inputNeutralVoltage 1;
BA_ "Confidence" SG_ 1533 UMC_a005_lineVoltage 1;
BA_ "Confidence" SG_ 1533 UMC_a005_inputVoltage 1;
BA_ "Confidence" SG_ 1533 UMC_a005_inputNeutralVoltage 1;
BA_ "Confidence" SG_ 1533 UMC_a006_outputVoltage 1;
BA_ "Confidence" SG_ 1533 UMC_a006_faultType 1;
BA_ "Confidence" SG_ 1533 UMC_a006_umcReceptacleVoltage 1;
BA_ "Confidence" SG_ 1533 UMC_a006_handleVoltage 1;
BA_ "Confidence" SG_ 1533 UMC_a007_pcbaTemp 1;
BA_ "Confidence" SG_ 1533 UMC_a008_wallPlugTemp 1;
BA_ "Confidence" SG_ 1533 UMC_a008_SA_current 1;
BA_ "Confidence" SG_ 1533 UMC_a009_vehConnTemp 1;
BA_ "Confidence" SG_ 1533 UMC_a010_inputTerminalsTemp 1;
BA_ "Confidence" SG_ 1533 UMC_a012_pilotHigh 1;
BA_ "Confidence" SG_ 1533 UMC_a012_pilotLow 1;
BA_ "Confidence" SG_ 1533 UMC_a013_SA_current 1;
BA_ "Confidence" SG_ 1533 UMC_a015_SA_current 1;
BA_ "Confidence" SG_ 1533 UMC_a016_pcbaTemp 1;
BA_ "Confidence" SG_ 1533 UMC_a017_wallPlugTemp 1;
BA_ "Confidence" SG_ 1533 UMC_a017_SA_current 1;
BA_ "Confidence" SG_ 1533 UMC_a018_vehConnTemp 1;
BA_ "Confidence" SG_ 1533 UMC_a019_inputTerminalsTemp 1;
BA_ "Confidence" SG_ 1533 UMC_a024_groundImpedance 1;
BA_ "Confidence" SG_ 1533 UMC_a040_groundImpedance 1;
BA_ "Confidence" SG_ 1285 SA_infoIndex 1;
BA_ "Confidence" SG_ 1285 SA_genealogyVersion 0;
BA_ "Confidence" SG_ 1285 SA_genealogyCrc 0;
BA_ "Confidence" SG_ 1285 SA_region 0;
BA_ "Confidence" SG_ 1285 SA_OverTempThreshold 0;
BA_ "Confidence" SG_ 1285 SA_partNumInt 0;
BA_ "Confidence" SG_ 1285 SA_partNumRev 0;
BA_ "Confidence" SG_ 1285 SA_currentLimit 0;
BA_ "Confidence" SG_ 1285 SA_l1Voltage 0;
BA_ "Confidence" SG_ 1320 UnixTimeSeconds 0;
BA_ "Confidence" SG_ 1949 V2G_evseLogDataSelect 1;
BA_ "Confidence" SG_ 1949 V2G_chgParamRes_respCode 0;
BA_ "Confidence" SG_ 1949 V2G_chgParamRes_finished 0;
BA_ "Confidence" SG_ 1949 V2G_chgParamRes_evseStatus 0;
BA_ "Confidence" SG_ 1949 V2G_chgParamRes_evseMaxILim 0;
BA_ "Confidence" SG_ 1949 V2G_chgParamRes_evseMaxVLim 0;
BA_ "Confidence" SG_ 1949 V2G_chgParamRes_evseMinILim 0;
BA_ "Confidence" SG_ 1949 V2G_chgParamRes_evseMinVLim 0;
BA_ "Confidence" SG_ 1949 V2G_chgParamRes_evseMaxPowerLim 0;
BA_ "Confidence" SG_ 1949 V2G_chgParamRes_evseMaxPower_val 0;
BA_ "Confidence" SG_ 1949 V2G_chgParamRes_isoState 0;
BA_ "Confidence" SG_ 1949 V2G_chgParamRes_isoState_val 0;
BA_ "Confidence" SG_ 1338 VCBATT0_alertID 1;
BA_ "Confidence" SG_ 1338 VCBATT0_alertState 1;
BA_ "Confidence" SG_ 1338 VCBATT0_a059_voltageDrop 1;
BA_ "Confidence" SG_ 1338 VCBATT0_a059_resistanceEstimate 1;
BA_ "Confidence" SG_ 1338 VCBATT0_a059_current 1;
BA_ "Confidence" SG_ 1338 VCBATT0_a063_ADCVoltage 1;
BA_ "Confidence" SG_ 973 VCBATT0_matrixIndex 1;
BA_ "SystemSignalLongSymbol" SG_ 973 VCBATT0_a033_eccNonCorrectableEr "VCBATT0_a033_eccNonCorrectableError";
BA_ "Confidence" SG_ 1858 VCBATT1_lvbmsStatusHighIndex 1;
BA_ "Confidence" SG_ 1858 VCBATT1_LVBMS_packCurrent 0;
BA_ "GenSigSNA" SG_ 1858 VCBATT1_LVBMS_packCurrent "4194303";
BA_ "Confidence" SG_ 1858 VCBATT1_LVBMS_packVoltage 0;
BA_ "GenSigSNA" SG_ 1858 VCBATT1_LVBMS_packVoltage "65535";
BA_ "Confidence" SG_ 1858 VCBATT1_LVBMS_packTemperature 0;
BA_ "GenSigSNA" SG_ 1858 VCBATT1_LVBMS_packTemperature "511";
BA_ "Confidence" SG_ 1858 VCBATT1_LVBMS_MOSTemperature 0;
BA_ "GenSigSNA" SG_ 1858 VCBATT1_LVBMS_MOSTemperature "4095";
BA_ "Confidence" SG_ 1858 VCBATT1_LVBMS_sumCellVoltage 0;
BA_ "GenSigSNA" SG_ 1858 VCBATT1_LVBMS_sumCellVoltage "65535";
BA_ "Confidence" SG_ 1858 VCBATT1_LVBMS_maxBrickVoltage 0;
BA_ "GenSigSNA" SG_ 1858 VCBATT1_LVBMS_maxBrickVoltage "8191";
BA_ "Confidence" SG_ 1858 VCBATT1_LVBMS_maxBrickVoltageInd 0;
BA_ "GenSigSNA" SG_ 1858 VCBATT1_LVBMS_maxBrickVoltageInd "255";
BA_ "SystemSignalLongSymbol" SG_ 1858 VCBATT1_LVBMS_maxBrickVoltageInd "VCBATT1_LVBMS_maxBrickVoltageIndex";
BA_ "Confidence" SG_ 1858 VCBATT1_totalLVLoadCurrent 0;
BA_ "Confidence" SG_ 1858 VCBATT1_LVPackChargeCurrentLimit 0;
BA_ "Confidence" SG_ 1858 VCBATT1_LVPackCurrent 0;
BA_ "Confidence" SG_ 1858 VCBATT1_LVBMS_estimatedPackOcv 0;
BA_ "Confidence" SG_ 1858 VCBATT1_LVBMS_voltageTarget 0;
BA_ "GenSigSNA" SG_ 1858 VCBATT1_LVBMS_voltageTarget "65535";
BA_ "Confidence" SG_ 1858 VCBATT1_LVBMS_currentTarget 0;
BA_ "GenSigSNA" SG_ 1858 VCBATT1_LVBMS_currentTarget "262143";
BA_ "Confidence" SG_ 1858 VCBATT1_LVBMS_maxAllowedChargeCu 0;
BA_ "GenSigSNA" SG_ 1858 VCBATT1_LVBMS_maxAllowedChargeCu "8191";
BA_ "SystemSignalLongSymbol" SG_ 1858 VCBATT1_LVBMS_maxAllowedChargeCu "VCBATT1_LVBMS_maxAllowedChargeCurrent";
BA_ "Confidence" SG_ 1858 VCBATT1_LVBMS_maxAllowedDischarg 0;
BA_ "GenSigSNA" SG_ 1858 VCBATT1_LVBMS_maxAllowedDischarg "8191";
BA_ "SystemSignalLongSymbol" SG_ 1858 VCBATT1_LVBMS_maxAllowedDischarg "VCBATT1_LVBMS_maxAllowedDischargeCurrent";
BA_ "Confidence" SG_ 1858 VCBATT1_LVBMS_MOSCommand 0;
BA_ "Confidence" SG_ 1858 VCBATT1_LVBMS_ClearErrorCntrComm 0;
BA_ "SystemSignalLongSymbol" SG_ 1858 VCBATT1_LVBMS_ClearErrorCntrComm "VCBATT1_LVBMS_ClearErrorCntrCommand";
BA_ "Confidence" SG_ 1858 VCBATT1_LVBMS_ClearHistoricFault 0;
BA_ "SystemSignalLongSymbol" SG_ 1858 VCBATT1_LVBMS_ClearHistoricFault "VCBATT1_LVBMS_ClearHistoricFaultCommand";
BA_ "Confidence" SG_ 1858 VCBATT1_LVBMS_ResetLVBMSCommand 0;
BA_ "Confidence" SG_ 1858 VCBATT1_LVBMS_EnterHibernationCo 0;
BA_ "SystemSignalLongSymbol" SG_ 1858 VCBATT1_LVBMS_EnterHibernationCo "VCBATT1_LVBMS_EnterHibernationCommand";
BA_ "Confidence" SG_ 1858 VCBATT1_LVBMS_ECPAState 0;
BA_ "GenSigSNA" SG_ 1858 VCBATT1_LVBMS_ECPAState "3";
BA_ "Confidence" SG_ 1858 VCBATT1_LVBMS_MOSState 0;
BA_ "GenSigSNA" SG_ 1858 VCBATT1_LVBMS_MOSState "3";
BA_ "Confidence" SG_ 1858 VCBATT1_LVBMS_VehicleState 0;
BA_ "Confidence" SG_ 1858 VCBATT1_LVBMS_LINWakeDisabled 0;
BA_ "Confidence" SG_ 1858 VCBATT1_LVBMS_chargeType 0;
BA_ "GenSigSNA" SG_ 1858 VCBATT1_LVBMS_chargeType "4";
BA_ "Confidence" SG_ 1858 VCBATT1_LVBMS_cellAndArcProtEnab 0;
BA_ "SystemSignalLongSymbol" SG_ 1858 VCBATT1_LVBMS_cellAndArcProtEnab "VCBATT1_LVBMS_cellAndArcProtEnabled";
BA_ "Confidence" SG_ 1858 VCBATT1_LVBMS_avgBrickVoltage 0;
BA_ "GenSigSNA" SG_ 1858 VCBATT1_LVBMS_avgBrickVoltage "8191";
BA_ "Confidence" SG_ 1858 VCBATT1_LVBMS_minBrickVoltage 0;
BA_ "GenSigSNA" SG_ 1858 VCBATT1_LVBMS_minBrickVoltage "8191";
BA_ "Confidence" SG_ 1858 VCBATT1_LVBMS_minBrickVoltageInd 0;
BA_ "GenSigSNA" SG_ 1858 VCBATT1_LVBMS_minBrickVoltageInd "255";
BA_ "SystemSignalLongSymbol" SG_ 1858 VCBATT1_LVBMS_minBrickVoltageInd "VCBATT1_LVBMS_minBrickVoltageIndex";
BA_ "Confidence" SG_ 1119 VCBATT1_LVSelfTestsChecksum 0;
BA_ "Confidence" SG_ 1119 VCBATT1_LVSelfTestsCounter 0;
BA_ "Confidence" SG_ 1119 VCBATT1_LVSelfTestsIndex 1;
BA_ "Confidence" SG_ 1119 VCBATT1_lvProtectionSelfTestsEna 0;
BA_ "SystemSignalLongSymbol" SG_ 1119 VCBATT1_lvProtectionSelfTestsEna "VCBATT1_lvProtectionSelfTestsEnabled";
BA_ "Confidence" SG_ 1119 VCBATT1_startBattDomainOvercurre 0;
BA_ "SystemSignalLongSymbol" SG_ 1119 VCBATT1_startBattDomainOvercurre "VCBATT1_startBattDomainOvercurrentSelfTest";
BA_ "Confidence" SG_ 1119 VCBATT1_startBattDomainOvervolta 0;
BA_ "SystemSignalLongSymbol" SG_ 1119 VCBATT1_startBattDomainOvervolta "VCBATT1_startBattDomainOvervoltageSelfTest";
BA_ "Confidence" SG_ 1119 VCBATT1_startBattDomainUndervolt 0;
BA_ "SystemSignalLongSymbol" SG_ 1119 VCBATT1_startBattDomainUndervolt "VCBATT1_startBattDomainUndervoltageSelfTest";
BA_ "Confidence" SG_ 1119 VCBATT1_startDualPowerLoadsSelfT 0;
BA_ "SystemSignalLongSymbol" SG_ 1119 VCBATT1_startDualPowerLoadsSelfT "VCBATT1_startDualPowerLoadsSelfTest";
BA_ "Confidence" SG_ 1119 VCBATT1_startVCBattBridgeEFuseAS 0;
BA_ "SystemSignalLongSymbol" SG_ 1119 VCBATT1_startVCBattBridgeEFuseAS "VCBATT1_startVCBattBridgeEFuseASICSelfTest";
BA_ "Confidence" SG_ 1119 VCBATT1_startPCSOVShutdownSelfTe 0;
BA_ "SystemSignalLongSymbol" SG_ 1119 VCBATT1_startPCSOVShutdownSelfTe "VCBATT1_startPCSOVShutdownSelfTest";
BA_ "Confidence" SG_ 1119 VCBATT1_startPCSDomainOvervoltag 0;
BA_ "SystemSignalLongSymbol" SG_ 1119 VCBATT1_startPCSDomainOvervoltag "VCBATT1_startPCSDomainOvervoltageSelfTest";
BA_ "Confidence" SG_ 1119 VCBATT1_startBattDomainUnde_0001 0;
BA_ "SystemSignalLongSymbol" SG_ 1119 VCBATT1_startBattDomainUnde_0001 "VCBATT1_startBattDomainUndervoltageVCLeftSelfTest";
BA_ "Confidence" SG_ 1119 VCBATT1_startPCSDomainUndervolta 0;
BA_ "SystemSignalLongSymbol" SG_ 1119 VCBATT1_startPCSDomainUndervolta "VCBATT1_startPCSDomainUndervoltageSelfTest";
BA_ "Confidence" SG_ 1119 VCBATT1_startVCFrontBridgeEFuseA 0;
BA_ "SystemSignalLongSymbol" SG_ 1119 VCBATT1_startVCFrontBridgeEFuseA "VCBATT1_startVCFrontBridgeEFuseASICSelfTest";
BA_ "Confidence" SG_ 1119 VCBATT1_battDomainOvercurrentSel 0;
BA_ "SystemSignalLongSymbol" SG_ 1119 VCBATT1_battDomainOvercurrentSel "VCBATT1_battDomainOvercurrentSelfTestResult";
BA_ "Confidence" SG_ 1119 VCBATT1_battDomainOvercurre_0001 0;
BA_ "GenSigSNA" SG_ 1119 VCBATT1_battDomainOvercurre_0001 "4";
BA_ "SystemSignalLongSymbol" SG_ 1119 VCBATT1_battDomainOvercurre_0001 "VCBATT1_battDomainOvercurrentSelfTestState";
BA_ "Confidence" SG_ 1119 VCBATT1_battDomainOvervoltageSel 0;
BA_ "SystemSignalLongSymbol" SG_ 1119 VCBATT1_battDomainOvervoltageSel "VCBATT1_battDomainOvervoltageSelfTestResult";
BA_ "Confidence" SG_ 1119 VCBATT1_battDomainOvervolta_0001 0;
BA_ "GenSigSNA" SG_ 1119 VCBATT1_battDomainOvervolta_0001 "4";
BA_ "SystemSignalLongSymbol" SG_ 1119 VCBATT1_battDomainOvervolta_0001 "VCBATT1_battDomainOvervoltageSelfTestState";
BA_ "Confidence" SG_ 1119 VCBATT1_battDomainUndervoltageSe 0;
BA_ "SystemSignalLongSymbol" SG_ 1119 VCBATT1_battDomainUndervoltageSe "VCBATT1_battDomainUndervoltageSelfTestResult";
BA_ "Confidence" SG_ 1119 VCBATT1_battDomainUndervolt_0001 0;
BA_ "GenSigSNA" SG_ 1119 VCBATT1_battDomainUndervolt_0001 "4";
BA_ "SystemSignalLongSymbol" SG_ 1119 VCBATT1_battDomainUndervolt_0001 "VCBATT1_battDomainUndervoltageSelfTestState";
BA_ "Confidence" SG_ 1119 VCBATT1_dualPowerLoadsSelfTestRe 0;
BA_ "SystemSignalLongSymbol" SG_ 1119 VCBATT1_dualPowerLoadsSelfTestRe "VCBATT1_dualPowerLoadsSelfTestResult";
BA_ "Confidence" SG_ 1119 VCBATT1_dualPowerLoadsSelfTestSt 0;
BA_ "GenSigSNA" SG_ 1119 VCBATT1_dualPowerLoadsSelfTestSt "4";
BA_ "SystemSignalLongSymbol" SG_ 1119 VCBATT1_dualPowerLoadsSelfTestSt "VCBATT1_dualPowerLoadsSelfTestState";
BA_ "Confidence" SG_ 1119 VCBATT1_vcbattBridgeEFuseASICSel 0;
BA_ "SystemSignalLongSymbol" SG_ 1119 VCBATT1_vcbattBridgeEFuseASICSel "VCBATT1_vcbattBridgeEFuseASICSelfTestResult";
BA_ "Confidence" SG_ 1119 VCBATT1_vcbattBridgeEFuseAS_0001 0;
BA_ "GenSigSNA" SG_ 1119 VCBATT1_vcbattBridgeEFuseAS_0001 "4";
BA_ "SystemSignalLongSymbol" SG_ 1119 VCBATT1_vcbattBridgeEFuseAS_0001 "VCBATT1_vcbattBridgeEFuseASICSelfTestState";
BA_ "Confidence" SG_ 1119 VCBATT1_uvProtectionState 0;
BA_ "Confidence" SG_ 1119 VCBATT1_undervoltageSelfTestFaul 0;
BA_ "SystemSignalLongSymbol" SG_ 1119 VCBATT1_undervoltageSelfTestFaul "VCBATT1_undervoltageSelfTestFaultInjectionReady";
BA_ "Confidence" SG_ 1119 VC_selfTestsRunningMode 0;
VAL_ 820 UI_systemPowerLimit 31 "SNA" ;
VAL_ 820 UI_pedalMap 2 "PERFORMANCE" 1 "SPORT" 0 "CHILL" ;
VAL_ 820 UI_systemTorqueLimit 63 "SNA" ;
VAL_ 820 UI_closureConfirmed 3 "TRUNK" 2 "PROX" 1 "FRUNK" 0 "NONE" ;
VAL_ 820 UI_limitMode 3 "LIMIT_SERVICE" 2 "LIMIT_FACTORY" 1 "LIMIT_VALET" 0 "LIMIT_NORMAL" ;
VAL_ 820 UI_motorOnMode 2 "MOTORONMODE_REAR_ONLY" 1 "MOTORONMODE_FRONT_ONLY" 0 "MOTORONMODE_NORMAL" ;
VAL_ 820 UI_stoppingMode 2 "HOLD" 1 "CREEP" 0 "STANDARD" ;
VAL_ 820 UI_speedLimit 511 "SNA" ;
VAL_ 820 UI_enableSmartShift 2 "ENABLED_P_R_D" 1 "ENABLED_P" 0 "OFF" ;
VAL_ 820 UI_navVehParallelToRdCanContinue 2 "TRUE" 1 "FALSE" 0 "SNA" ;
VAL_ 666 UI_seatControlIndex 3 "3" 2 "2" 1 "1" 0 "0" ;
VAL_ 666 UI_3RSeatChildLock 3 "UI_ADJUSTABLE_FOLD_FLAT_CHILD_LOCK_BOTH" 2 "UI_ADJUSTABLE_FOLD_FLAT_CHILD_LOCK_RIGHT" 1 "UI_ADJUSTABLE_FOLD_FLAT_CHILD_LOCK_LEFT" 0 "UI_ADJUSTABLE_FOLD_FLAT_CHILD_LOCK_NONE" ;
VAL_ 666 UI_left3RowSeatAdjustmentRequest 6 "UI_ADJUSTABLE_FOLD_FLAT_REQUEST_STOP" 5 "UI_ADJUSTABLE_FOLD_FLAT_REQUEST_TOGGLE_FOLD" 4 "UI_ADJUSTABLE_FOLD_FLAT_REQUEST_REARWARD_FAST" 3 "UI_ADJUSTABLE_FOLD_FLAT_REQUEST_REARWARD_COMFORT" 2 "UI_ADJUSTABLE_FOLD_FLAT_REQUEST_FORWARD_FAST" 1 "UI_ADJUSTABLE_FOLD_FLAT_REQUEST_FORWARD_COMFORT" 0 "UI_ADJUSTABLE_FOLD_FLAT_REQUEST_NONE" ;
VAL_ 666 UI_right3RowSeatAdjustmentReques 6 "UI_ADJUSTABLE_FOLD_FLAT_REQUEST_STOP" 5 "UI_ADJUSTABLE_FOLD_FLAT_REQUEST_TOGGLE_FOLD" 4 "UI_ADJUSTABLE_FOLD_FLAT_REQUEST_REARWARD_FAST" 3 "UI_ADJUSTABLE_FOLD_FLAT_REQUEST_REARWARD_COMFORT" 2 "UI_ADJUSTABLE_FOLD_FLAT_REQUEST_FORWARD_FAST" 1 "UI_ADJUSTABLE_FOLD_FLAT_REQUEST_FORWARD_COMFORT" 0 "UI_ADJUSTABLE_FOLD_FLAT_REQUEST_NONE" ;
VAL_ 666 UI_2RLeftSeatFanReq 3 "FAN_REQUEST_LEVEL3" 2 "FAN_REQUEST_LEVEL2" 1 "FAN_REQUEST_LEVEL1" 0 "FAN_REQUEST_OFF" ;
VAL_ 666 UI_2RRightSeatFanReq 3 "FAN_REQUEST_LEVEL3" 2 "FAN_REQUEST_LEVEL2" 1 "FAN_REQUEST_LEVEL1" 0 "FAN_REQUEST_OFF" ;
VAL_ 723 UI_solarAzimuthAngle -32768 "SNA" ;
VAL_ 723 UI_solarAzimuthAngleCarRef 255 "SNA" ;
VAL_ 723 UI_isSunUp 3 "SUN_SNA" 1 "SUN_UP" 0 "SUN_DOWN" ;
VAL_ 723 UI_solarElevationAngle 127 "SNA" ;
VAL_ 851 UI_autopilotTrial 3 "ACTIVE" 2 "STOP" 1 "START" 0 "NONE" ;
VAL_ 851 UI_factoryReset 3 "CUSTOMER" 2 "DIAGNOSTIC" 1 "DEVELOPER" 0 "NONE_SNA" ;
VAL_ 851 UI_cellNetworkTechnology 15 "CELL_NETWORK_SNA" 14 "CELL_NETWORK_NGRAN" 13 "CELL_NETWORK_5GSA" 12 "CELL_NETWORK_5GNSA" 11 "CELL_NETWORK_LTE5GCN" 10 "CELL_NETWORK_WCDMA" 9 "CELL_NETWORK_CDMA" 8 "CELL_NETWORK_GSM" 7 "CELL_NETWORK_LTE" 6 "CELL_NETWORK_HSPA" 5 "CELL_NETWORK_HSUPA" 4 "CELL_NETWORK_HSDPA" 3 "CELL_NETWORK_UMTS" 2 "CELL_NETWORK_EDGE" 1 "CELL_NETWORK_GPRS" 0 "CELL_NETWORK_NONE" ;
VAL_ 851 UI_cellSignalBars 7 "SNA" 5 "FIVE" 4 "FOUR" 3 "THREE" 2 "TWO" 1 "ONE" 0 "ZERO" ;
VAL_ 851 UI_trailerModeTelltale 3 "TRAILER_MODE_TELLTALE_RED" 2 "TRAILER_MODE_TELLTALE_YELLOW" 1 "TRAILER_MODE_TELLTALE_BLUE" 0 "TRAILER_MODE_TELLTALE_OFF" ;
VAL_ 991 UI_userActivity 1 "USER_ACTIVE" 0 "USER_IDLE" ;
VAL_ 991 UI_linkState 2 "LINK_STATE_WIFI" 1 "LINK_STATE_CELL" 0 "LINK_STATE_NONE" ;
VAL_ 991 UI_sentryModeState 6 "SNA" 5 "QUIET" 4 "PANIC" 3 "AWARE" 2 "ARMED" 1 "IDLE" 0 "OFF" ;
VAL_ 991 UI_mobileAppConnected 1 "CONNECTED" 0 "NOT_CONNECTED" ;
VAL_ 991 UI_autoshiftDRState 6 "AUTOSHIFT_DR_STATE_BRAKE_GEAR_SHIFT_CONFIRMED_D" 5 "AUTOSHIFT_DR_STATE_BRAKE_GEAR_SHIFT_CONFIRMED_R" 4 "AUTOSHIFT_DR_STATE_BRAKE_STEERING_AND_BRAKE_CONFIRMED" 3 "AUTOSHIFT_DR_STATE_ONLY_STEERING_CONFIRMED" 2 "AUTOSHIFT_DR_STATE_ONLY_BRAKE_CONFIRMED" 1 "AUTOSHIFT_DR_STATE_PROMPT_SHOWING_UNCONFIRMED" 0 "AUTOSHIFT_DR_STATE_INACTIVE" ;
VAL_ 991 UI_wifiBtModuleType 4 "ELEKTRA" 3 "TCU4G" 2 "BCM4359" 1 "QCA6595" 0 "UNKNOWN" ;
VAL_ 991 UI_sohHealthStatus 3 "OK" 2 "REDUCED" 1 "NO_INTERNET" 0 "UNKNOWN" ;
VAL_ 991 UI_selfParkState 255 "SNA" 52 "SELF_PARK_USER_PAUSED" 51 "SELF_PARK_REMOTE_PRE_ABORT" 50 "SELF_PARK_RESUME" 49 "SELF_PARK_PAUSE" 48 "SELF_PARK_DV_MISMATCH" 47 "SELF_PARK_DI_PANIC" 46 "SELF_PARK_POST_ACTIVE_FAILURE" 45 "SELF_PARK_POST_ACTIVE_SUCCESS" 44 "SELF_PARK_CANCEL_AUTO_SUMMON" 43 "SELF_PARK_REMOTE_ABORT" 42 "SELF_PARK_OBSTACLE_NOT_CLEARED" 41 "SELF_PARK_OBSTACLE_CLEARED" 40 "SELF_PARK_OPEN_GATE" 39 "SELF_PARK_ACTIVE" 38 "SELF_PARK_STARTED_REVERSE" 37 "SELF_PARK_STARTED_FORWARD" 36 "SELF_PARK_NOT_STARTED_TIMEOUT" 35 "SELF_PARK_PRIMED" 34 "SELF_PARK_PREPRIMED" 33 "SELF_PARK_TURN_ON_DRIVE_RAIL" 32 "SELF_PARK_DETECT_KEY_FOB" 31 "SELF_PARK_WAKE_UP_BUSES" 30 "SELF_PARK_CONNECTING_BLUETOOTH" 29 "SELF_PARK_UNAVAILABLE_CAR_WASH_MODE" 28 "SELF_PARK_UNAVAILABLE_CAR_ALARM" 27 "SELF_PARK_UNAVAILABLE_CRASH_STATE" 26 "SELF_PARK_UNAVAILABLE_DRAG_STRIP_MODE" 25 "SELF_PARK_UNAVAILABLE_TRACK_MODE" 24 "SELF_PARK_UNAVAILABLE_SERVICE_MODE" 23 "SELF_PARK_UNAVAILABLE_DOG_MODE" 22 "SELF_PARK_UNAVAILABLE_GAME_MODE" 21 "SELF_PARK_UNAVAILABLE_BLUETOOTH_CONNECT_TIMEOUT" 20 "SELF_PARK_UNAVAILABLE_WAKEUP_TIMEOUT" 19 "SELF_PARK_UNAVAILABLE_NO_BLUETOOTH_DEVICES_PAIRED" 18 "SELF_PARK_UNAVAILABLE_BRAKE_PRESSED" 17 "SELF_PARK_UNAVAILABLE_ROAD_GRADE" 16 "SELF_PARK_UNAVAILABLE_TRAILER_MODE" 15 "SELF_PARK_UNAVAILABLE_KEY_FOB_BATTERY_LOW" 14 "SELF_PARK_UNAVAILABLE_KEY_FOB_NOT_DETECTED" 13 "SELF_PARK_UNAVAILABLE_PARK_SENSOR_ISSUE" 12 "SELF_PARK_UNAVAILABLE_AUTOSTEER_NOT_ENABLED" 11 "SELF_PARK_UNAVAILABLE_LV_BUS_SUPPORT_ISSUE" 10 "SELF_PARK_UNAVAILABLE_ON_PUBLIC_ROAD" 9 "SELF_PARK_UNAVAILABLE_PARKED_TOO_LONG" 8 "SELF_PARK_UNAVAILABLE_DOOR_OPEN" 7 "SELF_PARK_UNAVAILABLE_TRUNK_OPEN" 6 "SELF_PARK_UNAVAILABLE_FRUNK_OPEN" 5 "SELF_PARK_UNAVAILABLE_PLUGGED_IN" 4 "SELF_PARK_UNAVAILABLE_NOT_PARKED" 3 "SELF_PARK_UNAVAILABLE" 2 "SELF_PARK_IDLE" 1 "SELF_PARK_DRIVING" 0 "SELF_PARK_DISABLED" ;
VAL_ 991 UI_summonDeviceIndex 3 "UNKNOWN" 2 "DEVICE_2" 1 "DEVICE_1" 0 "DEVICE_0" ;
VAL_ 663 UI_adaptiveRideRequest 3 "ADAPTIVE_RIDE_REQUEST_ADVANCED" 2 "ADAPTIVE_RIDE_REQUEST_SPORT" 1 "ADAPTIVE_RIDE_REQUEST_AUTO" 0 "ADAPTIVE_RIDE_REQUEST_COMFORT" ;
VAL_ 663 UI_suspensionLoweringRequest 3 "SNA" 2 "AUTO" 1 "ALWAYS" 0 "NEVER" ;
VAL_ 663 UI_geofenceLevelingRequest 5 "GEOFENCE_LEVELING_REQUEST_SNA" 4 "GEOFENCE_LEVELING_REQUEST_VERY_HIGH_PERSIST" 3 "GEOFENCE_LEVELING_REQUEST_HIGH_PERSIST" 2 "GEOFENCE_LEVELING_REQUEST_VERY_HIGH_TEMPORARY" 1 "GEOFENCE_LEVELING_REQUEST_HIGH_TEMPORARY" 0 "GEOFENCE_LEVELING_REQUEST_NONE" ;
VAL_ 663 UI_jackModeToggleRequest 1 "ACTIVE" 0 "NONE" ;
VAL_ 663 UI_roadRoughnessLookahead 127 "SNA" ;
VAL_ 663 UI_roadRoughnessStart 31 "SNA" ;
VAL_ 663 UI_mapVersionUsed 255 "SNA" ;
VAL_ 663 UI_suspensionLevelRequest 7 "VERY_HIGH_LEVEL_PERSIST" 6 "HIGH_LEVEL_PERSIST" 5 "VERY_HIGH_LEVEL_TEMPORARY" 4 "HIGH_LEVEL_TEMPORARY" 3 "STANDARD_LEVEL" 2 "LOW_LEVEL" 1 "VERY_LOW_LEVEL" 0 "NONE" ;
VAL_ 787 UI_trackModeRequest 2 "TRACK_MODE_REQUEST_OFF" 1 "TRACK_MODE_REQUEST_ON" 0 "TRACK_MODE_REQUEST_IDLE" ;
VAL_ 787 UI_trackPostCooling 1 "ON" 0 "OFF" ;
VAL_ 787 UI_trackCmpOverclock 1 "ON" 0 "OFF" ;
VAL_ 787 UI_trackModeBrakeTemps 1 "ON" 0 "OFF" ;
VAL_ 787 UI_trackDrivePowerAvailability 2 "TRACK_MODE_POWER_MAX" 1 "TRACK_MODE_POWER_MIDDLE" 0 "TRACK_MODE_POWER_ENDURANCE" ;
VAL_ 787 UI_stabilityModeRequest 1 "REDUCED_REQUEST" 0 "NORMAL_REQUEST" ;
VAL_ 839 UI_navFastchargerType 4 "V4" 3 "V3" 2 "V2" 1 "LOW_POWER" 0 "NONE" ;
VAL_ 839 UI_battPreconditionOnNavState 3 "ACTIVE_COOL" 2 "PASSIVE_COOL" 1 "ACTIVE_HEAT" 0 "PASSIVE_HEAT" ;
VAL_ 839 UI_battPreconditionOnNavPowerReq 127 "SNA" 126 "MAX" -126 "MIN" ;
VAL_ 839 UI_battPreconditionOnNavTargetT 255 "SNA" 254 "MAX" 0 "MIN" ;
VAL_ 839 UI_ambientTempAtDestination -128 "SNA" ;
VAL_ 839 UI_tripPlanChargingTargetPercent 1023 "SNA" ;
VAL_ 839 UI_energyAtDestination -32767 "TRIP_TOO_LONG" -32768 "SNA" ;
VAL_ 627 UI_powerStateRequest 3 "DRIVE_SUMMON" 2 "ACCESSORY_PLUS" 1 "ACCESSORY" 0 "IDLE" ;
VAL_ 627 UI_wiperMode 3 "WIPER_MODE_PARK" 2 "WIPER_MODE_NORMAL" 1 "WIPER_MODE_SERVICE" 0 "WIPER_MODE_SNA" ;
VAL_ 627 UI_steeringBacklightEnabled 1 "ENABLED" 0 "DISABLED" ;
VAL_ 627 UI_steeringButtonMode 7 "STEERING_BUTTON_MODE_SEATS" 6 "STEERING_BUTTON_MODE_WIPERS" 5 "STEERING_BUTTON_MODE_HEADLIGHT_RIGHT" 4 "STEERING_BUTTON_MODE_HEADLIGHT_LEFT" 3 "STEERING_BUTTON_MODE_MIRROR_RIGHT" 2 "STEERING_BUTTON_MODE_MIRROR_LEFT" 1 "STEERING_BUTTON_MODE_STEERING_COLUMN_ADJ" 0 "STEERING_BUTTON_MODE_OFF" ;
VAL_ 627 UI_lockRequest 7 "UI_LOCK_REQUEST_SNA" 4 "UI_LOCK_REQUEST_REMOTE_LOCK" 3 "UI_LOCK_REQUEST_REMOTE_UNLOCK" 2 "UI_LOCK_REQUEST_UNLOCK" 1 "UI_LOCK_REQUEST_LOCK" 0 "UI_LOCK_REQUEST_IDLE" ;
VAL_ 627 UI_mirrorFoldRequest 3 "MIRROR_FOLD_REQUEST_SNA" 2 "MIRROR_FOLD_REQUEST_PRESENT" 1 "MIRROR_FOLD_REQUEST_RETRACT" 0 "MIRROR_FOLD_REQUEST_IDLE" ;
VAL_ 627 UI_remoteStartRequest 4 "UI_REMOTE_START_REQUEST_SNA" 1 "UI_REMOTE_START_REQUEST_START" 0 "UI_REMOTE_START_REQUEST_IDLE" ;
VAL_ 627 UI_displayBrightnessLevel 255 "SNA" ;
VAL_ 627 UI_frontLeftSeatHeatReq 3 "HEATER_REQUEST_LEVEL3" 2 "HEATER_REQUEST_LEVEL2" 1 "HEATER_REQUEST_LEVEL1" 0 "HEATER_REQUEST_OFF" ;
VAL_ 627 UI_frontRightSeatHeatReq 3 "HEATER_REQUEST_LEVEL3" 2 "HEATER_REQUEST_LEVEL2" 1 "HEATER_REQUEST_LEVEL1" 0 "HEATER_REQUEST_OFF" ;
VAL_ 627 UI_rearLeftSeatHeatReq 3 "HEATER_REQUEST_LEVEL3" 2 "HEATER_REQUEST_LEVEL2" 1 "HEATER_REQUEST_LEVEL1" 0 "HEATER_REQUEST_OFF" ;
VAL_ 627 UI_rearCenterSeatHeatReq 3 "HEATER_REQUEST_LEVEL3" 2 "HEATER_REQUEST_LEVEL2" 1 "HEATER_REQUEST_LEVEL1" 0 "HEATER_REQUEST_OFF" ;
VAL_ 627 UI_rearRightSeatHeatReq 3 "HEATER_REQUEST_LEVEL3" 2 "HEATER_REQUEST_LEVEL2" 1 "HEATER_REQUEST_LEVEL1" 0 "HEATER_REQUEST_OFF" ;
VAL_ 627 UI_remoteClosureRequest 3 "UI_REMOTE_CLOSURE_REQUEST_SNA" 2 "UI_REMOTE_CLOSURE_REQUEST_FRONT_TRUNK_MOVE" 1 "UI_REMOTE_CLOSURE_REQUEST_REAR_TRUNK_MOVE" 0 "UI_REMOTE_CLOSURE_REQUEST_IDLE" ;
VAL_ 627 UI_wiperRequest 6 "WIPER_REQUEST_FAST_CONTINUOUS" 5 "WIPER_REQUEST_SLOW_CONTINUOUS" 4 "WIPER_REQUEST_FAST_INTERMITTENT" 3 "WIPER_REQUEST_SLOW_INTERMITTENT" 2 "WIPER_REQUEST_AUTO" 1 "WIPER_REQUEST_OFF" 0 "WIPER_REQUEST_SNA" ;
VAL_ 627 UI_domeLightSwitch 2 "DOME_LIGHT_SWITCH_AUTO" 1 "DOME_LIGHT_SWITCH_ON" 0 "DOME_LIGHT_SWITCH_OFF" ;
VAL_ 627 UI_driveStateRequest 1 "START" 0 "IDLE" ;
VAL_ 947 UI_lightSwitch 4 "LIGHT_SWITCH_SNA" 3 "LIGHT_SWITCH_OFF" 2 "LIGHT_SWITCH_PARKING" 1 "LIGHT_SWITCH_ON" 0 "LIGHT_SWITCH_AUTO" ;
VAL_ 947 UI_summonState 3 "ACTIVE" 2 "PRE_PRIMED" 1 "IDLE" 0 "SNA" ;
VAL_ 947 UI_autopilotPowerStateRequest 2 "AUTOPILOT_SUSPEND" 1 "AUTOPILOT_SENTRY" 0 "AUTOPILOT_NOMINAL" ;
VAL_ 947 UI_shorted12VCellTestMode 2 "ACTIVE" 1 "SHADOW" 0 "DISABLED" ;
VAL_ 947 UI_frontLeftSeatFanReq 3 "FAN_REQUEST_LEVEL3" 2 "FAN_REQUEST_LEVEL2" 1 "FAN_REQUEST_LEVEL1" 0 "FAN_REQUEST_OFF" ;
VAL_ 947 UI_frontRightSeatFanReq 3 "FAN_REQUEST_LEVEL3" 2 "FAN_REQUEST_LEVEL2" 1 "FAN_REQUEST_LEVEL1" 0 "FAN_REQUEST_OFF" ;
VAL_ 947 UI_3RLeftSeatHeatReq 3 "HEATER_REQUEST_LEVEL3" 2 "HEATER_REQUEST_LEVEL2" 1 "HEATER_REQUEST_LEVEL1" 0 "HEATER_REQUEST_OFF" ;
VAL_ 947 UI_3RRightSeatHeatReq 3 "HEATER_REQUEST_LEVEL3" 2 "HEATER_REQUEST_LEVEL2" 1 "HEATER_REQUEST_LEVEL1" 0 "HEATER_REQUEST_OFF" ;
VAL_ 947 UI_dcr12VThreshold 12 "15_MILLIOHMS" 11 "16_MILLIOHMS" 10 "17_MILLIOHMS" 9 "18_MILLIOHMS" 8 "19_MILLIOHMS" 7 "20_MILLIOHMS" 6 "22_MILLIOHMS" 5 "24_MILLIOHMS" 4 "27_MILLIOHMS" 3 "30_MILLIOHMS" 2 "35_MILLIOHMS" 1 "40_MILLIOHMS" 0 "OFF" ;
VAL_ 947 UI_tireSeason 1 "WINTER" 0 "NON_WINTER" ;
VAL_ 947 UI_saveTireConfigReq 1 "TRUE" 0 "FALSE" ;
VAL_ 660 UI_lightFlashRequest 3 "LIGHT_FLASH_SENTRY" 2 "LIGHT_FLASH_MOBILE_APP" 1 "LIGHT_FLASH_HOMELINK" 0 "LIGHT_FLASH_INACTIVE" ;
VAL_ 660 UI_drivingSideVEH 2 "UNKNOWN" 1 "RIGHT" 0 "LEFT" ;
VAL_ 660 UI_keyPairResponse 2 "DENIED" 1 "CONFIRMED" 0 "NONE" ;
VAL_ 660 UI_steeringWheelHeatLevelReq 3 "STEERING_WHEEL_HEAT_LEVEL3" 2 "STEERING_WHEEL_HEAT_LEVEL2" 1 "STEERING_WHEEL_HEAT_LEVEL1" 0 "STEERING_WHEEL_HEAT_OFF" ;
VAL_ 660 UI_packTempLoggingRequest 1 "TRUE" 0 "FALSE" ;
VAL_ 660 UI_leftRearSeatAdjustmentRequest 6 "UI_ADJUSTABLE_FOLD_FLAT_REQUEST_STOP" 5 "UI_ADJUSTABLE_FOLD_FLAT_REQUEST_TOGGLE_FOLD" 4 "UI_ADJUSTABLE_FOLD_FLAT_REQUEST_REARWARD_FAST" 3 "UI_ADJUSTABLE_FOLD_FLAT_REQUEST_REARWARD_COMFORT" 2 "UI_ADJUSTABLE_FOLD_FLAT_REQUEST_FORWARD_FAST" 1 "UI_ADJUSTABLE_FOLD_FLAT_REQUEST_FORWARD_COMFORT" 0 "UI_ADJUSTABLE_FOLD_FLAT_REQUEST_NONE" ;
VAL_ 660 UI_rightRearSeatAdjustmentReques 6 "UI_ADJUSTABLE_FOLD_FLAT_REQUEST_STOP" 5 "UI_ADJUSTABLE_FOLD_FLAT_REQUEST_TOGGLE_FOLD" 4 "UI_ADJUSTABLE_FOLD_FLAT_REQUEST_REARWARD_FAST" 3 "UI_ADJUSTABLE_FOLD_FLAT_REQUEST_REARWARD_COMFORT" 2 "UI_ADJUSTABLE_FOLD_FLAT_REQUEST_FORWARD_FAST" 1 "UI_ADJUSTABLE_FOLD_FLAT_REQUEST_FORWARD_COMFORT" 0 "UI_ADJUSTABLE_FOLD_FLAT_REQUEST_NONE" ;
VAL_ 660 UI_etcBluetoothControl 3 "RESERVED" 2 "ON" 1 "OFF" 0 "INACTIVE" ;
VAL_ 660 UI_rearSeatChildLock 3 "UI_ADJUSTABLE_FOLD_FLAT_CHILD_LOCK_BOTH" 2 "UI_ADJUSTABLE_FOLD_FLAT_CHILD_LOCK_RIGHT" 1 "UI_ADJUSTABLE_FOLD_FLAT_CHILD_LOCK_LEFT" 0 "UI_ADJUSTABLE_FOLD_FLAT_CHILD_LOCK_NONE" ;
VAL_ 660 UI_windowRequest 6 "WINDOW_REQUEST_GOTO_RELATIVE_PERCENT" 5 "WINDOW_REQUEST_GOTO_CLOSED_CARWASH" 4 "WINDOW_REQUEST_GOTO_OPEN" 3 "WINDOW_REQUEST_GOTO_CLOSED" 2 "WINDOW_REQUEST_GOTO_VENT" 1 "WINDOW_REQUEST_GOTO_PERCENT" 0 "WINDOW_REQUEST_IDLE" ;
VAL_ 1193 UI_firstRowLeftDomeLightRequest 1 "DOME_LIGHT_REQUEST_ACTIVE" 0 "DOME_LIGHT_REQUEST_NONE" ;
VAL_ 1193 UI_firstRowRightDomeLightRequest 1 "DOME_LIGHT_REQUEST_ACTIVE" 0 "DOME_LIGHT_REQUEST_NONE" ;
VAL_ 1193 UI_secondRowLeftDomeLightRequest 1 "DOME_LIGHT_REQUEST_ACTIVE" 0 "DOME_LIGHT_REQUEST_NONE" ;
VAL_ 1193 UI_secondRowCenterDomeLightReque 1 "DOME_LIGHT_REQUEST_ACTIVE" 0 "DOME_LIGHT_REQUEST_NONE" ;
VAL_ 1193 UI_secondRowRightDomeLightReques 1 "DOME_LIGHT_REQUEST_ACTIVE" 0 "DOME_LIGHT_REQUEST_NONE" ;
VAL_ 1193 UI_thirdRowLeftDomeLightRequest 1 "DOME_LIGHT_REQUEST_ACTIVE" 0 "DOME_LIGHT_REQUEST_NONE" ;
VAL_ 1193 UI_thirdRowRightDomeLightRequest 1 "DOME_LIGHT_REQUEST_ACTIVE" 0 "DOME_LIGHT_REQUEST_NONE" ;
VAL_ 853 UI_geofencedLiftgateHeight 255 "INVALID_SNA" 1 "USE_DEFAULT" 0 "PENDING_SAVE" ;
VAL_ 644 UI_factoryMode 1 "ENABLED" 0 "DISABLED" ;
VAL_ 644 UI_transportMode 1 "TRANSPORT_MODE_ENABLED" 0 "TRANSPORT_MODE_DISABLED" ;
VAL_ 644 UI_showroomMode 1 "SHOWROOM_MODE_ENABLED" 0 "SHOWROOM_MODE_DISABLED" ;
VAL_ 644 UI_serviceMode 1 "SERVICE_MODE_ENABLED" 0 "SERVICE_MODE_DISABLED" ;
VAL_ 644 UI_diagnosticsAllowed 1 "ALLOWED" 0 "NOT_ALLOWED" ;
VAL_ 644 UI_serviceModePlus 1 "SERVICE_MODE_PLUS_ENABLED" 0 "SERVICE_MODE_PLUS_DISABLED" ;
VAL_ 644 UI_signedCmdHardLocked 1 "ENABLED" 0 "DISABLED" ;
VAL_ 644 UI_signedCmdServiceMode 1 "ENABLED" 0 "DISABLED" ;
VAL_ 644 UI_closureEasterEggStatus 3 "PLAYING" 2 "PRIMED" 1 "PRIMED_REMOTE" 0 "IDLE" ;
VAL_ 644 UI_lightShowType 5 "LIGHT_SHOW_TYPE_STANDARD_CNY24" 4 "LIGHT_SHOW_TYPE_STANDARD_THE_ARRIVAL" 3 "LIGHT_SHOW_TYPE_STANDARD_CNY23" 2 "LIGHT_SHOW_TYPE_STANDARD_AULD_LANG_SYNE" 1 "LIGHT_SHOW_TYPE_STANDARD_CAROL_OF_THE_BELLS" 0 "LIGHT_SHOW_TYPE_CUSTOM_USB" ;
VAL_ 644 UI_upkeepMode 1 "UI_UPKEEPMODE_ENABLED" 0 "UI_UPKEEPMODE_DISABLED" ;
VAL_ 595 UI_ventPanelControlRequestIndex 1 "1" 0 "0" ;
VAL_ 595 UI_ventPanelLeftLateralMode 2 "SWING" 1 "SPLIT" 0 "SINGLE" ;
VAL_ 595 UI_ventPanelRightLateralMode 2 "SWING" 1 "SPLIT" 0 "SINGLE" ;
VAL_ 595 UI_hvacReqActiveVents 3 "OFF" 2 "RIGHT" 1 "LEFT" 0 "BOTH" ;
VAL_ 595 UI_hvacReqThirdRowState 2 "ON" 1 "OFF" 0 "AUTO" ;
VAL_ 1565 UI_weatherSvcTimeSinceLast 127 "SNA" ;
VAL_ 1565 UI_weatherSvcWindDir 255 "SNA" 240 "MAX" 0 "MIN" ;
VAL_ 1565 UI_weatherSvcTemperature 255 "SNA" 250 "MAX" 0 "MIN" ;
VAL_ 1565 UI_weatherSvcHumidity 63 "SNA" 62 "MAX" 0 "MIN" ;
VAL_ 1565 UI_weatherSvcDewPoint 255 "SNA" 250 "MAX" 0 "MIN" ;
VAL_ 1565 UI_weatherSvcCloudCover 63 "SNA" 62 "MAX" 0 "MIN" ;
VAL_ 1565 UI_weatherSvcPrecipProb 63 "SNA" 62 "MAX" 0 "MIN" ;
VAL_ 1565 UI_weatherSvcWindSpeed 63 "SNA" 60 "MAX" 0 "MIN" ;
VAL_ 1969 UI_weatherSvcForecastMuxIndex 4 "MUX4" 3 "MUX3" 2 "MUX2" 1 "MUX1" 0 "MUX0" ;
VAL_ 1969 UI_weatherSvcForecastTempC_hour1 255 "SNA" 250 "MAX" 0 "MIN" ;
VAL_ 1969 UI_weatherSvcForecastTempC_hour2 255 "SNA" 250 "MAX" 0 "MIN" ;
VAL_ 1969 UI_weatherSvcForecastTempC_hour3 255 "SNA" 250 "MAX" 0 "MIN" ;
VAL_ 1969 UI_weatherSvcForecastTempC_hour4 255 "SNA" 250 "MAX" 0 "MIN" ;
VAL_ 1969 UI_weatherSvcForecastTempC_hour5 255 "SNA" 250 "MAX" 0 "MIN" ;
VAL_ 1969 UI_weatherSvcForecastTempC_hour6 255 "SNA" 250 "MAX" 0 "MIN" ;
VAL_ 1969 UI_weatherSvcForecastTempC_hour7 255 "SNA" 250 "MAX" 0 "MIN" ;
VAL_ 1969 UI_weatherSvcForecastTempC_hour8 255 "SNA" 250 "MAX" 0 "MIN" ;
VAL_ 1969 UI_weatherSvcForecastTempC_hour9 255 "SNA" 250 "MAX" 0 "MIN" ;
VAL_ 1969 UI_weatherSvcForecastTempC__0001 255 "SNA" 250 "MAX" 0 "MIN" ;
VAL_ 1969 UI_weatherSvcForecastTempC__0002 255 "SNA" 250 "MAX" 0 "MIN" ;
VAL_ 1969 UI_weatherSvcForecastHumidity_ho 63 "SNA" 62 "MAX" 0 "MIN" ;
VAL_ 1969 UI_weatherSvcForecastHumidi_0003 63 "SNA" 62 "MAX" 0 "MIN" ;
VAL_ 1969 UI_weatherSvcForecastHumidi_0004 63 "SNA" 62 "MAX" 0 "MIN" ;
VAL_ 1969 UI_weatherSvcForecastHumidi_0005 63 "SNA" 62 "MAX" 0 "MIN" ;
VAL_ 1969 UI_weatherSvcForecastHumidi_0006 63 "SNA" 62 "MAX" 0 "MIN" ;
VAL_ 1969 UI_weatherSvcForecastHumidi_0007 63 "SNA" 62 "MAX" 0 "MIN" ;
VAL_ 1969 UI_weatherSvcForecastHumidi_0008 63 "SNA" 62 "MAX" 0 "MIN" ;
VAL_ 1969 UI_weatherSvcForecastHumidi_0009 63 "SNA" 62 "MAX" 0 "MIN" ;
VAL_ 1969 UI_weatherSvcForecastHumidi_0010 63 "SNA" 62 "MAX" 0 "MIN" ;
VAL_ 1969 UI_weatherSvcForecastHumidi_0001 63 "SNA" 62 "MAX" 0 "MIN" ;
VAL_ 1969 UI_weatherSvcForecastHumidi_0002 63 "SNA" 62 "MAX" 0 "MIN" ;
VAL_ 1969 UI_weatherSvcForecastWindSpeedKp 63 "SNA" 60 "MAX" 0 "MIN" ;
VAL_ 1969 UI_weatherSvcForecastWindSp_0003 63 "SNA" 60 "MAX" 0 "MIN" ;
VAL_ 1969 UI_weatherSvcForecastWindSp_0004 63 "SNA" 60 "MAX" 0 "MIN" ;
VAL_ 1969 UI_weatherSvcForecastWindSp_0005 63 "SNA" 60 "MAX" 0 "MIN" ;
VAL_ 1969 UI_weatherSvcForecastWindSp_0006 63 "SNA" 60 "MAX" 0 "MIN" ;
VAL_ 1969 UI_weatherSvcForecastWindSp_0007 63 "SNA" 60 "MAX" 0 "MIN" ;
VAL_ 1969 UI_weatherSvcForecastWindSp_0008 63 "SNA" 60 "MAX" 0 "MIN" ;
VAL_ 1969 UI_weatherSvcForecastWindSp_0009 63 "SNA" 60 "MAX" 0 "MIN" ;
VAL_ 1969 UI_weatherSvcForecastWindSp_0010 63 "SNA" 60 "MAX" 0 "MIN" ;
VAL_ 1969 UI_weatherSvcForecastWindSp_0001 63 "SNA" 60 "MAX" 0 "MIN" ;
VAL_ 1969 UI_weatherSvcForecastWindSp_0002 63 "SNA" 60 "MAX" 0 "MIN" ;
VAL_ 1533 UMC_alertID 42 "a042_GFCICalRelayDelta" 41 "a041_handleTempIrrational" 40 "a040_gndDisconnected" 39 "a039_inputOverCurrent" 38 "a038_chcVitalsFault" 37 "a037_GFCICalibration" 35 "a035_v2lHVACDetected" 34 "a034_v2lSAUnsupported" 33 "a033_chcUpdateFault" 32 "a032_chcVitalsRequestFailure" 31 "a031_relayCoilVIrrational" 30 "a030_acLostPllLock" 29 "a029_acPowerLoss" 28 "a028_processorBooted" 27 "a027_watchdogExpired" 26 "a026_vRefOutOfRange" 25 "a025_cntrOpenExpectedClose" 24 "a024_gndResistanceHigh" 23 "a023_adcSelfTest" 22 "a022_criticalRAM" 21 "a021_dataBus" 20 "a020_applicationCRC" 19 "a019_inputOTFoldback" 18 "a018_vehConnOTFoldback" 17 "a017_wallPlugOTFoldback" 16 "a016_pcbaOTFoldback" 15 "a015_SA_Connection" 14 "a014_SA_Genealogy" 13 "a013_SA_Temperature" 12 "a012_pilotFault" 11 "a011_proxDisconnected" 10 "a010_inputOT" 9 "a009_vehConnOT" 8 "a008_wallPlugOT" 7 "a007_pcbaOT" 6 "a006_contactorWelded" 5 "a005_inputUnderVoltage" 4 "a004_inputOverVoltage" 3 "a003_GFCISelfTestFault" 2 "a002_GFCITripped" 1 "a001_gndMonIntrptLineSide" 0 "ALERT_DO_NOT_USE_ZERO" ;
VAL_ 1533 UMC_alertType 1 "SET" 0 "CLEARED" ;
VAL_ 1533 UMC_a002_ccidFaultReason 4 "DC_PEAK" 3 "DC_LPF" 2 "AC_PEAK" 1 "AC_LPF" 0 "SNA" ;
VAL_ 1533 UMC_a003_faultType 1 "SELFTEST" 0 "POWERON" ;
VAL_ 1533 UMC_a006_faultType 1 "OPENED" 0 "WELDED" ;
VAL_ 1533 UMC_a018_vehConnTemp 215 "SHORTED" 214 "OPENED" ;
VAL_ 1533 UMC_a019_inputTerminalsTemp 215 "SHORTED" 214 "OPENED" ;
VAL_ 1285 SA_infoIndex 32 "Mux32" 31 "Mux31" 30 "Mux30" 29 "Mux29" 27 "Mux27" 26 "Mux26" 25 "Mux25" 11 "Mux11" 0 "Mux0" ;
VAL_ 1285 SA_region 6 "SA_REGION_INDIA" 5 "SA_REGION_SOUTH_KOREA" 4 "SA_REGION_AUSTRALIA" 3 "SA_REGION_JAPAN" 2 "SA_REGION_CHINA" 1 "SA_REGION_EU" 0 "SA_REGION_NA" ;
VAL_ 1949 V2G_evseLogDataSelect 17 "NUM_MSG" 16 "MSG_NONE" 15 "SESSION_STOP" 14 "WELDING_DETECTION" 13 "POWER_DELIVERY_END" 12 "CHARGING_STATUS" 11 "CURRENT_DEMAND" 10 "POWER_DELIVERY_START" 9 "PRECHARGE" 8 "CABLE_CHECK" 7 "CHARGE_PARAMETER_DISCOVERY" 6 "CONTRACT_AUTHENTICATION" 5 "PAYMENT_DETAILS" 4 "SERVICE_PAYMENT_SELECTION" 3 "SERVICE_DETAIL" 2 "SERVICE_DISCOVERY" 1 "SESSION_SETUP" 0 "SUPPORTED_APP_PROTOCOL" ;
VAL_ 1949 V2G_chgParamRes_respCode 27 "CCS_EVSE_RESP_CODE_MAX" 26 "CCS_EVSE_RESP_CODE_FAILED_CERT_REVOKED" 25 "CCS_EVSE_RESP_CODE_FAILED_CERT_NOT_ALLOWED_AT_EVSE" 24 "CCS_EVSE_RESP_CODE_FAILED_CONTACTOR_ERROR" 23 "CCS_EVSE_RESP_CODE_FAILED_NO_CHARGE_SERVICE_SELECTED" 22 "CCS_EVSE_RESP_CODE_FAILED_WRONG_ENERGY_TRANSFER_TYPE" 21 "CCS_EVSE_RESP_CODE_FAILED_METERING_SIGNATURE_NOT_VALID" 20 "CCS_EVSE_RESP_CODE_FAILED_EVSE_PRESENT_VOLTAGE_TOO_LOW" 19 "CCS_EVSE_RESP_CODE_FAILED_CHARGING_PROFILE_INVALID" 18 "CCS_EVSE_RESP_CODE_FAILED_TARIFF_SELECTION_INVALID" 17 "CCS_EVSE_RESP_CODE_FAILED_POWER_DELIVERY_NOT_APPLIED" 16 "CCS_EVSE_RESP_CODE_FAILED_WRONG_CHARGE_PARAMETER" 15 "CCS_EVSE_RESP_CODE_FAILED_CONTRACT_CANCELED" 14 "CCS_EVSE_RESP_CODE_FAILED_CHALLENGE_INVALID" 13 "CCS_EVSE_RESP_CODE_FAILED_CERT_CHAIN_ERROR" 12 "CCS_EVSE_RESP_CODE_FAILED_NO_CERTIFICATE_AVAILABLE" 11 "CCS_EVSE_RESP_CODE_FAILED_SIGNATURE_ERROR" 10 "CCS_EVSE_RESP_CODE_FAILED_CERTIFICATE_EXPIRED" 9 "CCS_EVSE_RESP_CODE_FAILED_PAYMENT_SELECTION_INVALID" 8 "CCS_EVSE_RESP_CODE_FAILED_SERVICE_SELECTION_INVALID" 7 "CCS_EVSE_RESP_CODE_FAILED_UNKNOWN_SESSION" 6 "CCS_EVSE_RESP_CODE_FAILED_SERVICE_ID_INVALID" 5 "CCS_EVSE_RESP_CODE_FAILED_SEQUENCE_ERROR" 4 "CCS_EVSE_RESP_CODE_FAILED" 3 "CCS_EVSE_RESP_CODE_OK_CERTIFICATE_EXPIRES_SOON" 2 "CCS_EVSE_RESP_CODE_OK_OLD_SESSION_JOINED" 1 "CCS_EVSE_RESP_CODE_OK_NEW_SESSION_ESTABLISHED" 0 "CCS_EVSE_RESP_CODE_OK" ;
VAL_ 1949 V2G_chgParamRes_evseStatus 12 "CCS_DC_EVSE_STATUS_MAX" 11 "CCS_DC_EVSE_STATUS_RESERVED_C" 10 "CCS_DC_EVSE_STATUS_RESERVED_B" 9 "CCS_DC_EVSE_STATUS_RESERVED_A" 8 "CCS_DC_EVSE_STATUS_RESERVED_9" 7 "CCS_DC_EVSE_STATUS_RESERVED_8" 6 "CCS_DC_EVSE_STATUS_MALFUNCTION" 5 "CCS_DC_EVSE_STATUS_EMERGENCY_SHUTDOWN" 4 "CCS_DC_EVSE_STATUS_ISOLATION_MONITORING_ACTIVE" 3 "CCS_DC_EVSE_STATUS_UTILITY_INTERRUPT_EVENT" 2 "CCS_DC_EVSE_STATUS_SHUTDOWN" 1 "CCS_DC_EVSE_STATUS_READY" 0 "CCS_DC_EVSE_STATUS_NOT_READY" ;
VAL_ 1949 V2G_chgParamRes_isoState 4 "CCS_ISOLATION_STATUS_NO_IMD" 3 "CCS_ISOLATION_STATUS_FAULT" 2 "CCS_ISOLATION_STATUS_WARNING" 1 "CCS_ISOLATION_STATUS_VALID" 0 "CCS_ISOLATION_STATUS_INVALID" ;
VAL_ 1338 VCBATT0_alertID 423 "a423_rtosSleepFailed" 64 "a064_busSleepReqTimeout" 63 "a063_SwitchFault" 62 "a062_XCPWasConnected" 61 "a061_XCPConnected" 60 "a060_engineeringBuild" 59 "a059_inputResistanceHigh" 58 "a058_inputRHighSyncDebug" 47 "a047_resetReason" 46 "a046_Task1000msError" 45 "a045_Task100msError" 44 "a044_Task10msError" 43 "a043_Task1msError" 42 "a042_HighStackUsage" 41 "a041_HighCPULoad" 40 "a040_Backtrace" 39 "a039_ProtFaultAddress" 38 "a038_ProtFaultInfo" 33 "a033_eccNonCorrectableError" 32 "a032_ipcWatchdogExpired" 31 "a031_UDSActive" 30 "a030_ECULogUploadRequest" 29 "a029_CoreDump" 22 "a022_TaskInitError" 21 "a021_TaskSchedulerError" 16 "a016_NVMMRecordError" 15 "a015_NVMMError" 13 "a013_AlertManagerFault" 12 "a012_CPUReset" 6 "a006_CANTX_cyclicError" 5 "a005_CANTXError" 3 "a003_SWAssertion" 2 "a002_PowerLossReset" 1 "a001_WatchdogReset" 0 "ALERT_DO_NOT_USE_ZERO" ;
VAL_ 1338 VCBATT0_alertState 1 "SET" 0 "CLEARED" ;
VAL_ 973 VCBATT0_matrixIndex 7 "AlertMatrix7" 1 "AlertMatrix1" 0 "AlertMatrix0" ;
VAL_ 1858 VCBATT1_lvbmsStatusHighIndex 5 "INVALID" 4 "CELL_VITALS_2_AND_STATE_AND_COMMANDS" 3 "TARGETS" 2 "PCS_INTERFACE" 1 "CELL_VITALS_1" 0 "PACK_VITALS_1" ;
VAL_ 1858 VCBATT1_LVBMS_packCurrent 4194303 "SNA" ;
VAL_ 1858 VCBATT1_LVBMS_packVoltage 65535 "SNA" ;
VAL_ 1858 VCBATT1_LVBMS_packTemperature 511 "SNA" ;
VAL_ 1858 VCBATT1_LVBMS_MOSTemperature 4095 "SNA" ;
VAL_ 1858 VCBATT1_LVBMS_sumCellVoltage 65535 "SNA" 65534 "INVALID" ;
VAL_ 1858 VCBATT1_LVBMS_maxBrickVoltage 8191 "SNA" ;
VAL_ 1858 VCBATT1_LVBMS_maxBrickVoltageInd 255 "SNA" ;
VAL_ 1858 VCBATT1_LVBMS_voltageTarget 65535 "SNA" ;
VAL_ 1858 VCBATT1_LVBMS_currentTarget 262143 "SNA" ;
VAL_ 1858 VCBATT1_LVBMS_maxAllowedChargeCu 8191 "SNA" ;
VAL_ 1858 VCBATT1_LVBMS_maxAllowedDischarg 8191 "SNA" ;
VAL_ 1858 VCBATT1_LVBMS_ECPAState 3 "LVBMS_ECPA_STATE_SNA" 2 "LVBMS_ECPA_STATE_INVALID" 1 "LVBMS_ECPA_STATE_CLOSED" 0 "LVBMS_ECPA_STATE_OPEN" ;
VAL_ 1858 VCBATT1_LVBMS_MOSState 3 "LVBMS_MOS_STATE_SNA" 2 "LVBMS_MOS_STATE_INVALID" 1 "LVBMS_MOS_STATE_CLOSED" 0 "LVBMS_MOS_STATE_OPEN" ;
VAL_ 1858 VCBATT1_LVBMS_VehicleState 3 "LVBMS_VEHICLE_STATE_OFF" 2 "LVBMS_VEHICLE_STATE_CONDITIONING" 1 "LVBMS_VEHICLE_STATE_ACCESSORY" 0 "LVBMS_VEHICLE_STATE_DRIVE" ;
VAL_ 1858 VCBATT1_LVBMS_LINWakeDisabled 1 "LVBMS_LIN_WAKE_DISABLED" 0 "LVBMS_LIN_WAKE_ENABLED" ;
VAL_ 1858 VCBATT1_LVBMS_chargeType 4 "LVBMS_CHARGE_SNA" 3 "LVBMS_CHARGE_COMPLETE" 2 "LVBMS_CHARGE_CONSTANT_VOLTAGE" 1 "LVBMS_CHARGE_CONSTANT_CURRENT" 0 "LVBMS_CHARGE_UNDEFINED" ;
VAL_ 1858 VCBATT1_LVBMS_avgBrickVoltage 8191 "SNA" ;
VAL_ 1858 VCBATT1_LVBMS_minBrickVoltage 8191 "SNA" ;
VAL_ 1858 VCBATT1_LVBMS_minBrickVoltageInd 255 "SNA" ;
VAL_ 1119 VCBATT1_LVSelfTestsIndex 1 "STATES" 0 "ORCHESTRATOR" ;
VAL_ 1119 VCBATT1_battDomainOvercurrentSel 2 "VC_SELF_TEST_RESULT_PASSED" 1 "VC_SELF_TEST_RESULT_FAILED" 0 "VC_SELF_TEST_RESULT_INVALID" ;
VAL_ 1119 VCBATT1_battDomainOvercurre_0001 4 "VC_SELF_TEST_STATE_SNA" 3 "VC_SELF_TEST_STATE_NEW_RESULT" 2 "VC_SELF_TEST_STATE_RUNNING" 1 "VC_SELF_TEST_STATE_PENDING" 0 "VC_SELF_TEST_STATE_IDLE" ;
VAL_ 1119 VCBATT1_battDomainOvervoltageSel 2 "VC_SELF_TEST_RESULT_PASSED" 1 "VC_SELF_TEST_RESULT_FAILED" 0 "VC_SELF_TEST_RESULT_INVALID" ;
VAL_ 1119 VCBATT1_battDomainOvervolta_0001 4 "VC_SELF_TEST_STATE_SNA" 3 "VC_SELF_TEST_STATE_NEW_RESULT" 2 "VC_SELF_TEST_STATE_RUNNING" 1 "VC_SELF_TEST_STATE_PENDING" 0 "VC_SELF_TEST_STATE_IDLE" ;
VAL_ 1119 VCBATT1_battDomainUndervoltageSe 2 "VC_SELF_TEST_RESULT_PASSED" 1 "VC_SELF_TEST_RESULT_FAILED" 0 "VC_SELF_TEST_RESULT_INVALID" ;
VAL_ 1119 VCBATT1_battDomainUndervolt_0001 4 "VC_SELF_TEST_STATE_SNA" 3 "VC_SELF_TEST_STATE_NEW_RESULT" 2 "VC_SELF_TEST_STATE_RUNNING" 1 "VC_SELF_TEST_STATE_PENDING" 0 "VC_SELF_TEST_STATE_IDLE" ;
VAL_ 1119 VCBATT1_dualPowerLoadsSelfTestRe 2 "VC_SELF_TEST_RESULT_PASSED" 1 "VC_SELF_TEST_RESULT_FAILED" 0 "VC_SELF_TEST_RESULT_INVALID" ;
VAL_ 1119 VCBATT1_dualPowerLoadsSelfTestSt 4 "VC_SELF_TEST_STATE_SNA" 3 "VC_SELF_TEST_STATE_NEW_RESULT" 2 "VC_SELF_TEST_STATE_RUNNING" 1 "VC_SELF_TEST_STATE_PENDING" 0 "VC_SELF_TEST_STATE_IDLE" ;
VAL_ 1119 VCBATT1_vcbattBridgeEFuseASICSel 2 "VC_SELF_TEST_RESULT_PASSED" 1 "VC_SELF_TEST_RESULT_FAILED" 0 "VC_SELF_TEST_RESULT_INVALID" ;
VAL_ 1119 VCBATT1_vcbattBridgeEFuseAS_0001 4 "VC_SELF_TEST_STATE_SNA" 3 "VC_SELF_TEST_STATE_NEW_RESULT" 2 "VC_SELF_TEST_STATE_RUNNING" 1 "VC_SELF_TEST_STATE_PENDING" 0 "VC_SELF_TEST_STATE_IDLE" ;
VAL_ 1119 VCBATT1_uvProtectionState 12 "VC_UV_STATE_DELIBERATELY_TRIPPED" 11 "VC_UV_STATE_TRIPPED" 10 "VC_UV_STATE_ARMED" 9 "VC_UV_STATE_SELF_TEST_CLEAN_UP" 8 "VC_UV_STATE_SELF_TEST_CHECK_STUCK_ON" 7 "VC_UV_STATE_SELF_TEST_CHECK_STUCK_OFF_COMPLETE" 6 "VC_UV_STATE_SELF_TEST_CHECK_STUCK_OFF" 5 "VC_UV_STATE_SELF_TEST_LOADS_GOING_DOWN_COMPLETE" 4 "VC_UV_STATE_SELF_TEST_LOADS_GOING_DOWN" 3 "VC_UV_STATE_SELF_TEST_LOADS_ON" 2 "VC_UV_STATE_SELF_TEST_TURN_ON_LOADS" 1 "VC_UV_STATE_SELF_TEST_SETUP" 0 "VC_UV_STATE_IDLE" ;
VAL_ 1119 VC_selfTestsRunningMode 4 "DISABLED" 3 "REDUCED" 2 "FACTORY_REDUCED" 1 "FACTORY_NORMAL" 0 "NORMAL" ;
